BU_:  Airbag BAP_Tester ICAS1_Gateway ICAS1_KommunikationsServer LE1 LE2 Motor_BEV Schaltbetaetigung

BU_:  Airbag BAP_Tester ICAS1_Gateway ICAS1_KommunikationsServer LE1 LE2 Motor_BEV Schaltbetaetigung

BO_ 967 Motor_26: 8 Motor_BEV
 SG_ MO_Kuehlerluefter_MUX M : 0|1@1+ (1.000000,0.000000) [0.000000|1.000000] "siema ooo" ICAS1_Gateway
 SG_ MO_Kuehlerluefter_1 m0 : 1|7@1+ (1.000000,0.000000) [0.000000|100.000000] "Unit_PerCent" ICAS1_Gateway
 SG_ MO_Kuehlerluefter_2 m1 : 1|7@1+ (1.000000,0.000000) [0.000000|100.000000] "Unit_PerCent" ICAS1_Gateway
 SG_ MO_EFLEX_Lampe  : 8|2@1+ (1.000000,0.000000) [0.000000|3.000000] "" ICAS1_Gateway
 SG_ MO_KJS_nicht_bereit  : 10|1@1+ (1.000000,0.000000) [0.000000|1.000000] "" ICAS1_Gateway
 SG_ MO_ITM_Warnung_Pumpe  : 11|1@1+ (1.000000,0.000000) [0.000000|1.000000] "" ICAS1_Gateway
 SG_ WIV_Anzeige_aktiv  : 12|1@1+ (1.000000,0.000000) [0.000000|1.000000] "" ICAS1_Gateway
 SG_ WIV_Oelmin_Warn  : 13|1@1+ (1.000000,0.000000) [0.000000|1.000000] "" ICAS1_Gateway
 SG_ WIV_Sensorfehler  : 14|1@1+ (1.000000,0.000000) [0.000000|1.000000] "" ICAS1_Gateway
 SG_ WIV_Schieflage  : 15|1@1+ (1.000000,0.000000) [0.000000|1.000000] "" ICAS1_Gateway
 SG_ WIV_Oelstand  : 16|4@1+ (12.500000,0.000000) [0.000000|100.000000] "Unit_PerCent" ICAS1_Gateway
 SG_ MO_Zustand_HWP  : 20|2@1+ (1.000000,0.000000) [0.000000|3.000000] "" ICAS1_Gateway
 SG_ OLEV_Systemstoerung  : 22|1@1+ (1.000000,0.000000) [0.000000|1.000000] "" ICAS1_Gateway
 SG_ MO_Oelwarnung_max  : 23|1@1+ (1.000000,0.000000) [0.000000|1.000000] "" ICAS1_Gateway
 SG_ WIV_Oelsystem_aktiv  : 24|1@1+ (1.000000,0.000000) [0.000000|1.000000] "" ICAS1_Gateway
 SG_ WIV_nicht_betriebswarm  : 25|1@1+ (1.000000,0.000000) [0.000000|1.000000] "" ICAS1_Gateway
 SG_ WIV_Ueberfuell_Warn  : 26|1@1+ (1.000000,0.000000) [0.000000|1.000000] "" ICAS1_Gateway
 SG_ WIV_laufender_Motor  : 27|1@1+ (1.000000,0.000000) [0.000000|1.000000] "" ICAS1_Gateway
 SG_ MO_E_Warnungen  : 28|4@1+ (1.000000,0.000000) [0.000000|15.000000] "" ICAS1_Gateway
 SG_ MO_Text_Motorstart  : 32|4@1+ (1.000000,0.000000) [0.000000|15.000000] "" ICAS1_Gateway
 SG_ MO_E_Texte  : 36|4@1+ (1.000000,0.000000) [0.000000|15.000000] "" ICAS1_Gateway
 SG_ WIV_Oeldyn_avl  : 40|1@1+ (1.000000,0.000000) [0.000000|1.000000] "" ICAS1_Gateway
 SG_ MO_Text_Partikelfil_Reg  : 41|1@1+ (1.000000,0.000000) [0.000000|1.000000] "" ICAS1_Gateway
 SG_ OLEV_Oelstand_nicht_vorhanden  : 42|1@1+ (1.000000,0.000000) [0.000000|1.000000] "" ICAS1_Gateway
 SG_ WIV_Oelmenge  : 43|5@1+ (125.000000,0.000000) [0.000000|3875.000000] "Unit_MilliLiter" ICAS1_Gateway
 SG_ MO_Systemlampe  : 48|1@1+ (1.000000,0.000000) [0.000000|1.000000] "" ICAS1_Gateway
 SG_ MO_OBD2_Lampe  : 49|1@1+ (1.000000,0.000000) [0.000000|1.000000] "" ICAS1_Gateway
 SG_ MO_Heissleuchte  : 50|1@1+ (1.000000,0.000000) [0.000000|1.000000] "" ICAS1_Gateway
 SG_ MO_Partikel_Lampe  : 51|1@1+ (1.000000,0.000000) [0.000000|1.000000] "" ICAS1_Gateway
 SG_ MO_RedFahrleistung_Lampe  : 52|1@1+ (1.000000,0.000000) [0.000000|1.000000] "" ICAS1_Gateway ICAS1_KommunikationsServer
 SG_ WIV_Oelstand_nicht_vorhanden  : 53|1@1+ (1.000000,0.000000) [0.000000|1.000000] "" ICAS1_Gateway
 SG_ WIV_nachfuellanzeige_ein  : 54|1@1+ (1.000000,0.000000) [0.000000|1.000000] "" ICAS1_Gateway
 SG_ WIV_Ueberfuell_deaktiv  : 55|1@1+ (1.000000,0.000000) [0.000000|1.000000] "" ICAS1_Gateway
 SG_ WIV_Unterfuell_Warn  : 56|1@1+ (1.000000,0.000000) [0.000000|1.000000] "" ICAS1_Gateway
 SG_ MO_Tankdeckel_Lampe  : 57|1@1+ (1.000000,0.000000) [0.000000|1.000000] "" ICAS1_Gateway
 SG_ MO_Text_Tankdeckelwarn  : 58|1@1+ (1.000000,0.000000) [0.000000|1.000000] "" ICAS1_Gateway
 SG_ MO_Vorglueh_Lampe  : 59|1@1+ (1.000000,0.000000) [0.000000|1.000000] "" ICAS1_Gateway
 SG_ WIV_Oeldr_Warn_Motor  : 60|1@1+ (1.000000,0.000000) [0.000000|1.000000] "" ICAS1_Gateway
 SG_ MO_E_Mode  : 61|3@1+ (1.000000,0.000000) [0.000000|7.000000] "" ICAS1_Gateway

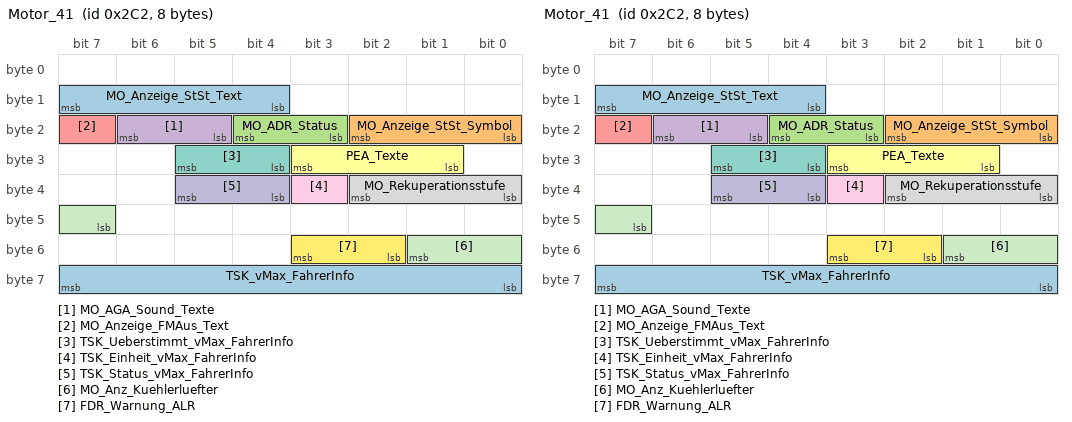
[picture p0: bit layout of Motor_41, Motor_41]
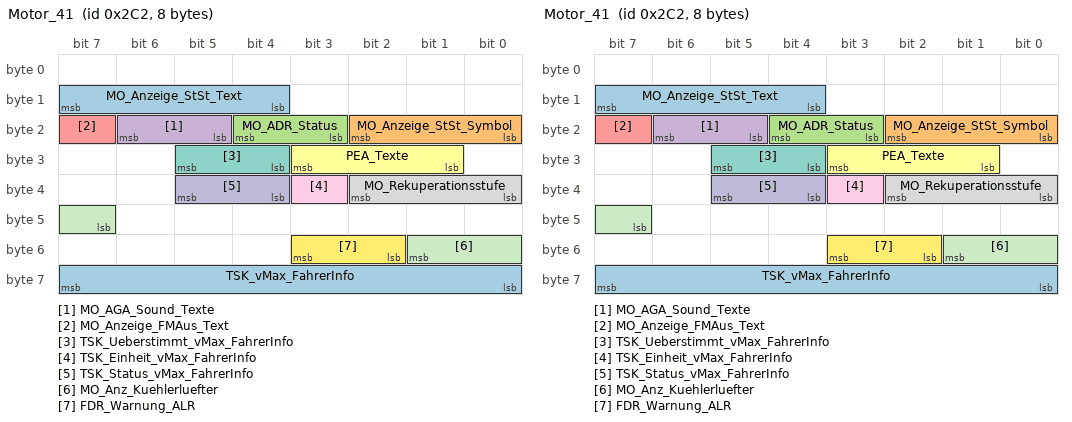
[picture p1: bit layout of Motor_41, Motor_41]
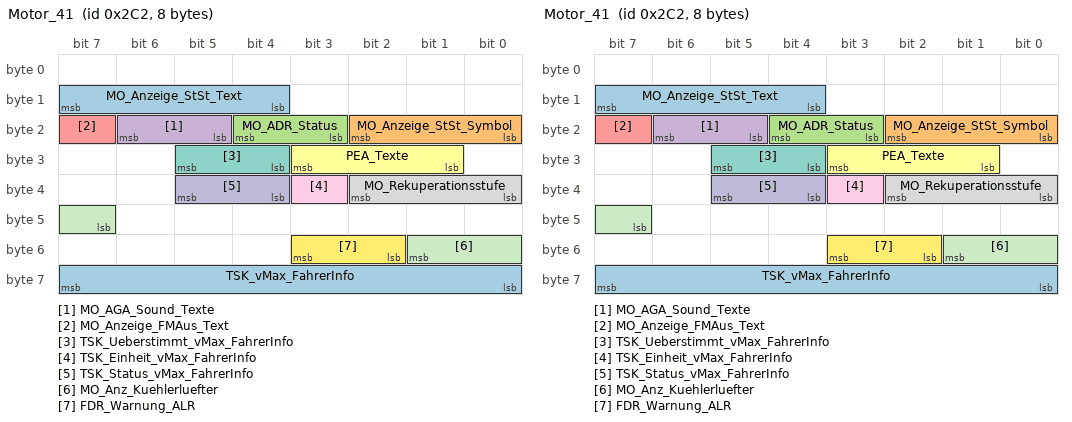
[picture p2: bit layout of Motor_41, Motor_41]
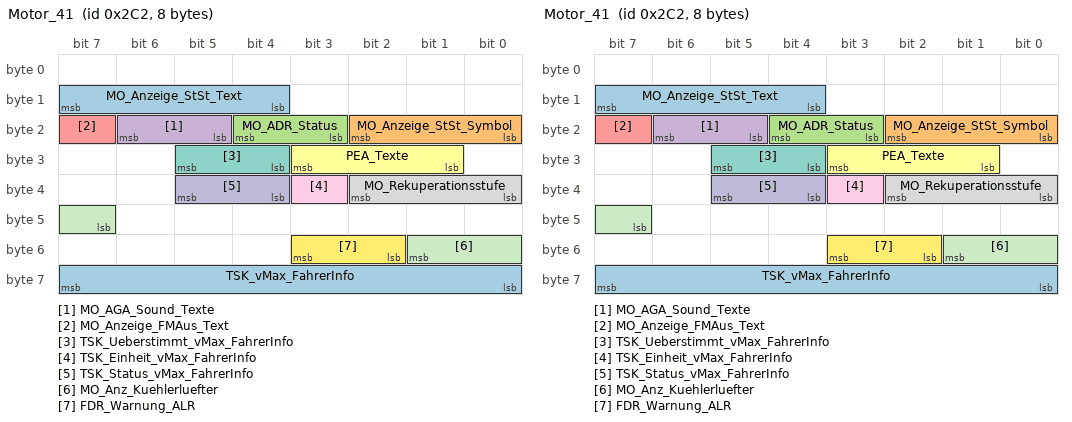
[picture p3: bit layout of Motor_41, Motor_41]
BO_ 706 Motor_41: 8 Motor_BEV
 SG_ MO_Anzeige_StSt_Text  : 12|4@1+ (1.000000,0.000000) [0.000000|15.000000] "" Vector__XXX
 SG_ MO_Anzeige_StSt_Symbol  : 16|3@1+ (1.000000,0.000000) [0.000000|7.000000] "" Vector__XXX
 SG_ MO_ADR_Status  : 19|2@1+ (1.000000,0.000000) [0.000000|3.000000] "" Vector__XXX
 SG_ MO_AGA_Sound_Texte  : 21|2@1+ (1.000000,0.000000) [0.000000|3.000000] "" Vector__XXX
 SG_ MO_Anzeige_FMAus_Text  : 23|1@1+ (1.000000,0.000000) [0.000000|1.000000] "" Vector__XXX
 SG_ PEA_Texte  : 25|3@1+ (1.000000,0.000000) [0.000000|7.000000] "" Vector__XXX
 SG_ TSK_Ueberstimmt_vMax_FahrerInfo  : 28|2@1+ (1.000000,0.000000) [0.000000|3.000000] "" Vector__XXX
 SG_ MO_Rekuperationsstufe  : 32|3@1+ (1.000000,0.000000) [0.000000|7.000000] "" ICAS1_KommunikationsServer
 SG_ TSK_Einheit_vMax_FahrerInfo  : 35|1@1+ (1.000000,0.000000) [0.000000|1.000000] "" ICAS1_KommunikationsServer
 SG_ TSK_Status_vMax_FahrerInfo  : 36|2@1+ (1.000000,0.000000) [0.000000|3.000000] "" ICAS1_KommunikationsServer
 SG_ MO_Anz_Kuehlerluefter  : 47|3@1+ (1.000000,0.000000) [0.000000|7.000000] "" Vector__XXX
 SG_ FDR_Warnung_ALR  : 50|2@1+ (1.000000,0.000000) [0.000000|3.000000] "" ICAS1_KommunikationsServer
 SG_ TSK_vMax_FahrerInfo  : 56|8@1+ (1.000000,15.000000) [16.000000|270.000000] "" ICAS1_KommunikationsServer

BO_ 267 Motor_51: 32 Motor_BEV
 SG_ Motor_51_CRC  : 0|8@1+ (1.000000,0.000000) [0.000000|255.000000] "" ICAS1_Gateway
 SG_ Motor_51_BZ  : 8|4@1+ (1.000000,0.000000) [0.000000|15.000000] "" ICAS1_Gateway
 SG_ MO_Fahrpedalrohwert_01  : 12|8@1+ (0.400000,0.000000) [0.000000|101.600000] "Unit_PerCent" Airbag ICAS1_Gateway
 SG_ MO_QBit_Fahrpedalwerte_01  : 20|1@1+ (1.000000,0.000000) [0.000000|1.000000] "" Airbag ICAS1_Gateway
 SG_ MO_Fahrpedalgradient  : 21|8@1+ (25.000000,0.000000) [0.000000|6350.000000] "Unit_PerCentPerSecon" ICAS1_Gateway
 SG_ MO_Sig_Fahrpedalgradient  : 29|1@1+ (1.000000,0.000000) [0.000000|1.000000] "" ICAS1_Gateway
 SG_ MO_rel_Saugrohrdruck  : 30|6@1+ (18.000000,0.000000) [0.000000|1116.000000] "Unit_MilliBar" ICAS1_Gateway
 SG_ MO_rel_Saugrohrdruck_gem_err  : 36|1@1+ (1.000000,0.000000) [0.000000|1.000000] "" ICAS1_Gateway
 SG_ MO_Moment_im_Leerlauf  : 37|1@1+ (1.000000,0.000000) [0.000000|1.000000] "" ICAS1_Gateway
 SG_ MO_Schubabschaltung  : 38|1@1+ (1.000000,0.000000) [0.000000|1.000000] "" ICAS1_Gateway
 SG_ MO_Solldrehz_Leerlauf  : 40|8@1+ (10.000000,0.000000) [0.000000|2540.000000] "Unit_MinutInver" ICAS1_Gateway
 SG_ MO_Entkopplung_Sollschlupf  : 48|7@1+ (20.000000,0.000000) [0.000000|2480.000000] "Unit_MinutInver" ICAS1_Gateway
 SG_ MO_temporaere_Fahrerabwesenheit  : 55|1@1+ (1.000000,0.000000) [0.000000|1.000000] "" ICAS1_Gateway
 SG_ TSK_a_Soll_gradientenbegrenzt  : 57|7@1+ (0.100000,-7.200000) [-7.200000|5.400000] "Unit_MeterPerSeconSquar" ICAS1_Gateway
 SG_ TSK_Radbremsmom  : 76|12@1+ (8.000000,0.000000) [0.000000|32760.000000] "Unit_NewtoMeter" ICAS1_Gateway
 SG_ TSK_Status  : 88|3@1+ (1.000000,0.000000) [0.000000|7.000000] "" ICAS1_Gateway
 SG_ TSK_v_Begrenzung_aktiv  : 91|1@1+ (1.000000,0.000000) [0.000000|1.000000] "" ICAS1_Gateway
 SG_ TSK_Standby_Anf_ESP  : 92|1@1+ (1.000000,0.000000) [0.000000|1.000000] "" ICAS1_Gateway
 SG_ TSK_Freig_WU  : 93|1@1+ (1.000000,0.000000) [0.000000|1.000000] "" ICAS1_Gateway
 SG_ TSK_Freig_Verzoeg_Anf  : 94|1@1+ (1.000000,0.000000) [0.000000|1.000000] "" ICAS1_Gateway
 SG_ TSK_Limiter_ausgewaehlt  : 95|1@1+ (1.000000,0.000000) [0.000000|1.000000] "" ICAS1_Gateway
 SG_ TSK_Wunsch_Uebersetz  : 96|10@1+ (0.024500,0.000000) [0.024500|25.063500] "" ICAS1_Gateway
 SG_ TSK_Hauptschalter_GRA_ACC  : 106|2@1+ (1.000000,0.000000) [0.000000|3.000000] "" ICAS1_Gateway ICAS1_KommunikationsServer
 SG_ TSK_SRBM_Anf_ASIL  : 108|3@1+ (1.000000,0.000000) [0.000000|7.000000] "" ICAS1_Gateway
 SG_ TSK_ax_Getriebe_02  : 112|9@1+ (0.024000,-2.016000) [-2.016000|10.224000] "Unit_MeterPerSeconSquar" ICAS1_Gateway
 SG_ TSK_Zwangszusch_ESP  : 121|1@1+ (1.000000,0.000000) [0.000000|1.000000] "" ICAS1_Gateway
 SG_ TSK_zul_Regelabw  : 122|6@1+ (0.024000,0.000000) [0.000000|1.512000] "Unit_MeterPerSeconSquar" ICAS1_Gateway
 SG_ MO_Status_MinDrzEingriff  : 235|3@1+ (1.000000,0.000000) [0.000000|7.000000] "" ICAS1_Gateway
 SG_ MO_Status_MaxDrzEingriff  : 238|3@1+ (1.000000,0.000000) [0.000000|7.000000] "" ICAS1_Gateway
 SG_ MO_Status_MinDrzEingriff_sek  : 241|3@1+ (1.000000,0.000000) [0.000000|7.000000] "" ICAS1_Gateway
 SG_ MO_Status_MaxDrzEingriff_sek  : 244|3@1+ (1.000000,0.000000) [0.000000|7.000000] "" ICAS1_Gateway
 SG_ GRA_KuFu_aktiv  : 247|1@1+ (1.000000,0.000000) [0.000000|1.000000] "" ICAS1_Gateway
 SG_ TSK_SRBM_max_Gradient  : 248|7@1+ (50.000000,0.000000) [0.000000|6250.000000] "Unit_NewtoMeterPerSecon" ICAS1_Gateway
 SG_ LIM_KuFu_aktiv  : 255|1@1+ (1.000000,0.000000) [0.000000|1.000000] "" ICAS1_Gateway

BO_ 330 Motor_52: 32 Motor_BEV
 SG_ MO_Hochschaltdrehz  : 21|12@1+ (3.000000,0.000000) [3.000000|12282.000000] "Unit_MinutInver" Vector__XXX
 SG_ MO_Anzeige_Verbr_Einheit  : 33|2@1+ (1.000000,0.000000) [0.000000|3.000000] "" Vector__XXX
 SG_ MO_Schaltblitz_Anz  : 35|7@1+ (1.000000,0.000000) [0.000000|100.000000] "Unit_PerCent" Vector__XXX
 SG_ MO_Anzeige_Drehmoment  : 42|11@1+ (1.000000,0.000000) [0.000000|2045.000000] "Unit_NewtoMeter" Vector__XXX
 SG_ MO_Anzeige_Leistung  : 53|11@1+ (0.600000,0.000000) [0.000000|1227.000000] "Unit_KiloWatt" Vector__XXX
 SG_ MO_rel_Ladedruck  : 64|8@1+ (0.400000,0.000000) [0.000000|100.000000] "Unit_PerCent" Vector__XXX
 SG_ MO_Istgang  : 72|4@1+ (1.000000,0.000000) [0.000000|15.000000] "" Vector__XXX
 SG_ MO_Sollgang  : 76|4@1+ (1.000000,0.000000) [0.000000|15.000000] "" Vector__XXX
 SG_ MO_Oeldruck  : 80|8@1+ (0.040000,0.000000) [0.000000|10.000000] "Unit_Bar" Vector__XXX
 SG_ MO_Anzeigedrehz  : 88|12@1+ (3.000000,0.000000) [0.000000|12282.000000] "Unit_MinutInver" Vector__XXX
 SG_ MO_Effizienzmodus  : 100|1@1+ (1.000000,0.000000) [0.000000|1.000000] "" Vector__XXX
 SG_ MO_Fehler_Oeldrucksensor  : 101|1@1+ (1.000000,0.000000) [0.000000|1.000000] "" Vector__XXX
 SG_ MO_Schaltempf_verfbar  : 102|1@1+ (1.000000,0.000000) [0.000000|1.000000] "" Vector__XXX
 SG_ MO_Ladedruck  : 103|9@1+ (0.010000,0.000000) [0.000000|5.100000] "Unit_Bar" Vector__XXX
 SG_ MO_KVS  : 112|15@1+ (1.000000,0.000000) [0.000000|32767.000000] "Unit_MicroLiter" Vector__XXX
 SG_ MO_KVS_Ueberlauf  : 127|1@1+ (1.000000,0.000000) [0.000000|1.000000] "" Vector__XXX
 SG_ MO_ePowermeter  : 128|8@1+ (0.400000,-0.400000) [0.000000|100.800000] "Unit_PerCent" Vector__XXX
 SG_ MO_ePerformance  : 136|8@1+ (0.400000,-0.400000) [0.000000|100.800000] "Unit_PerCent" ICAS1_KommunikationsServer
 SG_ MO_Zust_Antrieb  : 144|4@1+ (1.000000,0.000000) [0.000000|15.000000] "" Vector__XXX
 SG_ MO_Zust_Betriebsstrategie  : 148|3@1+ (1.000000,0.000000) [0.000000|7.000000] "" Vector__XXX
 SG_ Ladezustand_02  : 152|8@1+ (0.500000,0.000000) [0.000000|100.000000] "Unit_PerCent" ICAS1_Gateway ICAS1_KommunikationsServer
 SG_ MO_Powermeter_Elm_02  : 168|12@1+ (0.050000,-102.400000) [-100.000000|100.000000] "Unit_PerCent" Vector__XXX
 SG_ MO_Powermeter  : 180|12@1+ (1.000000,0.000000) [0.000000|4092.000000] "" ICAS1_KommunikationsServer

BO_ 512 Motor_53: 32 Motor_BEV
 SG_ TSK_Wunschgeschw  : 12|10@1+ (0.320000,0.000000) [0.000000|326.720000] "Unit_KiloMeterPerHour" ICAS1_Gateway ICAS1_KommunikationsServer
 SG_ TSK_praediktiver_Hinweis  : 22|3@1+ (1.000000,0.000000) [0.000000|7.000000] "" ICAS1_Gateway
 SG_ TSK_naechstes_Event  : 25|6@1+ (1.000000,0.000000) [0.000000|63.000000] "" ICAS1_Gateway
 SG_ TSK_Fahrzeugstatus_praed_Fkt  : 31|3@1+ (1.000000,0.000000) [0.000000|7.000000] "" ICAS1_Gateway
 SG_ TSK_Texte  : 40|5@1+ (1.000000,0.000000) [0.000000|31.000000] "" ICAS1_Gateway ICAS1_KommunikationsServer
 SG_ TSK_Akustik  : 45|3@1+ (1.000000,0.000000) [0.000000|7.000000] "" ICAS1_Gateway ICAS1_KommunikationsServer
 SG_ TSK_Texte_Primaeranz  : 48|5@1+ (1.000000,0.000000) [0.000000|31.000000] "" ICAS1_Gateway ICAS1_KommunikationsServer
 SG_ TSK_Limiter_Fahrerinfo  : 53|2@1+ (1.000000,0.000000) [0.000000|3.000000] "" ICAS1_Gateway ICAS1_KommunikationsServer
 SG_ TSK_Limiter_Anzeige  : 55|1@1+ (1.000000,0.000000) [0.000000|1.000000] "" ICAS1_Gateway ICAS1_KommunikationsServer
 SG_ TSK_Fahrzeugstatus_GRA  : 56|1@1+ (1.000000,0.000000) [0.000000|1.000000] "" ICAS1_Gateway ICAS1_KommunikationsServer
 SG_ TSK_Fahrzeugstatus_Limiter  : 57|1@1+ (1.000000,0.000000) [0.000000|1.000000] "" ICAS1_Gateway ICAS1_KommunikationsServer
 SG_ MO_Motorlaufwarnung  : 58|1@1+ (1.000000,0.000000) [0.000000|1.000000] "" ICAS1_Gateway
 SG_ TSK_naechstes_Event_Einheit  : 60|1@1+ (1.000000,0.000000) [0.000000|1.000000] "" ICAS1_Gateway
 SG_ TSK_Status_Anzeige  : 61|3@1+ (1.000000,0.000000) [0.000000|7.000000] "" ICAS1_Gateway ICAS1_KommunikationsServer
 SG_ MO_Sperrung_FahrPr_BZS  : 64|8@1+ (1.000000,0.000000) [0.000000|255.000000] "" ICAS1_Gateway
 SG_ MO_Rampenzeit_Generator_Anf  : 72|4@1+ (1.000000,0.000000) [0.000000|15.000000] "" ICAS1_Gateway
 SG_ MO_Prio_MAX_Wunschdrehzahl  : 76|1@1+ (1.000000,0.000000) [0.000000|1.000000] "" ICAS1_Gateway
 SG_ MO_Prio_MIN_Wunschdrehzahl  : 77|1@1+ (1.000000,0.000000) [0.000000|1.000000] "" ICAS1_Gateway
 SG_ MO_Luftpfad_aktiv  : 78|1@1+ (1.000000,0.000000) [0.000000|1.000000] "" ICAS1_Gateway
 SG_ MO_v_Begrenz_Aktivierbar  : 79|1@1+ (1.000000,0.000000) [0.000000|1.000000] "" ICAS1_Gateway
 SG_ MO_Drehzahlbeeinflussung  : 80|8@1+ (0.390000,0.000000) [0.000000|99.450000] "Unit_PerCent" ICAS1_Gateway
 SG_ MO_MIN_Wunschdrehzahl  : 88|8@1+ (25.000000,0.000000) [0.000000|6350.000000] "Unit_MinutInver" ICAS1_Gateway
 SG_ MO_MAX_Wunschdrehzahl  : 96|9@1+ (25.000000,0.000000) [0.000000|12750.000000] "Unit_MinutInver" ICAS1_Gateway
 SG_ MO_Charisma_FahrPr  : 105|4@1+ (1.000000,0.000000) [0.000000|15.000000] "" ICAS1_Gateway
 SG_ MO_Charisma_Status  : 109|2@1+ (1.000000,0.000000) [0.000000|3.000000] "" ICAS1_Gateway
 SG_ MO_StSt_Charisma_FahrPr  : 111|4@1+ (1.000000,0.000000) [0.000000|15.000000] "" ICAS1_Gateway
 SG_ MO_StSt_Charisma_Status  : 115|2@1+ (1.000000,0.000000) [0.000000|3.000000] "" ICAS1_Gateway
 SG_ MO_BZS_Charisma_FahrPr  : 117|4@1+ (1.000000,0.000000) [0.000000|15.000000] "" ICAS1_Gateway
 SG_ MO_BZS_Charisma_Status  : 121|2@1+ (1.000000,0.000000) [0.000000|3.000000] "" ICAS1_Gateway
 SG_ MO_NGS_Position  : 123|1@1+ (1.000000,0.000000) [0.000000|1.000000] "" ICAS1_Gateway
 SG_ MO_NGS_Status  : 124|2@1+ (1.000000,0.000000) [0.000000|3.000000] "" ICAS1_Gateway
 SG_ MO_v_Begrenzung_Niveau  : 126|2@1+ (1.000000,0.000000) [0.000000|3.000000] "" ICAS1_Gateway
 SG_ MO_Anzeige_Rekuperation  : 128|8@1+ (0.500000,-0.500000) [0.000000|100.000000] "Unit_PerCent" ICAS1_Gateway
 SG_ PEA_Fortschrittsanzeige  : 136|7@1+ (1.000000,0.000000) [0.000000|100.000000] "Unit_PerCent" ICAS1_Gateway
 SG_ MO_Anzeige_Fahrbereitschaft  : 143|1@1+ (1.000000,0.000000) [0.000000|1.000000] "" ICAS1_Gateway ICAS1_KommunikationsServer
 SG_ MO_Boost_verfuegbar  : 144|8@1+ (0.400000,-0.400000) [0.000000|100.400000] "Unit_PerCent" ICAS1_Gateway
 SG_ MO_Overboost  : 152|1@1+ (1.000000,0.000000) [0.000000|1.000000] "" ICAS1_Gateway
 SG_ MO_Boost_aktiv  : 153|1@1+ (1.000000,0.000000) [0.000000|1.000000] "" ICAS1_Gateway
 SG_ MO_Anzeige_Betriebsmodus  : 154|4@1+ (1.000000,0.000000) [0.000000|15.000000] "" ICAS1_Gateway
 SG_ PEA_Hinweis  : 158|2@1+ (1.000000,0.000000) [0.000000|3.000000] "" ICAS1_Gateway
 SG_ PEA_Ereignisanzeige  : 160|5@1+ (1.000000,0.000000) [0.000000|31.000000] "" ICAS1_Gateway
 SG_ PEA_Ereignisanzeige_temporaer  : 165|1@1+ (1.000000,0.000000) [0.000000|1.000000] "" ICAS1_Gateway
 SG_ PEA_Abschalttexte  : 166|2@1+ (1.000000,0.000000) [0.000000|3.000000] "" ICAS1_Gateway
 SG_ PEA_Zielgeschw_Einheit  : 168|1@1+ (1.000000,0.000000) [0.000000|1.000000] "" ICAS1_Gateway
 SG_ PEA_Zielgeschw  : 169|5@1+ (1.000000,0.000000) [0.000000|31.000000] "" ICAS1_Gateway
 SG_ MO_Antriebsstrang_Warnung_HS  : 174|2@1+ (1.000000,0.000000) [0.000000|3.000000] "" ICAS1_Gateway
 SG_ MO_Anzeige_Verbrauch_oE  : 176|16@1+ (0.005000,0.000000) [0.000000|327.675000] "Unit_None" ICAS1_Gateway

BO_ 332 Motor_54: 32 Motor_BEV
 SG_ MO_Anforderung_HMS  : 12|3@1+ (1.000000,0.000000) [0.000000|7.000000] "" ICAS1_Gateway
 SG_ FoD_DTC_TSK_GRA  : 15|1@1+ (1.000000,0.000000) [0.000000|1.000000] "" ICAS1_Gateway
 SG_ TSK_vMax_aktuell  : 16|8@1+ (1.000000,0.000000) [0.000000|253.000000] "Unit_KiloMeterPerHour" ICAS1_Gateway
 SG_ TSK_Status_EA  : 32|3@1+ (1.000000,0.000000) [0.000000|7.000000] "" ICAS1_Gateway
 SG_ FoD_DTC_TSK_ACC  : 35|1@1+ (1.000000,0.000000) [0.000000|1.000000] "" ICAS1_Gateway
 SG_ TSK_ACC_FoD_Status  : 36|2@1+ (1.000000,0.000000) [0.000000|3.000000] "" ICAS1_Gateway
 SG_ TSK_GRA_FoD_Status  : 38|2@1+ (1.000000,0.000000) [0.000000|3.000000] "" ICAS1_Gateway
 SG_ TSK_vMax_Fahrerassistenz  : 40|9@1+ (1.000000,0.000000) [0.000000|510.000000] "" ICAS1_Gateway
 SG_ TSK_Einheit_vMax_Fahrerassistenz  : 49|1@1+ (1.000000,0.000000) [0.000000|1.000000] "" ICAS1_Gateway
 SG_ TSK_Status_PLA  : 50|3@1+ (1.000000,0.000000) [0.000000|7.000000] "" ICAS1_Gateway
 SG_ TSK_aktives_System  : 53|3@1+ (1.000000,0.000000) [0.000000|7.000000] "" ICAS1_Gateway
 SG_ TSK_erhoehter_Fahrwiderstand  : 56|1@1+ (1.000000,0.000000) [0.000000|1.000000] "" ICAS1_Gateway
 SG_ TSK_Anf_Antriebsmoment  : 57|1@1+ (1.000000,0.000000) [0.000000|1.000000] "" ICAS1_Gateway
 SG_ TSK_Status_ARA  : 58|3@1+ (1.000000,0.000000) [0.000000|7.000000] "" ICAS1_Gateway
 SG_ TSK_Status_IPA  : 61|3@1+ (1.000000,0.000000) [0.000000|7.000000] "" ICAS1_Gateway
 SG_ MO_Fahrbereitschaft  : 76|2@1+ (1.000000,0.000000) [0.000000|3.000000] "" ICAS1_Gateway LE1 LE2
 SG_ MO_Freilauf_Info  : 78|2@1+ (1.000000,0.000000) [0.000000|3.000000] "" ICAS1_Gateway
 SG_ MO_Krit_Heckobjekt  : 81|3@1+ (1.000000,0.000000) [0.000000|7.000000] "" ICAS1_Gateway
 SG_ MO_NGS_Gangpos  : 84|3@1+ (1.000000,0.000000) [0.000000|7.000000] "" ICAS1_Gateway
 SG_ MO_Freilauf_Status  : 87|3@1+ (1.000000,0.000000) [0.000000|7.000000] "" ICAS1_Gateway
 SG_ MO_EBoost_verf_praed  : 90|2@1+ (1.000000,0.000000) [0.000000|3.000000] "" ICAS1_Gateway
 SG_ MO_Heckspoiler_Anf  : 92|1@1+ (1.000000,0.000000) [0.000000|1.000000] "" ICAS1_Gateway
 SG_ MO_eLaunch_verf  : 93|2@1+ (1.000000,0.000000) [0.000000|3.000000] "" ICAS1_Gateway
 SG_ MO_Positionierung_aktiv  : 95|1@1+ (1.000000,0.000000) [0.000000|1.000000] "" ICAS1_Gateway
 SG_ MO_Freilauf_Typ  : 98|2@1+ (1.000000,0.000000) [0.000000|3.000000] "" ICAS1_Gateway
 SG_ MO_Startwunsch  : 100|1@1+ (1.000000,0.000000) [0.000000|1.000000] "" ICAS1_Gateway
 SG_ OBD_Calc_Load_Val  : 128|8@1+ (0.392157,0.000000) [0.000000|100.000000] "Unit_PerCent" ICAS1_Gateway LE1 LE2
 SG_ OBD_Eng_Cool_Temp  : 136|8@1+ (1.000000,-40.000000) [-40.000000|215.000000] "Unit_DegreCelsi" ICAS1_Gateway LE1 LE2
 SG_ OBD_Abs_Throttle_Pos  : 144|8@1+ (0.392157,0.000000) [0.000000|100.000000] "Unit_PerCent" ICAS1_Gateway LE1 LE2
 SG_ OBD_Abs_Load_Val  : 152|16@1+ (0.392157,0.000000) [0.000000|25700.000000] "Unit_PerCent" ICAS1_Gateway LE1 LE2
 SG_ OBD_Abs_Pedal_Pos  : 168|8@1+ (0.392157,0.000000) [0.000000|100.000000] "Unit_PerCent" ICAS1_Gateway LE1 LE2
 SG_ MO_Servicemodus  : 176|4@1+ (1.000000,0.000000) [0.000000|15.000000] "" ICAS1_Gateway LE1 LE2
 SG_ OBD_ClearMem_Inhibit  : 183|1@1+ (1.000000,0.000000) [0.000000|1.000000] "" ICAS1_Gateway LE1 LE2
 SG_ OBD_Sperrung_Kaltstart_Denom  : 184|1@1+ (1.000000,0.000000) [0.000000|1.000000] "" ICAS1_Gateway LE1 LE2
 SG_ MO_QBit_Aussen_Temp  : 185|1@1+ (1.000000,0.000000) [0.000000|1.000000] "" ICAS1_Gateway
 SG_ OBD_Sperrung_IUMPR  : 186|1@1+ (1.000000,0.000000) [0.000000|1.000000] "" ICAS1_Gateway LE1 LE2
 SG_ OBD_Kaltstart_Denominator  : 187|1@1+ (1.000000,0.000000) [0.000000|1.000000] "" ICAS1_Gateway LE1 LE2
 SG_ OBD_Minimum_Trip  : 188|1@1+ (1.000000,0.000000) [0.000000|1.000000] "" ICAS1_Gateway LE1 LE2
 SG_ OBD_Driving_Cycle  : 189|1@1+ (1.000000,0.000000) [0.000000|1.000000] "" ICAS1_Gateway LE1 LE2
 SG_ OBD_Warm_Up_Cycle  : 190|1@1+ (1.000000,0.000000) [0.000000|1.000000] "" ICAS1_Gateway LE1 LE2
 SG_ OBD_Normed_Trip  : 191|1@1+ (1.000000,0.000000) [0.000000|1.000000] "" ICAS1_Gateway LE1 LE2
 SG_ OBD_Aussen_Temp_gef  : 248|8@1+ (1.000000,-40.000000) [-40.000000|213.000000] "Unit_DegreCelsi" ICAS1_Gateway

BO_ 246 Motor_55: 32 Motor_BEV
 SG_ Motor_55_CRC  : 0|8@1+ (1.000000,0.000000) [0.000000|255.000000] "" ICAS1_Gateway
 SG_ Motor_55_BZ  : 8|4@1+ (1.000000,0.000000) [0.000000|15.000000] "" ICAS1_Gateway
 SG_ TS_Faktor_Radmomente  : 12|2@1+ (1.000000,0.000000) [0.000000|3.000000] "" ICAS1_Gateway
 SG_ TS_Status_MomRad_Ist  : 14|2@1+ (1.000000,0.000000) [0.000000|3.000000] "" ICAS1_Gateway
 SG_ TS_MomRad_verfuegb_maxReku_Summe  : 16|12@1+ (3.000000,-12279.000000) [-12279.000000|0.000000] "" ICAS1_Gateway
 SG_ TS_MomRad_Ist  : 28|13@1+ (3.000000,-12279.000000) [-12279.000000|12279.000000] "Unit_None" ICAS1_Gateway
 SG_ TS_MomRad_Soll_Summe  : 41|13@1+ (3.000000,-12279.000000) [-12279.000000|12279.000000] "Unit_None" ICAS1_Gateway
 SG_ TS_MomRad_Wunsch  : 54|13@1+ (3.000000,-12279.000000) [-12279.000000|12279.000000] "Unit_None" ICAS1_Gateway
 SG_ TS_MomRad_Wunsch_sek  : 67|13@1+ (3.000000,-12279.000000) [-12279.000000|12279.000000] "Unit_None" ICAS1_Gateway
 SG_ TS_MomRad_verfuegb_max  : 80|12@1+ (3.000000,0.000000) [0.000000|12279.000000] "Unit_None" ICAS1_Gateway
 SG_ TS_MomRad_verfuegb_max_sek  : 92|12@1+ (3.000000,0.000000) [0.000000|12279.000000] "Unit_None" ICAS1_Gateway
 SG_ TS_MomRad_verfuegb_maxReku  : 104|12@1+ (3.000000,-12279.000000) [-12279.000000|0.000000] "Unit_None" ICAS1_Gateway
 SG_ TS_MomRad_verfuegb_maxReku_sek  : 116|12@1+ (3.000000,-12279.000000) [-12279.000000|0.000000] "Unit_None" ICAS1_Gateway
 SG_ TS_MomRad_Ist_sek  : 128|13@1+ (3.000000,-12279.000000) [-12279.000000|12279.000000] "Unit_None" ICAS1_Gateway
 SG_ TS_Allrad_Anteil_sek  : 141|9@1+ (0.200000,0.000000) [0.000000|100.000000] "Unit_PerCent" ICAS1_Gateway
 SG_ FDR_Allrad_Anteil_max_sek  : 150|9@1+ (0.200000,0.000000) [0.000000|100.000000] "Unit_PerCent" ICAS1_Gateway
 SG_ FDR_Allrad_Anteil_min_sek  : 159|9@1+ (0.200000,0.000000) [0.000000|100.000000] "Unit_PerCent" ICAS1_Gateway
 SG_ FDR_MomRad_Eingriff  : 168|13@1+ (3.000000,-12279.000000) [-12279.000000|12279.000000] "Unit_NewtoMeter" ICAS1_Gateway
 SG_ FDR_Status_Eingriff  : 181|1@1+ (1.000000,0.000000) [0.000000|1.000000] "" ICAS1_Gateway
 SG_ FDR_MomRad_Eingriff_sek  : 182|13@1+ (3.000000,-12279.000000) [-12279.000000|12279.000000] "Unit_NewtoMeter" ICAS1_Gateway
 SG_ FDR_Status_Eingriff_sek  : 195|1@1+ (1.000000,0.000000) [0.000000|1.000000] "" ICAS1_Gateway

BU_:  Airbag BAP_Tester ICAS1_Gateway ICAS1_KommunikationsServer LE1 LE2 Motor_BEV Schaltbetaetigung

BO_ 967 Motor_26: 8 Motor_BEV
 SG_ MO_Kuehlerluefter_MUX M : 0|1@1+ (1.000000,0.000000) [0.000000|1.000000] "siema ooo" ICAS1_Gateway
 SG_ MO_Kuehlerluefter_1 m0 : 1|7@1+ (1.000000,0.000000) [0.000000|100.000000] "Unit_PerCent" ICAS1_Gateway
 SG_ MO_Kuehlerluefter_2 m1 : 1|7@1+ (1.000000,0.000000) [0.000000|100.000000] "Unit_PerCent" ICAS1_Gateway
 SG_ MO_EFLEX_Lampe  : 8|2@1+ (1.000000,0.000000) [0.000000|3.000000] "" ICAS1_Gateway
 SG_ MO_KJS_nicht_bereit  : 10|1@1+ (1.000000,0.000000) [0.000000|1.000000] "" ICAS1_Gateway
 SG_ MO_ITM_Warnung_Pumpe  : 11|1@1+ (1.000000,0.000000) [0.000000|1.000000] "" ICAS1_Gateway
 SG_ WIV_Anzeige_aktiv  : 12|1@1+ (1.000000,0.000000) [0.000000|1.000000] "" ICAS1_Gateway
 SG_ WIV_Oelmin_Warn  : 13|1@1+ (1.000000,0.000000) [0.000000|1.000000] "" ICAS1_Gateway
 SG_ WIV_Sensorfehler  : 14|1@1+ (1.000000,0.000000) [0.000000|1.000000] "" ICAS1_Gateway
 SG_ WIV_Schieflage  : 15|1@1+ (1.000000,0.000000) [0.000000|1.000000] "" ICAS1_Gateway
 SG_ WIV_Oelstand  : 16|4@1+ (12.500000,0.000000) [0.000000|100.000000] "Unit_PerCent" ICAS1_Gateway
 SG_ MO_Zustand_HWP  : 20|2@1+ (1.000000,0.000000) [0.000000|3.000000] "" ICAS1_Gateway
 SG_ OLEV_Systemstoerung  : 22|1@1+ (1.000000,0.000000) [0.000000|1.000000] "" ICAS1_Gateway
 SG_ MO_Oelwarnung_max  : 23|1@1+ (1.000000,0.000000) [0.000000|1.000000] "" ICAS1_Gateway
 SG_ WIV_Oelsystem_aktiv  : 24|1@1+ (1.000000,0.000000) [0.000000|1.000000] "" ICAS1_Gateway
 SG_ WIV_nicht_betriebswarm  : 25|1@1+ (1.000000,0.000000) [0.000000|1.000000] "" ICAS1_Gateway
 SG_ WIV_Ueberfuell_Warn  : 26|1@1+ (1.000000,0.000000) [0.000000|1.000000] "" ICAS1_Gateway
 SG_ WIV_laufender_Motor  : 27|1@1+ (1.000000,0.000000) [0.000000|1.000000] "" ICAS1_Gateway
 SG_ MO_E_Warnungen  : 28|4@1+ (1.000000,0.000000) [0.000000|15.000000] "" ICAS1_Gateway
 SG_ MO_Text_Motorstart  : 32|4@1+ (1.000000,0.000000) [0.000000|15.000000] "" ICAS1_Gateway
 SG_ MO_E_Texte  : 36|4@1+ (1.000000,0.000000) [0.000000|15.000000] "" ICAS1_Gateway
 SG_ WIV_Oeldyn_avl  : 40|1@1+ (1.000000,0.000000) [0.000000|1.000000] "" ICAS1_Gateway
 SG_ MO_Text_Partikelfil_Reg  : 41|1@1+ (1.000000,0.000000) [0.000000|1.000000] "" ICAS1_Gateway
 SG_ OLEV_Oelstand_nicht_vorhanden  : 42|1@1+ (1.000000,0.000000) [0.000000|1.000000] "" ICAS1_Gateway
 SG_ WIV_Oelmenge  : 43|5@1+ (125.000000,0.000000) [0.000000|3875.000000] "Unit_MilliLiter" ICAS1_Gateway
 SG_ MO_Systemlampe  : 48|1@1+ (1.000000,0.000000) [0.000000|1.000000] "" ICAS1_Gateway
 SG_ MO_OBD2_Lampe  : 49|1@1+ (1.000000,0.000000) [0.000000|1.000000] "" ICAS1_Gateway
 SG_ MO_Heissleuchte  : 50|1@1+ (1.000000,0.000000) [0.000000|1.000000] "" ICAS1_Gateway
 SG_ MO_Partikel_Lampe  : 51|1@1+ (1.000000,0.000000) [0.000000|1.000000] "" ICAS1_Gateway
 SG_ MO_RedFahrleistung_Lampe  : 52|1@1+ (1.000000,0.000000) [0.000000|1.000000] "" ICAS1_Gateway ICAS1_KommunikationsServer
 SG_ WIV_Oelstand_nicht_vorhanden  : 53|1@1+ (1.000000,0.000000) [0.000000|1.000000] "" ICAS1_Gateway
 SG_ WIV_nachfuellanzeige_ein  : 54|1@1+ (1.000000,0.000000) [0.000000|1.000000] "" ICAS1_Gateway
 SG_ WIV_Ueberfuell_deaktiv  : 55|1@1+ (1.000000,0.000000) [0.000000|1.000000] "" ICAS1_Gateway
 SG_ WIV_Unterfuell_Warn  : 56|1@1+ (1.000000,0.000000) [0.000000|1.000000] "" ICAS1_Gateway
 SG_ MO_Tankdeckel_Lampe  : 57|1@1+ (1.000000,0.000000) [0.000000|1.000000] "" ICAS1_Gateway
 SG_ MO_Text_Tankdeckelwarn  : 58|1@1+ (1.000000,0.000000) [0.000000|1.000000] "" ICAS1_Gateway
 SG_ MO_Vorglueh_Lampe  : 59|1@1+ (1.000000,0.000000) [0.000000|1.000000] "" ICAS1_Gateway
 SG_ WIV_Oeldr_Warn_Motor  : 60|1@1+ (1.000000,0.000000) [0.000000|1.000000] "" ICAS1_Gateway
 SG_ MO_E_Mode  : 61|3@1+ (1.000000,0.000000) [0.000000|7.000000] "" ICAS1_Gateway

BO_ 706 Motor_41: 8 Motor_BEV
 SG_ MO_Anzeige_StSt_Text  : 12|4@1+ (1.000000,0.000000) [0.000000|15.000000] "" Vector__XXX
 SG_ MO_Anzeige_StSt_Symbol  : 16|3@1+ (1.000000,0.000000) [0.000000|7.000000] "" Vector__XXX
 SG_ MO_ADR_Status  : 19|2@1+ (1.000000,0.000000) [0.000000|3.000000] "" Vector__XXX
 SG_ MO_AGA_Sound_Texte  : 21|2@1+ (1.000000,0.000000) [0.000000|3.000000] "" Vector__XXX
 SG_ MO_Anzeige_FMAus_Text  : 23|1@1+ (1.000000,0.000000) [0.000000|1.000000] "" Vector__XXX
 SG_ PEA_Texte  : 25|3@1+ (1.000000,0.000000) [0.000000|7.000000] "" Vector__XXX
 SG_ TSK_Ueberstimmt_vMax_FahrerInfo  : 28|2@1+ (1.000000,0.000000) [0.000000|3.000000] "" Vector__XXX
 SG_ MO_Rekuperationsstufe  : 32|3@1+ (1.000000,0.000000) [0.000000|7.000000] "" ICAS1_KommunikationsServer
 SG_ TSK_Einheit_vMax_FahrerInfo  : 35|1@1+ (1.000000,0.000000) [0.000000|1.000000] "" ICAS1_KommunikationsServer
 SG_ TSK_Status_vMax_FahrerInfo  : 36|2@1+ (1.000000,0.000000) [0.000000|3.000000] "" ICAS1_KommunikationsServer
 SG_ MO_Anz_Kuehlerluefter  : 47|3@1+ (1.000000,0.000000) [0.000000|7.000000] "" Vector__XXX
 SG_ FDR_Warnung_ALR  : 50|2@1+ (1.000000,0.000000) [0.000000|3.000000] "" ICAS1_KommunikationsServer
 SG_ TSK_vMax_FahrerInfo  : 56|8@1+ (1.000000,15.000000) [16.000000|270.000000] "" ICAS1_KommunikationsServer

BO_ 267 Motor_51: 32 Motor_BEV
 SG_ Motor_51_CRC  : 0|8@1+ (1.000000,0.000000) [0.000000|255.000000] "" ICAS1_Gateway
 SG_ Motor_51_BZ  : 8|4@1+ (1.000000,0.000000) [0.000000|15.000000] "" ICAS1_Gateway
 SG_ MO_Fahrpedalrohwert_01  : 12|8@1+ (0.400000,0.000000) [0.000000|101.600000] "Unit_PerCent" Airbag ICAS1_Gateway
 SG_ MO_QBit_Fahrpedalwerte_01  : 20|1@1+ (1.000000,0.000000) [0.000000|1.000000] "" Airbag ICAS1_Gateway
 SG_ MO_Fahrpedalgradient  : 21|8@1+ (25.000000,0.000000) [0.000000|6350.000000] "Unit_PerCentPerSecon" ICAS1_Gateway
 SG_ MO_Sig_Fahrpedalgradient  : 29|1@1+ (1.000000,0.000000) [0.000000|1.000000] "" ICAS1_Gateway
 SG_ MO_rel_Saugrohrdruck  : 30|6@1+ (18.000000,0.000000) [0.000000|1116.000000] "Unit_MilliBar" ICAS1_Gateway
 SG_ MO_rel_Saugrohrdruck_gem_err  : 36|1@1+ (1.000000,0.000000) [0.000000|1.000000] "" ICAS1_Gateway
 SG_ MO_Moment_im_Leerlauf  : 37|1@1+ (1.000000,0.000000) [0.000000|1.000000] "" ICAS1_Gateway
 SG_ MO_Schubabschaltung  : 38|1@1+ (1.000000,0.000000) [0.000000|1.000000] "" ICAS1_Gateway
 SG_ MO_Solldrehz_Leerlauf  : 40|8@1+ (10.000000,0.000000) [0.000000|2540.000000] "Unit_MinutInver" ICAS1_Gateway
 SG_ MO_Entkopplung_Sollschlupf  : 48|7@1+ (20.000000,0.000000) [0.000000|2480.000000] "Unit_MinutInver" ICAS1_Gateway
 SG_ MO_temporaere_Fahrerabwesenheit  : 55|1@1+ (1.000000,0.000000) [0.000000|1.000000] "" ICAS1_Gateway
 SG_ TSK_a_Soll_gradientenbegrenzt  : 57|7@1+ (0.100000,-7.200000) [-7.200000|5.400000] "Unit_MeterPerSeconSquar" ICAS1_Gateway
 SG_ TSK_Radbremsmom  : 76|12@1+ (8.000000,0.000000) [0.000000|32760.000000] "Unit_NewtoMeter" ICAS1_Gateway
 SG_ TSK_Status  : 88|3@1+ (1.000000,0.000000) [0.000000|7.000000] "" ICAS1_Gateway
 SG_ TSK_v_Begrenzung_aktiv  : 91|1@1+ (1.000000,0.000000) [0.000000|1.000000] "" ICAS1_Gateway
 SG_ TSK_Standby_Anf_ESP  : 92|1@1+ (1.000000,0.000000) [0.000000|1.000000] "" ICAS1_Gateway
 SG_ TSK_Freig_WU  : 93|1@1+ (1.000000,0.000000) [0.000000|1.000000] "" ICAS1_Gateway
 SG_ TSK_Freig_Verzoeg_Anf  : 94|1@1+ (1.000000,0.000000) [0.000000|1.000000] "" ICAS1_Gateway
 SG_ TSK_Limiter_ausgewaehlt  : 95|1@1+ (1.000000,0.000000) [0.000000|1.000000] "" ICAS1_Gateway
 SG_ TSK_Wunsch_Uebersetz  : 96|10@1+ (0.024500,0.000000) [0.024500|25.063500] "" ICAS1_Gateway
 SG_ TSK_Hauptschalter_GRA_ACC  : 106|2@1+ (1.000000,0.000000) [0.000000|3.000000] "" ICAS1_Gateway ICAS1_KommunikationsServer
 SG_ TSK_SRBM_Anf_ASIL  : 108|3@1+ (1.000000,0.000000) [0.000000|7.000000] "" ICAS1_Gateway
 SG_ TSK_ax_Getriebe_02  : 112|9@1+ (0.024000,-2.016000) [-2.016000|10.224000] "Unit_MeterPerSeconSquar" ICAS1_Gateway
 SG_ TSK_Zwangszusch_ESP  : 121|1@1+ (1.000000,0.000000) [0.000000|1.000000] "" ICAS1_Gateway
 SG_ TSK_zul_Regelabw  : 122|6@1+ (0.024000,0.000000) [0.000000|1.512000] "Unit_MeterPerSeconSquar" ICAS1_Gateway
 SG_ MO_Status_MinDrzEingriff  : 235|3@1+ (1.000000,0.000000) [0.000000|7.000000] "" ICAS1_Gateway
 SG_ MO_Status_MaxDrzEingriff  : 238|3@1+ (1.000000,0.000000) [0.000000|7.000000] "" ICAS1_Gateway
 SG_ MO_Status_MinDrzEingriff_sek  : 241|3@1+ (1.000000,0.000000) [0.000000|7.000000] "" ICAS1_Gateway
 SG_ MO_Status_MaxDrzEingriff_sek  : 244|3@1+ (1.000000,0.000000) [0.000000|7.000000] "" ICAS1_Gateway
 SG_ GRA_KuFu_aktiv  : 247|1@1+ (1.000000,0.000000) [0.000000|1.000000] "" ICAS1_Gateway
 SG_ TSK_SRBM_max_Gradient  : 248|7@1+ (50.000000,0.000000) [0.000000|6250.000000] "Unit_NewtoMeterPerSecon" ICAS1_Gateway
 SG_ LIM_KuFu_aktiv  : 255|1@1+ (1.000000,0.000000) [0.000000|1.000000] "" ICAS1_Gateway

BO_ 330 Motor_52: 32 Motor_BEV
 SG_ MO_Hochschaltdrehz  : 21|12@1+ (3.000000,0.000000) [3.000000|12282.000000] "Unit_MinutInver" Vector__XXX
 SG_ MO_Anzeige_Verbr_Einheit  : 33|2@1+ (1.000000,0.000000) [0.000000|3.000000] "" Vector__XXX
 SG_ MO_Schaltblitz_Anz  : 35|7@1+ (1.000000,0.000000) [0.000000|100.000000] "Unit_PerCent" Vector__XXX
 SG_ MO_Anzeige_Drehmoment  : 42|11@1+ (1.000000,0.000000) [0.000000|2045.000000] "Unit_NewtoMeter" Vector__XXX
 SG_ MO_Anzeige_Leistung  : 53|11@1+ (0.600000,0.000000) [0.000000|1227.000000] "Unit_KiloWatt" Vector__XXX
 SG_ MO_rel_Ladedruck  : 64|8@1+ (0.400000,0.000000) [0.000000|100.000000] "Unit_PerCent" Vector__XXX
 SG_ MO_Istgang  : 72|4@1+ (1.000000,0.000000) [0.000000|15.000000] "" Vector__XXX
 SG_ MO_Sollgang  : 76|4@1+ (1.000000,0.000000) [0.000000|15.000000] "" Vector__XXX
 SG_ MO_Oeldruck  : 80|8@1+ (0.040000,0.000000) [0.000000|10.000000] "Unit_Bar" Vector__XXX
 SG_ MO_Anzeigedrehz  : 88|12@1+ (3.000000,0.000000) [0.000000|12282.000000] "Unit_MinutInver" Vector__XXX
 SG_ MO_Effizienzmodus  : 100|1@1+ (1.000000,0.000000) [0.000000|1.000000] "" Vector__XXX
 SG_ MO_Fehler_Oeldrucksensor  : 101|1@1+ (1.000000,0.000000) [0.000000|1.000000] "" Vector__XXX
 SG_ MO_Schaltempf_verfbar  : 102|1@1+ (1.000000,0.000000) [0.000000|1.000000] "" Vector__XXX
 SG_ MO_Ladedruck  : 103|9@1+ (0.010000,0.000000) [0.000000|5.100000] "Unit_Bar" Vector__XXX
 SG_ MO_KVS  : 112|15@1+ (1.000000,0.000000) [0.000000|32767.000000] "Unit_MicroLiter" Vector__XXX
 SG_ MO_KVS_Ueberlauf  : 127|1@1+ (1.000000,0.000000) [0.000000|1.000000] "" Vector__XXX
 SG_ MO_ePowermeter  : 128|8@1+ (0.400000,-0.400000) [0.000000|100.800000] "Unit_PerCent" Vector__XXX
 SG_ MO_ePerformance  : 136|8@1+ (0.400000,-0.400000) [0.000000|100.800000] "Unit_PerCent" ICAS1_KommunikationsServer
 SG_ MO_Zust_Antrieb  : 144|4@1+ (1.000000,0.000000) [0.000000|15.000000] "" Vector__XXX
 SG_ MO_Zust_Betriebsstrategie  : 148|3@1+ (1.000000,0.000000) [0.000000|7.000000] "" Vector__XXX
 SG_ Ladezustand_02  : 152|8@1+ (0.500000,0.000000) [0.000000|100.000000] "Unit_PerCent" ICAS1_Gateway ICAS1_KommunikationsServer
 SG_ MO_Powermeter_Elm_02  : 168|12@1+ (0.050000,-102.400000) [-100.000000|100.000000] "Unit_PerCent" Vector__XXX
 SG_ MO_Powermeter  : 180|12@1+ (1.000000,0.000000) [0.000000|4092.000000] "" ICAS1_KommunikationsServer

BO_ 512 Motor_53: 32 Motor_BEV
 SG_ TSK_Wunschgeschw  : 12|10@1+ (0.320000,0.000000) [0.000000|326.720000] "Unit_KiloMeterPerHour" ICAS1_Gateway ICAS1_KommunikationsServer
 SG_ TSK_praediktiver_Hinweis  : 22|3@1+ (1.000000,0.000000) [0.000000|7.000000] "" ICAS1_Gateway
 SG_ TSK_naechstes_Event  : 25|6@1+ (1.000000,0.000000) [0.000000|63.000000] "" ICAS1_Gateway
 SG_ TSK_Fahrzeugstatus_praed_Fkt  : 31|3@1+ (1.000000,0.000000) [0.000000|7.000000] "" ICAS1_Gateway
 SG_ TSK_Texte  : 40|5@1+ (1.000000,0.000000) [0.000000|31.000000] "" ICAS1_Gateway ICAS1_KommunikationsServer
 SG_ TSK_Akustik  : 45|3@1+ (1.000000,0.000000) [0.000000|7.000000] "" ICAS1_Gateway ICAS1_KommunikationsServer
 SG_ TSK_Texte_Primaeranz  : 48|5@1+ (1.000000,0.000000) [0.000000|31.000000] "" ICAS1_Gateway ICAS1_KommunikationsServer
 SG_ TSK_Limiter_Fahrerinfo  : 53|2@1+ (1.000000,0.000000) [0.000000|3.000000] "" ICAS1_Gateway ICAS1_KommunikationsServer
 SG_ TSK_Limiter_Anzeige  : 55|1@1+ (1.000000,0.000000) [0.000000|1.000000] "" ICAS1_Gateway ICAS1_KommunikationsServer
 SG_ TSK_Fahrzeugstatus_GRA  : 56|1@1+ (1.000000,0.000000) [0.000000|1.000000] "" ICAS1_Gateway ICAS1_KommunikationsServer
 SG_ TSK_Fahrzeugstatus_Limiter  : 57|1@1+ (1.000000,0.000000) [0.000000|1.000000] "" ICAS1_Gateway ICAS1_KommunikationsServer
 SG_ MO_Motorlaufwarnung  : 58|1@1+ (1.000000,0.000000) [0.000000|1.000000] "" ICAS1_Gateway
 SG_ TSK_naechstes_Event_Einheit  : 60|1@1+ (1.000000,0.000000) [0.000000|1.000000] "" ICAS1_Gateway
 SG_ TSK_Status_Anzeige  : 61|3@1+ (1.000000,0.000000) [0.000000|7.000000] "" ICAS1_Gateway ICAS1_KommunikationsServer
 SG_ MO_Sperrung_FahrPr_BZS  : 64|8@1+ (1.000000,0.000000) [0.000000|255.000000] "" ICAS1_Gateway
 SG_ MO_Rampenzeit_Generator_Anf  : 72|4@1+ (1.000000,0.000000) [0.000000|15.000000] "" ICAS1_Gateway
 SG_ MO_Prio_MAX_Wunschdrehzahl  : 76|1@1+ (1.000000,0.000000) [0.000000|1.000000] "" ICAS1_Gateway
 SG_ MO_Prio_MIN_Wunschdrehzahl  : 77|1@1+ (1.000000,0.000000) [0.000000|1.000000] "" ICAS1_Gateway
 SG_ MO_Luftpfad_aktiv  : 78|1@1+ (1.000000,0.000000) [0.000000|1.000000] "" ICAS1_Gateway
 SG_ MO_v_Begrenz_Aktivierbar  : 79|1@1+ (1.000000,0.000000) [0.000000|1.000000] "" ICAS1_Gateway
 SG_ MO_Drehzahlbeeinflussung  : 80|8@1+ (0.390000,0.000000) [0.000000|99.450000] "Unit_PerCent" ICAS1_Gateway
 SG_ MO_MIN_Wunschdrehzahl  : 88|8@1+ (25.000000,0.000000) [0.000000|6350.000000] "Unit_MinutInver" ICAS1_Gateway
 SG_ MO_MAX_Wunschdrehzahl  : 96|9@1+ (25.000000,0.000000) [0.000000|12750.000000] "Unit_MinutInver" ICAS1_Gateway
 SG_ MO_Charisma_FahrPr  : 105|4@1+ (1.000000,0.000000) [0.000000|15.000000] "" ICAS1_Gateway
 SG_ MO_Charisma_Status  : 109|2@1+ (1.000000,0.000000) [0.000000|3.000000] "" ICAS1_Gateway
 SG_ MO_StSt_Charisma_FahrPr  : 111|4@1+ (1.000000,0.000000) [0.000000|15.000000] "" ICAS1_Gateway
 SG_ MO_StSt_Charisma_Status  : 115|2@1+ (1.000000,0.000000) [0.000000|3.000000] "" ICAS1_Gateway
 SG_ MO_BZS_Charisma_FahrPr  : 117|4@1+ (1.000000,0.000000) [0.000000|15.000000] "" ICAS1_Gateway
 SG_ MO_BZS_Charisma_Status  : 121|2@1+ (1.000000,0.000000) [0.000000|3.000000] "" ICAS1_Gateway
 SG_ MO_NGS_Position  : 123|1@1+ (1.000000,0.000000) [0.000000|1.000000] "" ICAS1_Gateway
 SG_ MO_NGS_Status  : 124|2@1+ (1.000000,0.000000) [0.000000|3.000000] "" ICAS1_Gateway
 SG_ MO_v_Begrenzung_Niveau  : 126|2@1+ (1.000000,0.000000) [0.000000|3.000000] "" ICAS1_Gateway
 SG_ MO_Anzeige_Rekuperation  : 128|8@1+ (0.500000,-0.500000) [0.000000|100.000000] "Unit_PerCent" ICAS1_Gateway
 SG_ PEA_Fortschrittsanzeige  : 136|7@1+ (1.000000,0.000000) [0.000000|100.000000] "Unit_PerCent" ICAS1_Gateway
 SG_ MO_Anzeige_Fahrbereitschaft  : 143|1@1+ (1.000000,0.000000) [0.000000|1.000000] "" ICAS1_Gateway ICAS1_KommunikationsServer
 SG_ MO_Boost_verfuegbar  : 144|8@1+ (0.400000,-0.400000) [0.000000|100.400000] "Unit_PerCent" ICAS1_Gateway
 SG_ MO_Overboost  : 152|1@1+ (1.000000,0.000000) [0.000000|1.000000] "" ICAS1_Gateway
 SG_ MO_Boost_aktiv  : 153|1@1+ (1.000000,0.000000) [0.000000|1.000000] "" ICAS1_Gateway
 SG_ MO_Anzeige_Betriebsmodus  : 154|4@1+ (1.000000,0.000000) [0.000000|15.000000] "" ICAS1_Gateway
 SG_ PEA_Hinweis  : 158|2@1+ (1.000000,0.000000) [0.000000|3.000000] "" ICAS1_Gateway
 SG_ PEA_Ereignisanzeige  : 160|5@1+ (1.000000,0.000000) [0.000000|31.000000] "" ICAS1_Gateway
 SG_ PEA_Ereignisanzeige_temporaer  : 165|1@1+ (1.000000,0.000000) [0.000000|1.000000] "" ICAS1_Gateway
 SG_ PEA_Abschalttexte  : 166|2@1+ (1.000000,0.000000) [0.000000|3.000000] "" ICAS1_Gateway
 SG_ PEA_Zielgeschw_Einheit  : 168|1@1+ (1.000000,0.000000) [0.000000|1.000000] "" ICAS1_Gateway
 SG_ PEA_Zielgeschw  : 169|5@1+ (1.000000,0.000000) [0.000000|31.000000] "" ICAS1_Gateway
 SG_ MO_Antriebsstrang_Warnung_HS  : 174|2@1+ (1.000000,0.000000) [0.000000|3.000000] "" ICAS1_Gateway
 SG_ MO_Anzeige_Verbrauch_oE  : 176|16@1+ (0.005000,0.000000) [0.000000|327.675000] "Unit_None" ICAS1_Gateway

BO_ 332 Motor_54: 32 Motor_BEV
 SG_ MO_Anforderung_HMS  : 12|3@1+ (1.000000,0.000000) [0.000000|7.000000] "" ICAS1_Gateway
 SG_ FoD_DTC_TSK_GRA  : 15|1@1+ (1.000000,0.000000) [0.000000|1.000000] "" ICAS1_Gateway
 SG_ TSK_vMax_aktuell  : 16|8@1+ (1.000000,0.000000) [0.000000|253.000000] "Unit_KiloMeterPerHour" ICAS1_Gateway
 SG_ TSK_Status_EA  : 32|3@1+ (1.000000,0.000000) [0.000000|7.000000] "" ICAS1_Gateway
 SG_ FoD_DTC_TSK_ACC  : 35|1@1+ (1.000000,0.000000) [0.000000|1.000000] "" ICAS1_Gateway
 SG_ TSK_ACC_FoD_Status  : 36|2@1+ (1.000000,0.000000) [0.000000|3.000000] "" ICAS1_Gateway
 SG_ TSK_GRA_FoD_Status  : 38|2@1+ (1.000000,0.000000) [0.000000|3.000000] "" ICAS1_Gateway
 SG_ TSK_vMax_Fahrerassistenz  : 40|9@1+ (1.000000,0.000000) [0.000000|510.000000] "" ICAS1_Gateway
 SG_ TSK_Einheit_vMax_Fahrerassistenz  : 49|1@1+ (1.000000,0.000000) [0.000000|1.000000] "" ICAS1_Gateway
 SG_ TSK_Status_PLA  : 50|3@1+ (1.000000,0.000000) [0.000000|7.000000] "" ICAS1_Gateway
 SG_ TSK_aktives_System  : 53|3@1+ (1.000000,0.000000) [0.000000|7.000000] "" ICAS1_Gateway
 SG_ TSK_erhoehter_Fahrwiderstand  : 56|1@1+ (1.000000,0.000000) [0.000000|1.000000] "" ICAS1_Gateway
 SG_ TSK_Anf_Antriebsmoment  : 57|1@1+ (1.000000,0.000000) [0.000000|1.000000] "" ICAS1_Gateway
 SG_ TSK_Status_ARA  : 58|3@1+ (1.000000,0.000000) [0.000000|7.000000] "" ICAS1_Gateway
 SG_ TSK_Status_IPA  : 61|3@1+ (1.000000,0.000000) [0.000000|7.000000] "" ICAS1_Gateway
 SG_ MO_Fahrbereitschaft  : 76|2@1+ (1.000000,0.000000) [0.000000|3.000000] "" ICAS1_Gateway LE1 LE2
 SG_ MO_Freilauf_Info  : 78|2@1+ (1.000000,0.000000) [0.000000|3.000000] "" ICAS1_Gateway
 SG_ MO_Krit_Heckobjekt  : 81|3@1+ (1.000000,0.000000) [0.000000|7.000000] "" ICAS1_Gateway
 SG_ MO_NGS_Gangpos  : 84|3@1+ (1.000000,0.000000) [0.000000|7.000000] "" ICAS1_Gateway
 SG_ MO_Freilauf_Status  : 87|3@1+ (1.000000,0.000000) [0.000000|7.000000] "" ICAS1_Gateway
 SG_ MO_EBoost_verf_praed  : 90|2@1+ (1.000000,0.000000) [0.000000|3.000000] "" ICAS1_Gateway
 SG_ MO_Heckspoiler_Anf  : 92|1@1+ (1.000000,0.000000) [0.000000|1.000000] "" ICAS1_Gateway
 SG_ MO_eLaunch_verf  : 93|2@1+ (1.000000,0.000000) [0.000000|3.000000] "" ICAS1_Gateway
 SG_ MO_Positionierung_aktiv  : 95|1@1+ (1.000000,0.000000) [0.000000|1.000000] "" ICAS1_Gateway
 SG_ MO_Freilauf_Typ  : 98|2@1+ (1.000000,0.000000) [0.000000|3.000000] "" ICAS1_Gateway
 SG_ MO_Startwunsch  : 100|1@1+ (1.000000,0.000000) [0.000000|1.000000] "" ICAS1_Gateway
 SG_ OBD_Calc_Load_Val  : 128|8@1+ (0.392157,0.000000) [0.000000|100.000000] "Unit_PerCent" ICAS1_Gateway LE1 LE2
 SG_ OBD_Eng_Cool_Temp  : 136|8@1+ (1.000000,-40.000000) [-40.000000|215.000000] "Unit_DegreCelsi" ICAS1_Gateway LE1 LE2
 SG_ OBD_Abs_Throttle_Pos  : 144|8@1+ (0.392157,0.000000) [0.000000|100.000000] "Unit_PerCent" ICAS1_Gateway LE1 LE2
 SG_ OBD_Abs_Load_Val  : 152|16@1+ (0.392157,0.000000) [0.000000|25700.000000] "Unit_PerCent" ICAS1_Gateway LE1 LE2
 SG_ OBD_Abs_Pedal_Pos  : 168|8@1+ (0.392157,0.000000) [0.000000|100.000000] "Unit_PerCent" ICAS1_Gateway LE1 LE2
 SG_ MO_Servicemodus  : 176|4@1+ (1.000000,0.000000) [0.000000|15.000000] "" ICAS1_Gateway LE1 LE2
 SG_ OBD_ClearMem_Inhibit  : 183|1@1+ (1.000000,0.000000) [0.000000|1.000000] "" ICAS1_Gateway LE1 LE2
 SG_ OBD_Sperrung_Kaltstart_Denom  : 184|1@1+ (1.000000,0.000000) [0.000000|1.000000] "" ICAS1_Gateway LE1 LE2
 SG_ MO_QBit_Aussen_Temp  : 185|1@1+ (1.000000,0.000000) [0.000000|1.000000] "" ICAS1_Gateway
 SG_ OBD_Sperrung_IUMPR  : 186|1@1+ (1.000000,0.000000) [0.000000|1.000000] "" ICAS1_Gateway LE1 LE2
 SG_ OBD_Kaltstart_Denominator  : 187|1@1+ (1.000000,0.000000) [0.000000|1.000000] "" ICAS1_Gateway LE1 LE2
 SG_ OBD_Minimum_Trip  : 188|1@1+ (1.000000,0.000000) [0.000000|1.000000] "" ICAS1_Gateway LE1 LE2
 SG_ OBD_Driving_Cycle  : 189|1@1+ (1.000000,0.000000) [0.000000|1.000000] "" ICAS1_Gateway LE1 LE2
 SG_ OBD_Warm_Up_Cycle  : 190|1@1+ (1.000000,0.000000) [0.000000|1.000000] "" ICAS1_Gateway LE1 LE2
 SG_ OBD_Normed_Trip  : 191|1@1+ (1.000000,0.000000) [0.000000|1.000000] "" ICAS1_Gateway LE1 LE2
 SG_ OBD_Aussen_Temp_gef  : 248|8@1+ (1.000000,-40.000000) [-40.000000|213.000000] "Unit_DegreCelsi" ICAS1_Gateway

BO_ 246 Motor_55: 32 Motor_BEV
 SG_ Motor_55_CRC  : 0|8@1+ (1.000000,0.000000) [0.000000|255.000000] "" ICAS1_Gateway
 SG_ Motor_55_BZ  : 8|4@1+ (1.000000,0.000000) [0.000000|15.000000] "" ICAS1_Gateway
 SG_ TS_Faktor_Radmomente  : 12|2@1+ (1.000000,0.000000) [0.000000|3.000000] "" ICAS1_Gateway
 SG_ TS_Status_MomRad_Ist  : 14|2@1+ (1.000000,0.000000) [0.000000|3.000000] "" ICAS1_Gateway
 SG_ TS_MomRad_verfuegb_maxReku_Summe  : 16|12@1+ (3.000000,-12279.000000) [-12279.000000|0.000000] "" ICAS1_Gateway
 SG_ TS_MomRad_Ist  : 28|13@1+ (3.000000,-12279.000000) [-12279.000000|12279.000000] "Unit_None" ICAS1_Gateway
 SG_ TS_MomRad_Soll_Summe  : 41|13@1+ (3.000000,-12279.000000) [-12279.000000|12279.000000] "Unit_None" ICAS1_Gateway
 SG_ TS_MomRad_Wunsch  : 54|13@1+ (3.000000,-12279.000000) [-12279.000000|12279.000000] "Unit_None" ICAS1_Gateway
 SG_ TS_MomRad_Wunsch_sek  : 67|13@1+ (3.000000,-12279.000000) [-12279.000000|12279.000000] "Unit_None" ICAS1_Gateway
 SG_ TS_MomRad_verfuegb_max  : 80|12@1+ (3.000000,0.000000) [0.000000|12279.000000] "Unit_None" ICAS1_Gateway
 SG_ TS_MomRad_verfuegb_max_sek  : 92|12@1+ (3.000000,0.000000) [0.000000|12279.000000] "Unit_None" ICAS1_Gateway
 SG_ TS_MomRad_verfuegb_maxReku  : 104|12@1+ (3.000000,-12279.000000) [-12279.000000|0.000000] "Unit_None" ICAS1_Gateway
 SG_ TS_MomRad_verfuegb_maxReku_sek  : 116|12@1+ (3.000000,-12279.000000) [-12279.000000|0.000000] "Unit_None" ICAS1_Gateway
 SG_ TS_MomRad_Ist_sek  : 128|13@1+ (3.000000,-12279.000000) [-12279.000000|12279.000000] "Unit_None" ICAS1_Gateway
 SG_ TS_Allrad_Anteil_sek  : 141|9@1+ (0.200000,0.000000) [0.000000|100.000000] "Unit_PerCent" ICAS1_Gateway
 SG_ FDR_Allrad_Anteil_max_sek  : 150|9@1+ (0.200000,0.000000) [0.000000|100.000000] "Unit_PerCent" ICAS1_Gateway
 SG_ FDR_Allrad_Anteil_min_sek  : 159|9@1+ (0.200000,0.000000) [0.000000|100.000000] "Unit_PerCent" ICAS1_Gateway
 SG_ FDR_MomRad_Eingriff  : 168|13@1+ (3.000000,-12279.000000) [-12279.000000|12279.000000] "Unit_NewtoMeter" ICAS1_Gateway
 SG_ FDR_Status_Eingriff  : 181|1@1+ (1.000000,0.000000) [0.000000|1.000000] "" ICAS1_Gateway
 SG_ FDR_MomRad_Eingriff_sek  : 182|13@1+ (3.000000,-12279.000000) [-12279.000000|12279.000000] "Unit_NewtoMeter" ICAS1_Gateway
 SG_ FDR_Status_Eingriff_sek  : 195|1@1+ (1.000000,0.000000) [0.000000|1.000000] "" ICAS1_Gateway

BU_:  Airbag BAP_Tester ICAS1_Gateway ICAS1_KommunikationsServer LE1 LE2 Motor_BEV Schaltbetaetigung

BO_ 967 Motor_26: 8 Motor_BEV
 SG_ MO_Kuehlerluefter_MUX M : 0|1@1+ (1.000000,0.000000) [0.000000|1.000000] "siema ooo" ICAS1_Gateway
 SG_ MO_Kuehlerluefter_1 m0 : 1|7@1+ (1.000000,0.000000) [0.000000|100.000000] "Unit_PerCent" ICAS1_Gateway
 SG_ MO_Kuehlerluefter_2 m1 : 1|7@1+ (1.000000,0.000000) [0.000000|100.000000] "Unit_PerCent" ICAS1_Gateway
 SG_ MO_EFLEX_Lampe  : 8|2@1+ (1.000000,0.000000) [0.000000|3.000000] "" ICAS1_Gateway
 SG_ MO_KJS_nicht_bereit  : 10|1@1+ (1.000000,0.000000) [0.000000|1.000000] "" ICAS1_Gateway
 SG_ MO_ITM_Warnung_Pumpe  : 11|1@1+ (1.000000,0.000000) [0.000000|1.000000] "" ICAS1_Gateway
 SG_ WIV_Anzeige_aktiv  : 12|1@1+ (1.000000,0.000000) [0.000000|1.000000] "" ICAS1_Gateway
 SG_ WIV_Oelmin_Warn  : 13|1@1+ (1.000000,0.000000) [0.000000|1.000000] "" ICAS1_Gateway
 SG_ WIV_Sensorfehler  : 14|1@1+ (1.000000,0.000000) [0.000000|1.000000] "" ICAS1_Gateway
 SG_ WIV_Schieflage  : 15|1@1+ (1.000000,0.000000) [0.000000|1.000000] "" ICAS1_Gateway
 SG_ WIV_Oelstand  : 16|4@1+ (12.500000,0.000000) [0.000000|100.000000] "Unit_PerCent" ICAS1_Gateway
 SG_ MO_Zustand_HWP  : 20|2@1+ (1.000000,0.000000) [0.000000|3.000000] "" ICAS1_Gateway
 SG_ OLEV_Systemstoerung  : 22|1@1+ (1.000000,0.000000) [0.000000|1.000000] "" ICAS1_Gateway
 SG_ MO_Oelwarnung_max  : 23|1@1+ (1.000000,0.000000) [0.000000|1.000000] "" ICAS1_Gateway
 SG_ WIV_Oelsystem_aktiv  : 24|1@1+ (1.000000,0.000000) [0.000000|1.000000] "" ICAS1_Gateway
 SG_ WIV_nicht_betriebswarm  : 25|1@1+ (1.000000,0.000000) [0.000000|1.000000] "" ICAS1_Gateway
 SG_ WIV_Ueberfuell_Warn  : 26|1@1+ (1.000000,0.000000) [0.000000|1.000000] "" ICAS1_Gateway
 SG_ WIV_laufender_Motor  : 27|1@1+ (1.000000,0.000000) [0.000000|1.000000] "" ICAS1_Gateway
 SG_ MO_E_Warnungen  : 28|4@1+ (1.000000,0.000000) [0.000000|15.000000] "" ICAS1_Gateway
 SG_ MO_Text_Motorstart  : 32|4@1+ (1.000000,0.000000) [0.000000|15.000000] "" ICAS1_Gateway
 SG_ MO_E_Texte  : 36|4@1+ (1.000000,0.000000) [0.000000|15.000000] "" ICAS1_Gateway
 SG_ WIV_Oeldyn_avl  : 40|1@1+ (1.000000,0.000000) [0.000000|1.000000] "" ICAS1_Gateway
 SG_ MO_Text_Partikelfil_Reg  : 41|1@1+ (1.000000,0.000000) [0.000000|1.000000] "" ICAS1_Gateway
 SG_ OLEV_Oelstand_nicht_vorhanden  : 42|1@1+ (1.000000,0.000000) [0.000000|1.000000] "" ICAS1_Gateway
 SG_ WIV_Oelmenge  : 43|5@1+ (125.000000,0.000000) [0.000000|3875.000000] "Unit_MilliLiter" ICAS1_Gateway
 SG_ MO_Systemlampe  : 48|1@1+ (1.000000,0.000000) [0.000000|1.000000] "" ICAS1_Gateway
 SG_ MO_OBD2_Lampe  : 49|1@1+ (1.000000,0.000000) [0.000000|1.000000] "" ICAS1_Gateway
 SG_ MO_Heissleuchte  : 50|1@1+ (1.000000,0.000000) [0.000000|1.000000] "" ICAS1_Gateway
 SG_ MO_Partikel_Lampe  : 51|1@1+ (1.000000,0.000000) [0.000000|1.000000] "" ICAS1_Gateway
 SG_ MO_RedFahrleistung_Lampe  : 52|1@1+ (1.000000,0.000000) [0.000000|1.000000] "" ICAS1_Gateway ICAS1_KommunikationsServer
 SG_ WIV_Oelstand_nicht_vorhanden  : 53|1@1+ (1.000000,0.000000) [0.000000|1.000000] "" ICAS1_Gateway
 SG_ WIV_nachfuellanzeige_ein  : 54|1@1+ (1.000000,0.000000) [0.000000|1.000000] "" ICAS1_Gateway
 SG_ WIV_Ueberfuell_deaktiv  : 55|1@1+ (1.000000,0.000000) [0.000000|1.000000] "" ICAS1_Gateway
 SG_ WIV_Unterfuell_Warn  : 56|1@1+ (1.000000,0.000000) [0.000000|1.000000] "" ICAS1_Gateway
 SG_ MO_Tankdeckel_Lampe  : 57|1@1+ (1.000000,0.000000) [0.000000|1.000000] "" ICAS1_Gateway
 SG_ MO_Text_Tankdeckelwarn  : 58|1@1+ (1.000000,0.000000) [0.000000|1.000000] "" ICAS1_Gateway
 SG_ MO_Vorglueh_Lampe  : 59|1@1+ (1.000000,0.000000) [0.000000|1.000000] "" ICAS1_Gateway
 SG_ WIV_Oeldr_Warn_Motor  : 60|1@1+ (1.000000,0.000000) [0.000000|1.000000] "" ICAS1_Gateway
 SG_ MO_E_Mode  : 61|3@1+ (1.000000,0.000000) [0.000000|7.000000] "" ICAS1_Gateway

BO_ 706 Motor_41: 8 Motor_BEV
 SG_ MO_Anzeige_StSt_Text  : 12|4@1+ (1.000000,0.000000) [0.000000|15.000000] "" Vector__XXX
 SG_ MO_Anzeige_StSt_Symbol  : 16|3@1+ (1.000000,0.000000) [0.000000|7.000000] "" Vector__XXX
 SG_ MO_ADR_Status  : 19|2@1+ (1.000000,0.000000) [0.000000|3.000000] "" Vector__XXX
 SG_ MO_AGA_Sound_Texte  : 21|2@1+ (1.000000,0.000000) [0.000000|3.000000] "" Vector__XXX
 SG_ MO_Anzeige_FMAus_Text  : 23|1@1+ (1.000000,0.000000) [0.000000|1.000000] "" Vector__XXX
 SG_ PEA_Texte  : 25|3@1+ (1.000000,0.000000) [0.000000|7.000000] "" Vector__XXX
 SG_ TSK_Ueberstimmt_vMax_FahrerInfo  : 28|2@1+ (1.000000,0.000000) [0.000000|3.000000] "" Vector__XXX
 SG_ MO_Rekuperationsstufe  : 32|3@1+ (1.000000,0.000000) [0.000000|7.000000] "" ICAS1_KommunikationsServer
 SG_ TSK_Einheit_vMax_FahrerInfo  : 35|1@1+ (1.000000,0.000000) [0.000000|1.000000] "" ICAS1_KommunikationsServer
 SG_ TSK_Status_vMax_FahrerInfo  : 36|2@1+ (1.000000,0.000000) [0.000000|3.000000] "" ICAS1_KommunikationsServer
 SG_ MO_Anz_Kuehlerluefter  : 47|3@1+ (1.000000,0.000000) [0.000000|7.000000] "" Vector__XXX
 SG_ FDR_Warnung_ALR  : 50|2@1+ (1.000000,0.000000) [0.000000|3.000000] "" ICAS1_KommunikationsServer
 SG_ TSK_vMax_FahrerInfo  : 56|8@1+ (1.000000,15.000000) [16.000000|270.000000] "" ICAS1_KommunikationsServer

BO_ 267 Motor_51: 32 Motor_BEV
 SG_ Motor_51_CRC  : 0|8@1+ (1.000000,0.000000) [0.000000|255.000000] "" ICAS1_Gateway
 SG_ Motor_51_BZ  : 8|4@1+ (1.000000,0.000000) [0.000000|15.000000] "" ICAS1_Gateway
 SG_ MO_Fahrpedalrohwert_01  : 12|8@1+ (0.400000,0.000000) [0.000000|101.600000] "Unit_PerCent" Airbag ICAS1_Gateway
 SG_ MO_QBit_Fahrpedalwerte_01  : 20|1@1+ (1.000000,0.000000) [0.000000|1.000000] "" Airbag ICAS1_Gateway
 SG_ MO_Fahrpedalgradient  : 21|8@1+ (25.000000,0.000000) [0.000000|6350.000000] "Unit_PerCentPerSecon" ICAS1_Gateway
 SG_ MO_Sig_Fahrpedalgradient  : 29|1@1+ (1.000000,0.000000) [0.000000|1.000000] "" ICAS1_Gateway
 SG_ MO_rel_Saugrohrdruck  : 30|6@1+ (18.000000,0.000000) [0.000000|1116.000000] "Unit_MilliBar" ICAS1_Gateway
 SG_ MO_rel_Saugrohrdruck_gem_err  : 36|1@1+ (1.000000,0.000000) [0.000000|1.000000] "" ICAS1_Gateway
 SG_ MO_Moment_im_Leerlauf  : 37|1@1+ (1.000000,0.000000) [0.000000|1.000000] "" ICAS1_Gateway
 SG_ MO_Schubabschaltung  : 38|1@1+ (1.000000,0.000000) [0.000000|1.000000] "" ICAS1_Gateway
 SG_ MO_Solldrehz_Leerlauf  : 40|8@1+ (10.000000,0.000000) [0.000000|2540.000000] "Unit_MinutInver" ICAS1_Gateway
 SG_ MO_Entkopplung_Sollschlupf  : 48|7@1+ (20.000000,0.000000) [0.000000|2480.000000] "Unit_MinutInver" ICAS1_Gateway
 SG_ MO_temporaere_Fahrerabwesenheit  : 55|1@1+ (1.000000,0.000000) [0.000000|1.000000] "" ICAS1_Gateway
 SG_ TSK_a_Soll_gradientenbegrenzt  : 57|7@1+ (0.100000,-7.200000) [-7.200000|5.400000] "Unit_MeterPerSeconSquar" ICAS1_Gateway
 SG_ TSK_Radbremsmom  : 76|12@1+ (8.000000,0.000000) [0.000000|32760.000000] "Unit_NewtoMeter" ICAS1_Gateway
 SG_ TSK_Status  : 88|3@1+ (1.000000,0.000000) [0.000000|7.000000] "" ICAS1_Gateway
 SG_ TSK_v_Begrenzung_aktiv  : 91|1@1+ (1.000000,0.000000) [0.000000|1.000000] "" ICAS1_Gateway
 SG_ TSK_Standby_Anf_ESP  : 92|1@1+ (1.000000,0.000000) [0.000000|1.000000] "" ICAS1_Gateway
 SG_ TSK_Freig_WU  : 93|1@1+ (1.000000,0.000000) [0.000000|1.000000] "" ICAS1_Gateway
 SG_ TSK_Freig_Verzoeg_Anf  : 94|1@1+ (1.000000,0.000000) [0.000000|1.000000] "" ICAS1_Gateway
 SG_ TSK_Limiter_ausgewaehlt  : 95|1@1+ (1.000000,0.000000) [0.000000|1.000000] "" ICAS1_Gateway
 SG_ TSK_Wunsch_Uebersetz  : 96|10@1+ (0.024500,0.000000) [0.024500|25.063500] "" ICAS1_Gateway
 SG_ TSK_Hauptschalter_GRA_ACC  : 106|2@1+ (1.000000,0.000000) [0.000000|3.000000] "" ICAS1_Gateway ICAS1_KommunikationsServer
 SG_ TSK_SRBM_Anf_ASIL  : 108|3@1+ (1.000000,0.000000) [0.000000|7.000000] "" ICAS1_Gateway
 SG_ TSK_ax_Getriebe_02  : 112|9@1+ (0.024000,-2.016000) [-2.016000|10.224000] "Unit_MeterPerSeconSquar" ICAS1_Gateway
 SG_ TSK_Zwangszusch_ESP  : 121|1@1+ (1.000000,0.000000) [0.000000|1.000000] "" ICAS1_Gateway
 SG_ TSK_zul_Regelabw  : 122|6@1+ (0.024000,0.000000) [0.000000|1.512000] "Unit_MeterPerSeconSquar" ICAS1_Gateway
 SG_ MO_Status_MinDrzEingriff  : 235|3@1+ (1.000000,0.000000) [0.000000|7.000000] "" ICAS1_Gateway
 SG_ MO_Status_MaxDrzEingriff  : 238|3@1+ (1.000000,0.000000) [0.000000|7.000000] "" ICAS1_Gateway
 SG_ MO_Status_MinDrzEingriff_sek  : 241|3@1+ (1.000000,0.000000) [0.000000|7.000000] "" ICAS1_Gateway
 SG_ MO_Status_MaxDrzEingriff_sek  : 244|3@1+ (1.000000,0.000000) [0.000000|7.000000] "" ICAS1_Gateway
 SG_ GRA_KuFu_aktiv  : 247|1@1+ (1.000000,0.000000) [0.000000|1.000000] "" ICAS1_Gateway
 SG_ TSK_SRBM_max_Gradient  : 248|7@1+ (50.000000,0.000000) [0.000000|6250.000000] "Unit_NewtoMeterPerSecon" ICAS1_Gateway
 SG_ LIM_KuFu_aktiv  : 255|1@1+ (1.000000,0.000000) [0.000000|1.000000] "" ICAS1_Gateway

BO_ 330 Motor_52: 32 Motor_BEV
 SG_ MO_Hochschaltdrehz  : 21|12@1+ (3.000000,0.000000) [3.000000|12282.000000] "Unit_MinutInver" Vector__XXX
 SG_ MO_Anzeige_Verbr_Einheit  : 33|2@1+ (1.000000,0.000000) [0.000000|3.000000] "" Vector__XXX
 SG_ MO_Schaltblitz_Anz  : 35|7@1+ (1.000000,0.000000) [0.000000|100.000000] "Unit_PerCent" Vector__XXX
 SG_ MO_Anzeige_Drehmoment  : 42|11@1+ (1.000000,0.000000) [0.000000|2045.000000] "Unit_NewtoMeter" Vector__XXX
 SG_ MO_Anzeige_Leistung  : 53|11@1+ (0.600000,0.000000) [0.000000|1227.000000] "Unit_KiloWatt" Vector__XXX
 SG_ MO_rel_Ladedruck  : 64|8@1+ (0.400000,0.000000) [0.000000|100.000000] "Unit_PerCent" Vector__XXX
 SG_ MO_Istgang  : 72|4@1+ (1.000000,0.000000) [0.000000|15.000000] "" Vector__XXX
 SG_ MO_Sollgang  : 76|4@1+ (1.000000,0.000000) [0.000000|15.000000] "" Vector__XXX
 SG_ MO_Oeldruck  : 80|8@1+ (0.040000,0.000000) [0.000000|10.000000] "Unit_Bar" Vector__XXX
 SG_ MO_Anzeigedrehz  : 88|12@1+ (3.000000,0.000000) [0.000000|12282.000000] "Unit_MinutInver" Vector__XXX
 SG_ MO_Effizienzmodus  : 100|1@1+ (1.000000,0.000000) [0.000000|1.000000] "" Vector__XXX
 SG_ MO_Fehler_Oeldrucksensor  : 101|1@1+ (1.000000,0.000000) [0.000000|1.000000] "" Vector__XXX
 SG_ MO_Schaltempf_verfbar  : 102|1@1+ (1.000000,0.000000) [0.000000|1.000000] "" Vector__XXX
 SG_ MO_Ladedruck  : 103|9@1+ (0.010000,0.000000) [0.000000|5.100000] "Unit_Bar" Vector__XXX
 SG_ MO_KVS  : 112|15@1+ (1.000000,0.000000) [0.000000|32767.000000] "Unit_MicroLiter" Vector__XXX
 SG_ MO_KVS_Ueberlauf  : 127|1@1+ (1.000000,0.000000) [0.000000|1.000000] "" Vector__XXX
 SG_ MO_ePowermeter  : 128|8@1+ (0.400000,-0.400000) [0.000000|100.800000] "Unit_PerCent" Vector__XXX
 SG_ MO_ePerformance  : 136|8@1+ (0.400000,-0.400000) [0.000000|100.800000] "Unit_PerCent" ICAS1_KommunikationsServer
 SG_ MO_Zust_Antrieb  : 144|4@1+ (1.000000,0.000000) [0.000000|15.000000] "" Vector__XXX
 SG_ MO_Zust_Betriebsstrategie  : 148|3@1+ (1.000000,0.000000) [0.000000|7.000000] "" Vector__XXX
 SG_ Ladezustand_02  : 152|8@1+ (0.500000,0.000000) [0.000000|100.000000] "Unit_PerCent" ICAS1_Gateway ICAS1_KommunikationsServer
 SG_ MO_Powermeter_Elm_02  : 168|12@1+ (0.050000,-102.400000) [-100.000000|100.000000] "Unit_PerCent" Vector__XXX
 SG_ MO_Powermeter  : 180|12@1+ (1.000000,0.000000) [0.000000|4092.000000] "" ICAS1_KommunikationsServer

BO_ 512 Motor_53: 32 Motor_BEV
 SG_ TSK_Wunschgeschw  : 12|10@1+ (0.320000,0.000000) [0.000000|326.720000] "Unit_KiloMeterPerHour" ICAS1_Gateway ICAS1_KommunikationsServer
 SG_ TSK_praediktiver_Hinweis  : 22|3@1+ (1.000000,0.000000) [0.000000|7.000000] "" ICAS1_Gateway
 SG_ TSK_naechstes_Event  : 25|6@1+ (1.000000,0.000000) [0.000000|63.000000] "" ICAS1_Gateway
 SG_ TSK_Fahrzeugstatus_praed_Fkt  : 31|3@1+ (1.000000,0.000000) [0.000000|7.000000] "" ICAS1_Gateway
 SG_ TSK_Texte  : 40|5@1+ (1.000000,0.000000) [0.000000|31.000000] "" ICAS1_Gateway ICAS1_KommunikationsServer
 SG_ TSK_Akustik  : 45|3@1+ (1.000000,0.000000) [0.000000|7.000000] "" ICAS1_Gateway ICAS1_KommunikationsServer
 SG_ TSK_Texte_Primaeranz  : 48|5@1+ (1.000000,0.000000) [0.000000|31.000000] "" ICAS1_Gateway ICAS1_KommunikationsServer
 SG_ TSK_Limiter_Fahrerinfo  : 53|2@1+ (1.000000,0.000000) [0.000000|3.000000] "" ICAS1_Gateway ICAS1_KommunikationsServer
 SG_ TSK_Limiter_Anzeige  : 55|1@1+ (1.000000,0.000000) [0.000000|1.000000] "" ICAS1_Gateway ICAS1_KommunikationsServer
 SG_ TSK_Fahrzeugstatus_GRA  : 56|1@1+ (1.000000,0.000000) [0.000000|1.000000] "" ICAS1_Gateway ICAS1_KommunikationsServer
 SG_ TSK_Fahrzeugstatus_Limiter  : 57|1@1+ (1.000000,0.000000) [0.000000|1.000000] "" ICAS1_Gateway ICAS1_KommunikationsServer
 SG_ MO_Motorlaufwarnung  : 58|1@1+ (1.000000,0.000000) [0.000000|1.000000] "" ICAS1_Gateway
 SG_ TSK_naechstes_Event_Einheit  : 60|1@1+ (1.000000,0.000000) [0.000000|1.000000] "" ICAS1_Gateway
 SG_ TSK_Status_Anzeige  : 61|3@1+ (1.000000,0.000000) [0.000000|7.000000] "" ICAS1_Gateway ICAS1_KommunikationsServer
 SG_ MO_Sperrung_FahrPr_BZS  : 64|8@1+ (1.000000,0.000000) [0.000000|255.000000] "" ICAS1_Gateway
 SG_ MO_Rampenzeit_Generator_Anf  : 72|4@1+ (1.000000,0.000000) [0.000000|15.000000] "" ICAS1_Gateway
 SG_ MO_Prio_MAX_Wunschdrehzahl  : 76|1@1+ (1.000000,0.000000) [0.000000|1.000000] "" ICAS1_Gateway
 SG_ MO_Prio_MIN_Wunschdrehzahl  : 77|1@1+ (1.000000,0.000000) [0.000000|1.000000] "" ICAS1_Gateway
 SG_ MO_Luftpfad_aktiv  : 78|1@1+ (1.000000,0.000000) [0.000000|1.000000] "" ICAS1_Gateway
 SG_ MO_v_Begrenz_Aktivierbar  : 79|1@1+ (1.000000,0.000000) [0.000000|1.000000] "" ICAS1_Gateway
 SG_ MO_Drehzahlbeeinflussung  : 80|8@1+ (0.390000,0.000000) [0.000000|99.450000] "Unit_PerCent" ICAS1_Gateway
 SG_ MO_MIN_Wunschdrehzahl  : 88|8@1+ (25.000000,0.000000) [0.000000|6350.000000] "Unit_MinutInver" ICAS1_Gateway
 SG_ MO_MAX_Wunschdrehzahl  : 96|9@1+ (25.000000,0.000000) [0.000000|12750.000000] "Unit_MinutInver" ICAS1_Gateway
 SG_ MO_Charisma_FahrPr  : 105|4@1+ (1.000000,0.000000) [0.000000|15.000000] "" ICAS1_Gateway
 SG_ MO_Charisma_Status  : 109|2@1+ (1.000000,0.000000) [0.000000|3.000000] "" ICAS1_Gateway
 SG_ MO_StSt_Charisma_FahrPr  : 111|4@1+ (1.000000,0.000000) [0.000000|15.000000] "" ICAS1_Gateway
 SG_ MO_StSt_Charisma_Status  : 115|2@1+ (1.000000,0.000000) [0.000000|3.000000] "" ICAS1_Gateway
 SG_ MO_BZS_Charisma_FahrPr  : 117|4@1+ (1.000000,0.000000) [0.000000|15.000000] "" ICAS1_Gateway
 SG_ MO_BZS_Charisma_Status  : 121|2@1+ (1.000000,0.000000) [0.000000|3.000000] "" ICAS1_Gateway
 SG_ MO_NGS_Position  : 123|1@1+ (1.000000,0.000000) [0.000000|1.000000] "" ICAS1_Gateway
 SG_ MO_NGS_Status  : 124|2@1+ (1.000000,0.000000) [0.000000|3.000000] "" ICAS1_Gateway
 SG_ MO_v_Begrenzung_Niveau  : 126|2@1+ (1.000000,0.000000) [0.000000|3.000000] "" ICAS1_Gateway
 SG_ MO_Anzeige_Rekuperation  : 128|8@1+ (0.500000,-0.500000) [0.000000|100.000000] "Unit_PerCent" ICAS1_Gateway
 SG_ PEA_Fortschrittsanzeige  : 136|7@1+ (1.000000,0.000000) [0.000000|100.000000] "Unit_PerCent" ICAS1_Gateway
 SG_ MO_Anzeige_Fahrbereitschaft  : 143|1@1+ (1.000000,0.000000) [0.000000|1.000000] "" ICAS1_Gateway ICAS1_KommunikationsServer
 SG_ MO_Boost_verfuegbar  : 144|8@1+ (0.400000,-0.400000) [0.000000|100.400000] "Unit_PerCent" ICAS1_Gateway
 SG_ MO_Overboost  : 152|1@1+ (1.000000,0.000000) [0.000000|1.000000] "" ICAS1_Gateway
 SG_ MO_Boost_aktiv  : 153|1@1+ (1.000000,0.000000) [0.000000|1.000000] "" ICAS1_Gateway
 SG_ MO_Anzeige_Betriebsmodus  : 154|4@1+ (1.000000,0.000000) [0.000000|15.000000] "" ICAS1_Gateway
 SG_ PEA_Hinweis  : 158|2@1+ (1.000000,0.000000) [0.000000|3.000000] "" ICAS1_Gateway
 SG_ PEA_Ereignisanzeige  : 160|5@1+ (1.000000,0.000000) [0.000000|31.000000] "" ICAS1_Gateway
 SG_ PEA_Ereignisanzeige_temporaer  : 165|1@1+ (1.000000,0.000000) [0.000000|1.000000] "" ICAS1_Gateway
 SG_ PEA_Abschalttexte  : 166|2@1+ (1.000000,0.000000) [0.000000|3.000000] "" ICAS1_Gateway
 SG_ PEA_Zielgeschw_Einheit  : 168|1@1+ (1.000000,0.000000) [0.000000|1.000000] "" ICAS1_Gateway
 SG_ PEA_Zielgeschw  : 169|5@1+ (1.000000,0.000000) [0.000000|31.000000] "" ICAS1_Gateway
 SG_ MO_Antriebsstrang_Warnung_HS  : 174|2@1+ (1.000000,0.000000) [0.000000|3.000000] "" ICAS1_Gateway
 SG_ MO_Anzeige_Verbrauch_oE  : 176|16@1+ (0.005000,0.000000) [0.000000|327.675000] "Unit_None" ICAS1_Gateway

BO_ 332 Motor_54: 32 Motor_BEV
 SG_ MO_Anforderung_HMS  : 12|3@1+ (1.000000,0.000000) [0.000000|7.000000] "" ICAS1_Gateway
 SG_ FoD_DTC_TSK_GRA  : 15|1@1+ (1.000000,0.000000) [0.000000|1.000000] "" ICAS1_Gateway
 SG_ TSK_vMax_aktuell  : 16|8@1+ (1.000000,0.000000) [0.000000|253.000000] "Unit_KiloMeterPerHour" ICAS1_Gateway
 SG_ TSK_Status_EA  : 32|3@1+ (1.000000,0.000000) [0.000000|7.000000] "" ICAS1_Gateway
 SG_ FoD_DTC_TSK_ACC  : 35|1@1+ (1.000000,0.000000) [0.000000|1.000000] "" ICAS1_Gateway
 SG_ TSK_ACC_FoD_Status  : 36|2@1+ (1.000000,0.000000) [0.000000|3.000000] "" ICAS1_Gateway
 SG_ TSK_GRA_FoD_Status  : 38|2@1+ (1.000000,0.000000) [0.000000|3.000000] "" ICAS1_Gateway
 SG_ TSK_vMax_Fahrerassistenz  : 40|9@1+ (1.000000,0.000000) [0.000000|510.000000] "" ICAS1_Gateway
 SG_ TSK_Einheit_vMax_Fahrerassistenz  : 49|1@1+ (1.000000,0.000000) [0.000000|1.000000] "" ICAS1_Gateway
 SG_ TSK_Status_PLA  : 50|3@1+ (1.000000,0.000000) [0.000000|7.000000] "" ICAS1_Gateway
 SG_ TSK_aktives_System  : 53|3@1+ (1.000000,0.000000) [0.000000|7.000000] "" ICAS1_Gateway
 SG_ TSK_erhoehter_Fahrwiderstand  : 56|1@1+ (1.000000,0.000000) [0.000000|1.000000] "" ICAS1_Gateway
 SG_ TSK_Anf_Antriebsmoment  : 57|1@1+ (1.000000,0.000000) [0.000000|1.000000] "" ICAS1_Gateway
 SG_ TSK_Status_ARA  : 58|3@1+ (1.000000,0.000000) [0.000000|7.000000] "" ICAS1_Gateway
 SG_ TSK_Status_IPA  : 61|3@1+ (1.000000,0.000000) [0.000000|7.000000] "" ICAS1_Gateway
 SG_ MO_Fahrbereitschaft  : 76|2@1+ (1.000000,0.000000) [0.000000|3.000000] "" ICAS1_Gateway LE1 LE2
 SG_ MO_Freilauf_Info  : 78|2@1+ (1.000000,0.000000) [0.000000|3.000000] "" ICAS1_Gateway
 SG_ MO_Krit_Heckobjekt  : 81|3@1+ (1.000000,0.000000) [0.000000|7.000000] "" ICAS1_Gateway
 SG_ MO_NGS_Gangpos  : 84|3@1+ (1.000000,0.000000) [0.000000|7.000000] "" ICAS1_Gateway
 SG_ MO_Freilauf_Status  : 87|3@1+ (1.000000,0.000000) [0.000000|7.000000] "" ICAS1_Gateway
 SG_ MO_EBoost_verf_praed  : 90|2@1+ (1.000000,0.000000) [0.000000|3.000000] "" ICAS1_Gateway
 SG_ MO_Heckspoiler_Anf  : 92|1@1+ (1.000000,0.000000) [0.000000|1.000000] "" ICAS1_Gateway
 SG_ MO_eLaunch_verf  : 93|2@1+ (1.000000,0.000000) [0.000000|3.000000] "" ICAS1_Gateway
 SG_ MO_Positionierung_aktiv  : 95|1@1+ (1.000000,0.000000) [0.000000|1.000000] "" ICAS1_Gateway
 SG_ MO_Freilauf_Typ  : 98|2@1+ (1.000000,0.000000) [0.000000|3.000000] "" ICAS1_Gateway
 SG_ MO_Startwunsch  : 100|1@1+ (1.000000,0.000000) [0.000000|1.000000] "" ICAS1_Gateway
 SG_ OBD_Calc_Load_Val  : 128|8@1+ (0.392157,0.000000) [0.000000|100.000000] "Unit_PerCent" ICAS1_Gateway LE1 LE2
 SG_ OBD_Eng_Cool_Temp  : 136|8@1+ (1.000000,-40.000000) [-40.000000|215.000000] "Unit_DegreCelsi" ICAS1_Gateway LE1 LE2
 SG_ OBD_Abs_Throttle_Pos  : 144|8@1+ (0.392157,0.000000) [0.000000|100.000000] "Unit_PerCent" ICAS1_Gateway LE1 LE2
 SG_ OBD_Abs_Load_Val  : 152|16@1+ (0.392157,0.000000) [0.000000|25700.000000] "Unit_PerCent" ICAS1_Gateway LE1 LE2
 SG_ OBD_Abs_Pedal_Pos  : 168|8@1+ (0.392157,0.000000) [0.000000|100.000000] "Unit_PerCent" ICAS1_Gateway LE1 LE2
 SG_ MO_Servicemodus  : 176|4@1+ (1.000000,0.000000) [0.000000|15.000000] "" ICAS1_Gateway LE1 LE2
 SG_ OBD_ClearMem_Inhibit  : 183|1@1+ (1.000000,0.000000) [0.000000|1.000000] "" ICAS1_Gateway LE1 LE2
 SG_ OBD_Sperrung_Kaltstart_Denom  : 184|1@1+ (1.000000,0.000000) [0.000000|1.000000] "" ICAS1_Gateway LE1 LE2
 SG_ MO_QBit_Aussen_Temp  : 185|1@1+ (1.000000,0.000000) [0.000000|1.000000] "" ICAS1_Gateway
 SG_ OBD_Sperrung_IUMPR  : 186|1@1+ (1.000000,0.000000) [0.000000|1.000000] "" ICAS1_Gateway LE1 LE2
 SG_ OBD_Kaltstart_Denominator  : 187|1@1+ (1.000000,0.000000) [0.000000|1.000000] "" ICAS1_Gateway LE1 LE2
 SG_ OBD_Minimum_Trip  : 188|1@1+ (1.000000,0.000000) [0.000000|1.000000] "" ICAS1_Gateway LE1 LE2
 SG_ OBD_Driving_Cycle  : 189|1@1+ (1.000000,0.000000) [0.000000|1.000000] "" ICAS1_Gateway LE1 LE2
 SG_ OBD_Warm_Up_Cycle  : 190|1@1+ (1.000000,0.000000) [0.000000|1.000000] "" ICAS1_Gateway LE1 LE2
 SG_ OBD_Normed_Trip  : 191|1@1+ (1.000000,0.000000) [0.000000|1.000000] "" ICAS1_Gateway LE1 LE2
 SG_ OBD_Aussen_Temp_gef  : 248|8@1+ (1.000000,-40.000000) [-40.000000|213.000000] "Unit_DegreCelsi" ICAS1_Gateway

BO_ 246 Motor_55: 32 Motor_BEV
 SG_ Motor_55_CRC  : 0|8@1+ (1.000000,0.000000) [0.000000|255.000000] "" ICAS1_Gateway
 SG_ Motor_55_BZ  : 8|4@1+ (1.000000,0.000000) [0.000000|15.000000] "" ICAS1_Gateway
 SG_ TS_Faktor_Radmomente  : 12|2@1+ (1.000000,0.000000) [0.000000|3.000000] "" ICAS1_Gateway
 SG_ TS_Status_MomRad_Ist  : 14|2@1+ (1.000000,0.000000) [0.000000|3.000000] "" ICAS1_Gateway
 SG_ TS_MomRad_verfuegb_maxReku_Summe  : 16|12@1+ (3.000000,-12279.000000) [-12279.000000|0.000000] "" ICAS1_Gateway
 SG_ TS_MomRad_Ist  : 28|13@1+ (3.000000,-12279.000000) [-12279.000000|12279.000000] "Unit_None" ICAS1_Gateway
 SG_ TS_MomRad_Soll_Summe  : 41|13@1+ (3.000000,-12279.000000) [-12279.000000|12279.000000] "Unit_None" ICAS1_Gateway
 SG_ TS_MomRad_Wunsch  : 54|13@1+ (3.000000,-12279.000000) [-12279.000000|12279.000000] "Unit_None" ICAS1_Gateway
 SG_ TS_MomRad_Wunsch_sek  : 67|13@1+ (3.000000,-12279.000000) [-12279.000000|12279.000000] "Unit_None" ICAS1_Gateway
 SG_ TS_MomRad_verfuegb_max  : 80|12@1+ (3.000000,0.000000) [0.000000|12279.000000] "Unit_None" ICAS1_Gateway
 SG_ TS_MomRad_verfuegb_max_sek  : 92|12@1+ (3.000000,0.000000) [0.000000|12279.000000] "Unit_None" ICAS1_Gateway
 SG_ TS_MomRad_verfuegb_maxReku  : 104|12@1+ (3.000000,-12279.000000) [-12279.000000|0.000000] "Unit_None" ICAS1_Gateway
 SG_ TS_MomRad_verfuegb_maxReku_sek  : 116|12@1+ (3.000000,-12279.000000) [-12279.000000|0.000000] "Unit_None" ICAS1_Gateway
 SG_ TS_MomRad_Ist_sek  : 128|13@1+ (3.000000,-12279.000000) [-12279.000000|12279.000000] "Unit_None" ICAS1_Gateway
 SG_ TS_Allrad_Anteil_sek  : 141|9@1+ (0.200000,0.000000) [0.000000|100.000000] "Unit_PerCent" ICAS1_Gateway
 SG_ FDR_Allrad_Anteil_max_sek  : 150|9@1+ (0.200000,0.000000) [0.000000|100.000000] "Unit_PerCent" ICAS1_Gateway
 SG_ FDR_Allrad_Anteil_min_sek  : 159|9@1+ (0.200000,0.000000) [0.000000|100.000000] "Unit_PerCent" ICAS1_Gateway
 SG_ FDR_MomRad_Eingriff  : 168|13@1+ (3.000000,-12279.000000) [-12279.000000|12279.000000] "Unit_NewtoMeter" ICAS1_Gateway
 SG_ FDR_Status_Eingriff  : 181|1@1+ (1.000000,0.000000) [0.000000|1.000000] "" ICAS1_Gateway
 SG_ FDR_MomRad_Eingriff_sek  : 182|13@1+ (3.000000,-12279.000000) [-12279.000000|12279.000000] "Unit_NewtoMeter" ICAS1_Gateway
 SG_ FDR_Status_Eingriff_sek  : 195|1@1+ (1.000000,0.000000) [0.000000|1.000000] "" ICAS1_Gateway

BU_:  Airbag BAP_Tester ICAS1_Gateway ICAS1_KommunikationsServer LE1 LE2 Motor_BEV Schaltbetaetigung

BO_ 967 Motor_26: 8 Motor_BEV
 SG_ MO_Kuehlerluefter_MUX M : 0|1@1+ (1.000000,0.000000) [0.000000|1.000000] "siema ooo" ICAS1_Gateway
 SG_ MO_Kuehlerluefter_1 m0 : 1|7@1+ (1.000000,0.000000) [0.000000|100.000000] "Unit_PerCent" ICAS1_Gateway
 SG_ MO_Kuehlerluefter_2 m1 : 1|7@1+ (1.000000,0.000000) [0.000000|100.000000] "Unit_PerCent" ICAS1_Gateway
 SG_ MO_EFLEX_Lampe  : 8|2@1+ (1.000000,0.000000) [0.000000|3.000000] "" ICAS1_Gateway
 SG_ MO_KJS_nicht_bereit  : 10|1@1+ (1.000000,0.000000) [0.000000|1.000000] "" ICAS1_Gateway
 SG_ MO_ITM_Warnung_Pumpe  : 11|1@1+ (1.000000,0.000000) [0.000000|1.000000] "" ICAS1_Gateway
 SG_ WIV_Anzeige_aktiv  : 12|1@1+ (1.000000,0.000000) [0.000000|1.000000] "" ICAS1_Gateway
 SG_ WIV_Oelmin_Warn  : 13|1@1+ (1.000000,0.000000) [0.000000|1.000000] "" ICAS1_Gateway
 SG_ WIV_Sensorfehler  : 14|1@1+ (1.000000,0.000000) [0.000000|1.000000] "" ICAS1_Gateway
 SG_ WIV_Schieflage  : 15|1@1+ (1.000000,0.000000) [0.000000|1.000000] "" ICAS1_Gateway
 SG_ WIV_Oelstand  : 16|4@1+ (12.500000,0.000000) [0.000000|100.000000] "Unit_PerCent" ICAS1_Gateway
 SG_ MO_Zustand_HWP  : 20|2@1+ (1.000000,0.000000) [0.000000|3.000000] "" ICAS1_Gateway
 SG_ OLEV_Systemstoerung  : 22|1@1+ (1.000000,0.000000) [0.000000|1.000000] "" ICAS1_Gateway
 SG_ MO_Oelwarnung_max  : 23|1@1+ (1.000000,0.000000) [0.000000|1.000000] "" ICAS1_Gateway
 SG_ WIV_Oelsystem_aktiv  : 24|1@1+ (1.000000,0.000000) [0.000000|1.000000] "" ICAS1_Gateway
 SG_ WIV_nicht_betriebswarm  : 25|1@1+ (1.000000,0.000000) [0.000000|1.000000] "" ICAS1_Gateway
 SG_ WIV_Ueberfuell_Warn  : 26|1@1+ (1.000000,0.000000) [0.000000|1.000000] "" ICAS1_Gateway
 SG_ WIV_laufender_Motor  : 27|1@1+ (1.000000,0.000000) [0.000000|1.000000] "" ICAS1_Gateway
 SG_ MO_E_Warnungen  : 28|4@1+ (1.000000,0.000000) [0.000000|15.000000] "" ICAS1_Gateway
 SG_ MO_Text_Motorstart  : 32|4@1+ (1.000000,0.000000) [0.000000|15.000000] "" ICAS1_Gateway
 SG_ MO_E_Texte  : 36|4@1+ (1.000000,0.000000) [0.000000|15.000000] "" ICAS1_Gateway
 SG_ WIV_Oeldyn_avl  : 40|1@1+ (1.000000,0.000000) [0.000000|1.000000] "" ICAS1_Gateway
 SG_ MO_Text_Partikelfil_Reg  : 41|1@1+ (1.000000,0.000000) [0.000000|1.000000] "" ICAS1_Gateway
 SG_ OLEV_Oelstand_nicht_vorhanden  : 42|1@1+ (1.000000,0.000000) [0.000000|1.000000] "" ICAS1_Gateway
 SG_ WIV_Oelmenge  : 43|5@1+ (125.000000,0.000000) [0.000000|3875.000000] "Unit_MilliLiter" ICAS1_Gateway
 SG_ MO_Systemlampe  : 48|1@1+ (1.000000,0.000000) [0.000000|1.000000] "" ICAS1_Gateway
 SG_ MO_OBD2_Lampe  : 49|1@1+ (1.000000,0.000000) [0.000000|1.000000] "" ICAS1_Gateway
 SG_ MO_Heissleuchte  : 50|1@1+ (1.000000,0.000000) [0.000000|1.000000] "" ICAS1_Gateway
 SG_ MO_Partikel_Lampe  : 51|1@1+ (1.000000,0.000000) [0.000000|1.000000] "" ICAS1_Gateway
 SG_ MO_RedFahrleistung_Lampe  : 52|1@1+ (1.000000,0.000000) [0.000000|1.000000] "" ICAS1_Gateway ICAS1_KommunikationsServer
 SG_ WIV_Oelstand_nicht_vorhanden  : 53|1@1+ (1.000000,0.000000) [0.000000|1.000000] "" ICAS1_Gateway
 SG_ WIV_nachfuellanzeige_ein  : 54|1@1+ (1.000000,0.000000) [0.000000|1.000000] "" ICAS1_Gateway
 SG_ WIV_Ueberfuell_deaktiv  : 55|1@1+ (1.000000,0.000000) [0.000000|1.000000] "" ICAS1_Gateway
 SG_ WIV_Unterfuell_Warn  : 56|1@1+ (1.000000,0.000000) [0.000000|1.000000] "" ICAS1_Gateway
 SG_ MO_Tankdeckel_Lampe  : 57|1@1+ (1.000000,0.000000) [0.000000|1.000000] "" ICAS1_Gateway
 SG_ MO_Text_Tankdeckelwarn  : 58|1@1+ (1.000000,0.000000) [0.000000|1.000000] "" ICAS1_Gateway
 SG_ MO_Vorglueh_Lampe  : 59|1@1+ (1.000000,0.000000) [0.000000|1.000000] "" ICAS1_Gateway
 SG_ WIV_Oeldr_Warn_Motor  : 60|1@1+ (1.000000,0.000000) [0.000000|1.000000] "" ICAS1_Gateway
 SG_ MO_E_Mode  : 61|3@1+ (1.000000,0.000000) [0.000000|7.000000] "" ICAS1_Gateway

BO_ 706 Motor_41: 8 Motor_BEV
 SG_ MO_Anzeige_StSt_Text  : 12|4@1+ (1.000000,0.000000) [0.000000|15.000000] "" Vector__XXX
 SG_ MO_Anzeige_StSt_Symbol  : 16|3@1+ (1.000000,0.000000) [0.000000|7.000000] "" Vector__XXX
 SG_ MO_ADR_Status  : 19|2@1+ (1.000000,0.000000) [0.000000|3.000000] "" Vector__XXX
 SG_ MO_AGA_Sound_Texte  : 21|2@1+ (1.000000,0.000000) [0.000000|3.000000] "" Vector__XXX
 SG_ MO_Anzeige_FMAus_Text  : 23|1@1+ (1.000000,0.000000) [0.000000|1.000000] "" Vector__XXX
 SG_ PEA_Texte  : 25|3@1+ (1.000000,0.000000) [0.000000|7.000000] "" Vector__XXX
 SG_ TSK_Ueberstimmt_vMax_FahrerInfo  : 28|2@1+ (1.000000,0.000000) [0.000000|3.000000] "" Vector__XXX
 SG_ MO_Rekuperationsstufe  : 32|3@1+ (1.000000,0.000000) [0.000000|7.000000] "" ICAS1_KommunikationsServer
 SG_ TSK_Einheit_vMax_FahrerInfo  : 35|1@1+ (1.000000,0.000000) [0.000000|1.000000] "" ICAS1_KommunikationsServer
 SG_ TSK_Status_vMax_FahrerInfo  : 36|2@1+ (1.000000,0.000000) [0.000000|3.000000] "" ICAS1_KommunikationsServer
 SG_ MO_Anz_Kuehlerluefter  : 47|3@1+ (1.000000,0.000000) [0.000000|7.000000] "" Vector__XXX
 SG_ FDR_Warnung_ALR  : 50|2@1+ (1.000000,0.000000) [0.000000|3.000000] "" ICAS1_KommunikationsServer
 SG_ TSK_vMax_FahrerInfo  : 56|8@1+ (1.000000,15.000000) [16.000000|270.000000] "" ICAS1_KommunikationsServer

BO_ 267 Motor_51: 32 Motor_BEV
 SG_ Motor_51_CRC  : 0|8@1+ (1.000000,0.000000) [0.000000|255.000000] "" ICAS1_Gateway
 SG_ Motor_51_BZ  : 8|4@1+ (1.000000,0.000000) [0.000000|15.000000] "" ICAS1_Gateway
 SG_ MO_Fahrpedalrohwert_01  : 12|8@1+ (0.400000,0.000000) [0.000000|101.600000] "Unit_PerCent" Airbag ICAS1_Gateway
 SG_ MO_QBit_Fahrpedalwerte_01  : 20|1@1+ (1.000000,0.000000) [0.000000|1.000000] "" Airbag ICAS1_Gateway
 SG_ MO_Fahrpedalgradient  : 21|8@1+ (25.000000,0.000000) [0.000000|6350.000000] "Unit_PerCentPerSecon" ICAS1_Gateway
 SG_ MO_Sig_Fahrpedalgradient  : 29|1@1+ (1.000000,0.000000) [0.000000|1.000000] "" ICAS1_Gateway
 SG_ MO_rel_Saugrohrdruck  : 30|6@1+ (18.000000,0.000000) [0.000000|1116.000000] "Unit_MilliBar" ICAS1_Gateway
 SG_ MO_rel_Saugrohrdruck_gem_err  : 36|1@1+ (1.000000,0.000000) [0.000000|1.000000] "" ICAS1_Gateway
 SG_ MO_Moment_im_Leerlauf  : 37|1@1+ (1.000000,0.000000) [0.000000|1.000000] "" ICAS1_Gateway
 SG_ MO_Schubabschaltung  : 38|1@1+ (1.000000,0.000000) [0.000000|1.000000] "" ICAS1_Gateway
 SG_ MO_Solldrehz_Leerlauf  : 40|8@1+ (10.000000,0.000000) [0.000000|2540.000000] "Unit_MinutInver" ICAS1_Gateway
 SG_ MO_Entkopplung_Sollschlupf  : 48|7@1+ (20.000000,0.000000) [0.000000|2480.000000] "Unit_MinutInver" ICAS1_Gateway
 SG_ MO_temporaere_Fahrerabwesenheit  : 55|1@1+ (1.000000,0.000000) [0.000000|1.000000] "" ICAS1_Gateway
 SG_ TSK_a_Soll_gradientenbegrenzt  : 57|7@1+ (0.100000,-7.200000) [-7.200000|5.400000] "Unit_MeterPerSeconSquar" ICAS1_Gateway
 SG_ TSK_Radbremsmom  : 76|12@1+ (8.000000,0.000000) [0.000000|32760.000000] "Unit_NewtoMeter" ICAS1_Gateway
 SG_ TSK_Status  : 88|3@1+ (1.000000,0.000000) [0.000000|7.000000] "" ICAS1_Gateway
 SG_ TSK_v_Begrenzung_aktiv  : 91|1@1+ (1.000000,0.000000) [0.000000|1.000000] "" ICAS1_Gateway
 SG_ TSK_Standby_Anf_ESP  : 92|1@1+ (1.000000,0.000000) [0.000000|1.000000] "" ICAS1_Gateway
 SG_ TSK_Freig_WU  : 93|1@1+ (1.000000,0.000000) [0.000000|1.000000] "" ICAS1_Gateway
 SG_ TSK_Freig_Verzoeg_Anf  : 94|1@1+ (1.000000,0.000000) [0.000000|1.000000] "" ICAS1_Gateway
 SG_ TSK_Limiter_ausgewaehlt  : 95|1@1+ (1.000000,0.000000) [0.000000|1.000000] "" ICAS1_Gateway
 SG_ TSK_Wunsch_Uebersetz  : 96|10@1+ (0.024500,0.000000) [0.024500|25.063500] "" ICAS1_Gateway
 SG_ TSK_Hauptschalter_GRA_ACC  : 106|2@1+ (1.000000,0.000000) [0.000000|3.000000] "" ICAS1_Gateway ICAS1_KommunikationsServer
 SG_ TSK_SRBM_Anf_ASIL  : 108|3@1+ (1.000000,0.000000) [0.000000|7.000000] "" ICAS1_Gateway
 SG_ TSK_ax_Getriebe_02  : 112|9@1+ (0.024000,-2.016000) [-2.016000|10.224000] "Unit_MeterPerSeconSquar" ICAS1_Gateway
 SG_ TSK_Zwangszusch_ESP  : 121|1@1+ (1.000000,0.000000) [0.000000|1.000000] "" ICAS1_Gateway
 SG_ TSK_zul_Regelabw  : 122|6@1+ (0.024000,0.000000) [0.000000|1.512000] "Unit_MeterPerSeconSquar" ICAS1_Gateway
 SG_ MO_Status_MinDrzEingriff  : 235|3@1+ (1.000000,0.000000) [0.000000|7.000000] "" ICAS1_Gateway
 SG_ MO_Status_MaxDrzEingriff  : 238|3@1+ (1.000000,0.000000) [0.000000|7.000000] "" ICAS1_Gateway
 SG_ MO_Status_MinDrzEingriff_sek  : 241|3@1+ (1.000000,0.000000) [0.000000|7.000000] "" ICAS1_Gateway
 SG_ MO_Status_MaxDrzEingriff_sek  : 244|3@1+ (1.000000,0.000000) [0.000000|7.000000] "" ICAS1_Gateway
 SG_ GRA_KuFu_aktiv  : 247|1@1+ (1.000000,0.000000) [0.000000|1.000000] "" ICAS1_Gateway
 SG_ TSK_SRBM_max_Gradient  : 248|7@1+ (50.000000,0.000000) [0.000000|6250.000000] "Unit_NewtoMeterPerSecon" ICAS1_Gateway
 SG_ LIM_KuFu_aktiv  : 255|1@1+ (1.000000,0.000000) [0.000000|1.000000] "" ICAS1_Gateway

BO_ 330 Motor_52: 32 Motor_BEV
 SG_ MO_Hochschaltdrehz  : 21|12@1+ (3.000000,0.000000) [3.000000|12282.000000] "Unit_MinutInver" Vector__XXX
 SG_ MO_Anzeige_Verbr_Einheit  : 33|2@1+ (1.000000,0.000000) [0.000000|3.000000] "" Vector__XXX
 SG_ MO_Schaltblitz_Anz  : 35|7@1+ (1.000000,0.000000) [0.000000|100.000000] "Unit_PerCent" Vector__XXX
 SG_ MO_Anzeige_Drehmoment  : 42|11@1+ (1.000000,0.000000) [0.000000|2045.000000] "Unit_NewtoMeter" Vector__XXX
 SG_ MO_Anzeige_Leistung  : 53|11@1+ (0.600000,0.000000) [0.000000|1227.000000] "Unit_KiloWatt" Vector__XXX
 SG_ MO_rel_Ladedruck  : 64|8@1+ (0.400000,0.000000) [0.000000|100.000000] "Unit_PerCent" Vector__XXX
 SG_ MO_Istgang  : 72|4@1+ (1.000000,0.000000) [0.000000|15.000000] "" Vector__XXX
 SG_ MO_Sollgang  : 76|4@1+ (1.000000,0.000000) [0.000000|15.000000] "" Vector__XXX
 SG_ MO_Oeldruck  : 80|8@1+ (0.040000,0.000000) [0.000000|10.000000] "Unit_Bar" Vector__XXX
 SG_ MO_Anzeigedrehz  : 88|12@1+ (3.000000,0.000000) [0.000000|12282.000000] "Unit_MinutInver" Vector__XXX
 SG_ MO_Effizienzmodus  : 100|1@1+ (1.000000,0.000000) [0.000000|1.000000] "" Vector__XXX
 SG_ MO_Fehler_Oeldrucksensor  : 101|1@1+ (1.000000,0.000000) [0.000000|1.000000] "" Vector__XXX
 SG_ MO_Schaltempf_verfbar  : 102|1@1+ (1.000000,0.000000) [0.000000|1.000000] "" Vector__XXX
 SG_ MO_Ladedruck  : 103|9@1+ (0.010000,0.000000) [0.000000|5.100000] "Unit_Bar" Vector__XXX
 SG_ MO_KVS  : 112|15@1+ (1.000000,0.000000) [0.000000|32767.000000] "Unit_MicroLiter" Vector__XXX
 SG_ MO_KVS_Ueberlauf  : 127|1@1+ (1.000000,0.000000) [0.000000|1.000000] "" Vector__XXX
 SG_ MO_ePowermeter  : 128|8@1+ (0.400000,-0.400000) [0.000000|100.800000] "Unit_PerCent" Vector__XXX
 SG_ MO_ePerformance  : 136|8@1+ (0.400000,-0.400000) [0.000000|100.800000] "Unit_PerCent" ICAS1_KommunikationsServer
 SG_ MO_Zust_Antrieb  : 144|4@1+ (1.000000,0.000000) [0.000000|15.000000] "" Vector__XXX
 SG_ MO_Zust_Betriebsstrategie  : 148|3@1+ (1.000000,0.000000) [0.000000|7.000000] "" Vector__XXX
 SG_ Ladezustand_02  : 152|8@1+ (0.500000,0.000000) [0.000000|100.000000] "Unit_PerCent" ICAS1_Gateway ICAS1_KommunikationsServer
 SG_ MO_Powermeter_Elm_02  : 168|12@1+ (0.050000,-102.400000) [-100.000000|100.000000] "Unit_PerCent" Vector__XXX
 SG_ MO_Powermeter  : 180|12@1+ (1.000000,0.000000) [0.000000|4092.000000] "" ICAS1_KommunikationsServer

BO_ 512 Motor_53: 32 Motor_BEV
 SG_ TSK_Wunschgeschw  : 12|10@1+ (0.320000,0.000000) [0.000000|326.720000] "Unit_KiloMeterPerHour" ICAS1_Gateway ICAS1_KommunikationsServer
 SG_ TSK_praediktiver_Hinweis  : 22|3@1+ (1.000000,0.000000) [0.000000|7.000000] "" ICAS1_Gateway
 SG_ TSK_naechstes_Event  : 25|6@1+ (1.000000,0.000000) [0.000000|63.000000] "" ICAS1_Gateway
 SG_ TSK_Fahrzeugstatus_praed_Fkt  : 31|3@1+ (1.000000,0.000000) [0.000000|7.000000] "" ICAS1_Gateway
 SG_ TSK_Texte  : 40|5@1+ (1.000000,0.000000) [0.000000|31.000000] "" ICAS1_Gateway ICAS1_KommunikationsServer
 SG_ TSK_Akustik  : 45|3@1+ (1.000000,0.000000) [0.000000|7.000000] "" ICAS1_Gateway ICAS1_KommunikationsServer
 SG_ TSK_Texte_Primaeranz  : 48|5@1+ (1.000000,0.000000) [0.000000|31.000000] "" ICAS1_Gateway ICAS1_KommunikationsServer
 SG_ TSK_Limiter_Fahrerinfo  : 53|2@1+ (1.000000,0.000000) [0.000000|3.000000] "" ICAS1_Gateway ICAS1_KommunikationsServer
 SG_ TSK_Limiter_Anzeige  : 55|1@1+ (1.000000,0.000000) [0.000000|1.000000] "" ICAS1_Gateway ICAS1_KommunikationsServer
 SG_ TSK_Fahrzeugstatus_GRA  : 56|1@1+ (1.000000,0.000000) [0.000000|1.000000] "" ICAS1_Gateway ICAS1_KommunikationsServer
 SG_ TSK_Fahrzeugstatus_Limiter  : 57|1@1+ (1.000000,0.000000) [0.000000|1.000000] "" ICAS1_Gateway ICAS1_KommunikationsServer
 SG_ MO_Motorlaufwarnung  : 58|1@1+ (1.000000,0.000000) [0.000000|1.000000] "" ICAS1_Gateway
 SG_ TSK_naechstes_Event_Einheit  : 60|1@1+ (1.000000,0.000000) [0.000000|1.000000] "" ICAS1_Gateway
 SG_ TSK_Status_Anzeige  : 61|3@1+ (1.000000,0.000000) [0.000000|7.000000] "" ICAS1_Gateway ICAS1_KommunikationsServer
 SG_ MO_Sperrung_FahrPr_BZS  : 64|8@1+ (1.000000,0.000000) [0.000000|255.000000] "" ICAS1_Gateway
 SG_ MO_Rampenzeit_Generator_Anf  : 72|4@1+ (1.000000,0.000000) [0.000000|15.000000] "" ICAS1_Gateway
 SG_ MO_Prio_MAX_Wunschdrehzahl  : 76|1@1+ (1.000000,0.000000) [0.000000|1.000000] "" ICAS1_Gateway
 SG_ MO_Prio_MIN_Wunschdrehzahl  : 77|1@1+ (1.000000,0.000000) [0.000000|1.000000] "" ICAS1_Gateway
 SG_ MO_Luftpfad_aktiv  : 78|1@1+ (1.000000,0.000000) [0.000000|1.000000] "" ICAS1_Gateway
 SG_ MO_v_Begrenz_Aktivierbar  : 79|1@1+ (1.000000,0.000000) [0.000000|1.000000] "" ICAS1_Gateway
 SG_ MO_Drehzahlbeeinflussung  : 80|8@1+ (0.390000,0.000000) [0.000000|99.450000] "Unit_PerCent" ICAS1_Gateway
 SG_ MO_MIN_Wunschdrehzahl  : 88|8@1+ (25.000000,0.000000) [0.000000|6350.000000] "Unit_MinutInver" ICAS1_Gateway
 SG_ MO_MAX_Wunschdrehzahl  : 96|9@1+ (25.000000,0.000000) [0.000000|12750.000000] "Unit_MinutInver" ICAS1_Gateway
 SG_ MO_Charisma_FahrPr  : 105|4@1+ (1.000000,0.000000) [0.000000|15.000000] "" ICAS1_Gateway
 SG_ MO_Charisma_Status  : 109|2@1+ (1.000000,0.000000) [0.000000|3.000000] "" ICAS1_Gateway
 SG_ MO_StSt_Charisma_FahrPr  : 111|4@1+ (1.000000,0.000000) [0.000000|15.000000] "" ICAS1_Gateway
 SG_ MO_StSt_Charisma_Status  : 115|2@1+ (1.000000,0.000000) [0.000000|3.000000] "" ICAS1_Gateway
 SG_ MO_BZS_Charisma_FahrPr  : 117|4@1+ (1.000000,0.000000) [0.000000|15.000000] "" ICAS1_Gateway
 SG_ MO_BZS_Charisma_Status  : 121|2@1+ (1.000000,0.000000) [0.000000|3.000000] "" ICAS1_Gateway
 SG_ MO_NGS_Position  : 123|1@1+ (1.000000,0.000000) [0.000000|1.000000] "" ICAS1_Gateway
 SG_ MO_NGS_Status  : 124|2@1+ (1.000000,0.000000) [0.000000|3.000000] "" ICAS1_Gateway
 SG_ MO_v_Begrenzung_Niveau  : 126|2@1+ (1.000000,0.000000) [0.000000|3.000000] "" ICAS1_Gateway
 SG_ MO_Anzeige_Rekuperation  : 128|8@1+ (0.500000,-0.500000) [0.000000|100.000000] "Unit_PerCent" ICAS1_Gateway
 SG_ PEA_Fortschrittsanzeige  : 136|7@1+ (1.000000,0.000000) [0.000000|100.000000] "Unit_PerCent" ICAS1_Gateway
 SG_ MO_Anzeige_Fahrbereitschaft  : 143|1@1+ (1.000000,0.000000) [0.000000|1.000000] "" ICAS1_Gateway ICAS1_KommunikationsServer
 SG_ MO_Boost_verfuegbar  : 144|8@1+ (0.400000,-0.400000) [0.000000|100.400000] "Unit_PerCent" ICAS1_Gateway
 SG_ MO_Overboost  : 152|1@1+ (1.000000,0.000000) [0.000000|1.000000] "" ICAS1_Gateway
 SG_ MO_Boost_aktiv  : 153|1@1+ (1.000000,0.000000) [0.000000|1.000000] "" ICAS1_Gateway
 SG_ MO_Anzeige_Betriebsmodus  : 154|4@1+ (1.000000,0.000000) [0.000000|15.000000] "" ICAS1_Gateway
 SG_ PEA_Hinweis  : 158|2@1+ (1.000000,0.000000) [0.000000|3.000000] "" ICAS1_Gateway
 SG_ PEA_Ereignisanzeige  : 160|5@1+ (1.000000,0.000000) [0.000000|31.000000] "" ICAS1_Gateway
 SG_ PEA_Ereignisanzeige_temporaer  : 165|1@1+ (1.000000,0.000000) [0.000000|1.000000] "" ICAS1_Gateway
 SG_ PEA_Abschalttexte  : 166|2@1+ (1.000000,0.000000) [0.000000|3.000000] "" ICAS1_Gateway
 SG_ PEA_Zielgeschw_Einheit  : 168|1@1+ (1.000000,0.000000) [0.000000|1.000000] "" ICAS1_Gateway
 SG_ PEA_Zielgeschw  : 169|5@1+ (1.000000,0.000000) [0.000000|31.000000] "" ICAS1_Gateway
 SG_ MO_Antriebsstrang_Warnung_HS  : 174|2@1+ (1.000000,0.000000) [0.000000|3.000000] "" ICAS1_Gateway
 SG_ MO_Anzeige_Verbrauch_oE  : 176|16@1+ (0.005000,0.000000) [0.000000|327.675000] "Unit_None" ICAS1_Gateway

BO_ 332 Motor_54: 32 Motor_BEV
 SG_ MO_Anforderung_HMS  : 12|3@1+ (1.000000,0.000000) [0.000000|7.000000] "" ICAS1_Gateway
 SG_ FoD_DTC_TSK_GRA  : 15|1@1+ (1.000000,0.000000) [0.000000|1.000000] "" ICAS1_Gateway
 SG_ TSK_vMax_aktuell  : 16|8@1+ (1.000000,0.000000) [0.000000|253.000000] "Unit_KiloMeterPerHour" ICAS1_Gateway
 SG_ TSK_Status_EA  : 32|3@1+ (1.000000,0.000000) [0.000000|7.000000] "" ICAS1_Gateway
 SG_ FoD_DTC_TSK_ACC  : 35|1@1+ (1.000000,0.000000) [0.000000|1.000000] "" ICAS1_Gateway
 SG_ TSK_ACC_FoD_Status  : 36|2@1+ (1.000000,0.000000) [0.000000|3.000000] "" ICAS1_Gateway
 SG_ TSK_GRA_FoD_Status  : 38|2@1+ (1.000000,0.000000) [0.000000|3.000000] "" ICAS1_Gateway
 SG_ TSK_vMax_Fahrerassistenz  : 40|9@1+ (1.000000,0.000000) [0.000000|510.000000] "" ICAS1_Gateway
 SG_ TSK_Einheit_vMax_Fahrerassistenz  : 49|1@1+ (1.000000,0.000000) [0.000000|1.000000] "" ICAS1_Gateway
 SG_ TSK_Status_PLA  : 50|3@1+ (1.000000,0.000000) [0.000000|7.000000] "" ICAS1_Gateway
 SG_ TSK_aktives_System  : 53|3@1+ (1.000000,0.000000) [0.000000|7.000000] "" ICAS1_Gateway
 SG_ TSK_erhoehter_Fahrwiderstand  : 56|1@1+ (1.000000,0.000000) [0.000000|1.000000] "" ICAS1_Gateway
 SG_ TSK_Anf_Antriebsmoment  : 57|1@1+ (1.000000,0.000000) [0.000000|1.000000] "" ICAS1_Gateway
 SG_ TSK_Status_ARA  : 58|3@1+ (1.000000,0.000000) [0.000000|7.000000] "" ICAS1_Gateway
 SG_ TSK_Status_IPA  : 61|3@1+ (1.000000,0.000000) [0.000000|7.000000] "" ICAS1_Gateway
 SG_ MO_Fahrbereitschaft  : 76|2@1+ (1.000000,0.000000) [0.000000|3.000000] "" ICAS1_Gateway LE1 LE2
 SG_ MO_Freilauf_Info  : 78|2@1+ (1.000000,0.000000) [0.000000|3.000000] "" ICAS1_Gateway
 SG_ MO_Krit_Heckobjekt  : 81|3@1+ (1.000000,0.000000) [0.000000|7.000000] "" ICAS1_Gateway
 SG_ MO_NGS_Gangpos  : 84|3@1+ (1.000000,0.000000) [0.000000|7.000000] "" ICAS1_Gateway
 SG_ MO_Freilauf_Status  : 87|3@1+ (1.000000,0.000000) [0.000000|7.000000] "" ICAS1_Gateway
 SG_ MO_EBoost_verf_praed  : 90|2@1+ (1.000000,0.000000) [0.000000|3.000000] "" ICAS1_Gateway
 SG_ MO_Heckspoiler_Anf  : 92|1@1+ (1.000000,0.000000) [0.000000|1.000000] "" ICAS1_Gateway
 SG_ MO_eLaunch_verf  : 93|2@1+ (1.000000,0.000000) [0.000000|3.000000] "" ICAS1_Gateway
 SG_ MO_Positionierung_aktiv  : 95|1@1+ (1.000000,0.000000) [0.000000|1.000000] "" ICAS1_Gateway
 SG_ MO_Freilauf_Typ  : 98|2@1+ (1.000000,0.000000) [0.000000|3.000000] "" ICAS1_Gateway
 SG_ MO_Startwunsch  : 100|1@1+ (1.000000,0.000000) [0.000000|1.000000] "" ICAS1_Gateway
 SG_ OBD_Calc_Load_Val  : 128|8@1+ (0.392157,0.000000) [0.000000|100.000000] "Unit_PerCent" ICAS1_Gateway LE1 LE2
 SG_ OBD_Eng_Cool_Temp  : 136|8@1+ (1.000000,-40.000000) [-40.000000|215.000000] "Unit_DegreCelsi" ICAS1_Gateway LE1 LE2
 SG_ OBD_Abs_Throttle_Pos  : 144|8@1+ (0.392157,0.000000) [0.000000|100.000000] "Unit_PerCent" ICAS1_Gateway LE1 LE2
 SG_ OBD_Abs_Load_Val  : 152|16@1+ (0.392157,0.000000) [0.000000|25700.000000] "Unit_PerCent" ICAS1_Gateway LE1 LE2
 SG_ OBD_Abs_Pedal_Pos  : 168|8@1+ (0.392157,0.000000) [0.000000|100.000000] "Unit_PerCent" ICAS1_Gateway LE1 LE2
 SG_ MO_Servicemodus  : 176|4@1+ (1.000000,0.000000) [0.000000|15.000000] "" ICAS1_Gateway LE1 LE2
 SG_ OBD_ClearMem_Inhibit  : 183|1@1+ (1.000000,0.000000) [0.000000|1.000000] "" ICAS1_Gateway LE1 LE2
 SG_ OBD_Sperrung_Kaltstart_Denom  : 184|1@1+ (1.000000,0.000000) [0.000000|1.000000] "" ICAS1_Gateway LE1 LE2
 SG_ MO_QBit_Aussen_Temp  : 185|1@1+ (1.000000,0.000000) [0.000000|1.000000] "" ICAS1_Gateway
 SG_ OBD_Sperrung_IUMPR  : 186|1@1+ (1.000000,0.000000) [0.000000|1.000000] "" ICAS1_Gateway LE1 LE2
 SG_ OBD_Kaltstart_Denominator  : 187|1@1+ (1.000000,0.000000) [0.000000|1.000000] "" ICAS1_Gateway LE1 LE2
 SG_ OBD_Minimum_Trip  : 188|1@1+ (1.000000,0.000000) [0.000000|1.000000] "" ICAS1_Gateway LE1 LE2
 SG_ OBD_Driving_Cycle  : 189|1@1+ (1.000000,0.000000) [0.000000|1.000000] "" ICAS1_Gateway LE1 LE2
 SG_ OBD_Warm_Up_Cycle  : 190|1@1+ (1.000000,0.000000) [0.000000|1.000000] "" ICAS1_Gateway LE1 LE2
 SG_ OBD_Normed_Trip  : 191|1@1+ (1.000000,0.000000) [0.000000|1.000000] "" ICAS1_Gateway LE1 LE2
 SG_ OBD_Aussen_Temp_gef  : 248|8@1+ (1.000000,-40.000000) [-40.000000|213.000000] "Unit_DegreCelsi" ICAS1_Gateway

BO_ 246 Motor_55: 32 Motor_BEV
 SG_ Motor_55_CRC  : 0|8@1+ (1.000000,0.000000) [0.000000|255.000000] "" ICAS1_Gateway
 SG_ Motor_55_BZ  : 8|4@1+ (1.000000,0.000000) [0.000000|15.000000] "" ICAS1_Gateway
 SG_ TS_Faktor_Radmomente  : 12|2@1+ (1.000000,0.000000) [0.000000|3.000000] "" ICAS1_Gateway
 SG_ TS_Status_MomRad_Ist  : 14|2@1+ (1.000000,0.000000) [0.000000|3.000000] "" ICAS1_Gateway
 SG_ TS_MomRad_verfuegb_maxReku_Summe  : 16|12@1+ (3.000000,-12279.000000) [-12279.000000|0.000000] "" ICAS1_Gateway
 SG_ TS_MomRad_Ist  : 28|13@1+ (3.000000,-12279.000000) [-12279.000000|12279.000000] "Unit_None" ICAS1_Gateway
 SG_ TS_MomRad_Soll_Summe  : 41|13@1+ (3.000000,-12279.000000) [-12279.000000|12279.000000] "Unit_None" ICAS1_Gateway
 SG_ TS_MomRad_Wunsch  : 54|13@1+ (3.000000,-12279.000000) [-12279.000000|12279.000000] "Unit_None" ICAS1_Gateway
 SG_ TS_MomRad_Wunsch_sek  : 67|13@1+ (3.000000,-12279.000000) [-12279.000000|12279.000000] "Unit_None" ICAS1_Gateway
 SG_ TS_MomRad_verfuegb_max  : 80|12@1+ (3.000000,0.000000) [0.000000|12279.000000] "Unit_None" ICAS1_Gateway
 SG_ TS_MomRad_verfuegb_max_sek  : 92|12@1+ (3.000000,0.000000) [0.000000|12279.000000] "Unit_None" ICAS1_Gateway
 SG_ TS_MomRad_verfuegb_maxReku  : 104|12@1+ (3.000000,-12279.000000) [-12279.000000|0.000000] "Unit_None" ICAS1_Gateway
 SG_ TS_MomRad_verfuegb_maxReku_sek  : 116|12@1+ (3.000000,-12279.000000) [-12279.000000|0.000000] "Unit_None" ICAS1_Gateway
 SG_ TS_MomRad_Ist_sek  : 128|13@1+ (3.000000,-12279.000000) [-12279.000000|12279.000000] "Unit_None" ICAS1_Gateway
 SG_ TS_Allrad_Anteil_sek  : 141|9@1+ (0.200000,0.000000) [0.000000|100.000000] "Unit_PerCent" ICAS1_Gateway
 SG_ FDR_Allrad_Anteil_max_sek  : 150|9@1+ (0.200000,0.000000) [0.000000|100.000000] "Unit_PerCent" ICAS1_Gateway
 SG_ FDR_Allrad_Anteil_min_sek  : 159|9@1+ (0.200000,0.000000) [0.000000|100.000000] "Unit_PerCent" ICAS1_Gateway
 SG_ FDR_MomRad_Eingriff  : 168|13@1+ (3.000000,-12279.000000) [-12279.000000|12279.000000] "Unit_NewtoMeter" ICAS1_Gateway
 SG_ FDR_Status_Eingriff  : 181|1@1+ (1.000000,0.000000) [0.000000|1.000000] "" ICAS1_Gateway
 SG_ FDR_MomRad_Eingriff_sek  : 182|13@1+ (3.000000,-12279.000000) [-12279.000000|12279.000000] "Unit_NewtoMeter" ICAS1_Gateway
 SG_ FDR_Status_Eingriff_sek  : 195|1@1+ (1.000000,0.000000) [0.000000|1.000000] "" ICAS1_Gateway

BU_:  Airbag BAP_Tester ICAS1_Gateway ICAS1_KommunikationsServer LE1 LE2 Motor_BEV Schaltbetaetigung

BO_ 967 Motor_26: 8 Motor_BEV
 SG_ MO_Kuehlerluefter_MUX M : 0|1@1+ (1.000000,0.000000) [0.000000|1.000000] "siema ooo" ICAS1_Gateway
 SG_ MO_Kuehlerluefter_1 m0 : 1|7@1+ (1.000000,0.000000) [0.000000|100.000000] "Unit_PerCent" ICAS1_Gateway
 SG_ MO_Kuehlerluefter_2 m1 : 1|7@1+ (1.000000,0.000000) [0.000000|100.000000] "Unit_PerCent" ICAS1_Gateway
 SG_ MO_EFLEX_Lampe  : 8|2@1+ (1.000000,0.000000) [0.000000|3.000000] "" ICAS1_Gateway
 SG_ MO_KJS_nicht_bereit  : 10|1@1+ (1.000000,0.000000) [0.000000|1.000000] "" ICAS1_Gateway
 SG_ MO_ITM_Warnung_Pumpe  : 11|1@1+ (1.000000,0.000000) [0.000000|1.000000] "" ICAS1_Gateway
 SG_ WIV_Anzeige_aktiv  : 12|1@1+ (1.000000,0.000000) [0.000000|1.000000] "" ICAS1_Gateway
 SG_ WIV_Oelmin_Warn  : 13|1@1+ (1.000000,0.000000) [0.000000|1.000000] "" ICAS1_Gateway
 SG_ WIV_Sensorfehler  : 14|1@1+ (1.000000,0.000000) [0.000000|1.000000] "" ICAS1_Gateway
 SG_ WIV_Schieflage  : 15|1@1+ (1.000000,0.000000) [0.000000|1.000000] "" ICAS1_Gateway
 SG_ WIV_Oelstand  : 16|4@1+ (12.500000,0.000000) [0.000000|100.000000] "Unit_PerCent" ICAS1_Gateway
 SG_ MO_Zustand_HWP  : 20|2@1+ (1.000000,0.000000) [0.000000|3.000000] "" ICAS1_Gateway
 SG_ OLEV_Systemstoerung  : 22|1@1+ (1.000000,0.000000) [0.000000|1.000000] "" ICAS1_Gateway
 SG_ MO_Oelwarnung_max  : 23|1@1+ (1.000000,0.000000) [0.000000|1.000000] "" ICAS1_Gateway
 SG_ WIV_Oelsystem_aktiv  : 24|1@1+ (1.000000,0.000000) [0.000000|1.000000] "" ICAS1_Gateway
 SG_ WIV_nicht_betriebswarm  : 25|1@1+ (1.000000,0.000000) [0.000000|1.000000] "" ICAS1_Gateway
 SG_ WIV_Ueberfuell_Warn  : 26|1@1+ (1.000000,0.000000) [0.000000|1.000000] "" ICAS1_Gateway
 SG_ WIV_laufender_Motor  : 27|1@1+ (1.000000,0.000000) [0.000000|1.000000] "" ICAS1_Gateway
 SG_ MO_E_Warnungen  : 28|4@1+ (1.000000,0.000000) [0.000000|15.000000] "" ICAS1_Gateway
 SG_ MO_Text_Motorstart  : 32|4@1+ (1.000000,0.000000) [0.000000|15.000000] "" ICAS1_Gateway
 SG_ MO_E_Texte  : 36|4@1+ (1.000000,0.000000) [0.000000|15.000000] "" ICAS1_Gateway
 SG_ WIV_Oeldyn_avl  : 40|1@1+ (1.000000,0.000000) [0.000000|1.000000] "" ICAS1_Gateway
 SG_ MO_Text_Partikelfil_Reg  : 41|1@1+ (1.000000,0.000000) [0.000000|1.000000] "" ICAS1_Gateway
 SG_ OLEV_Oelstand_nicht_vorhanden  : 42|1@1+ (1.000000,0.000000) [0.000000|1.000000] "" ICAS1_Gateway
 SG_ WIV_Oelmenge  : 43|5@1+ (125.000000,0.000000) [0.000000|3875.000000] "Unit_MilliLiter" ICAS1_Gateway
 SG_ MO_Systemlampe  : 48|1@1+ (1.000000,0.000000) [0.000000|1.000000] "" ICAS1_Gateway
 SG_ MO_OBD2_Lampe  : 49|1@1+ (1.000000,0.000000) [0.000000|1.000000] "" ICAS1_Gateway
 SG_ MO_Heissleuchte  : 50|1@1+ (1.000000,0.000000) [0.000000|1.000000] "" ICAS1_Gateway
 SG_ MO_Partikel_Lampe  : 51|1@1+ (1.000000,0.000000) [0.000000|1.000000] "" ICAS1_Gateway
 SG_ MO_RedFahrleistung_Lampe  : 52|1@1+ (1.000000,0.000000) [0.000000|1.000000] "" ICAS1_Gateway ICAS1_KommunikationsServer
 SG_ WIV_Oelstand_nicht_vorhanden  : 53|1@1+ (1.000000,0.000000) [0.000000|1.000000] "" ICAS1_Gateway
 SG_ WIV_nachfuellanzeige_ein  : 54|1@1+ (1.000000,0.000000) [0.000000|1.000000] "" ICAS1_Gateway
 SG_ WIV_Ueberfuell_deaktiv  : 55|1@1+ (1.000000,0.000000) [0.000000|1.000000] "" ICAS1_Gateway
 SG_ WIV_Unterfuell_Warn  : 56|1@1+ (1.000000,0.000000) [0.000000|1.000000] "" ICAS1_Gateway
 SG_ MO_Tankdeckel_Lampe  : 57|1@1+ (1.000000,0.000000) [0.000000|1.000000] "" ICAS1_Gateway
 SG_ MO_Text_Tankdeckelwarn  : 58|1@1+ (1.000000,0.000000) [0.000000|1.000000] "" ICAS1_Gateway
 SG_ MO_Vorglueh_Lampe  : 59|1@1+ (1.000000,0.000000) [0.000000|1.000000] "" ICAS1_Gateway
 SG_ WIV_Oeldr_Warn_Motor  : 60|1@1+ (1.000000,0.000000) [0.000000|1.000000] "" ICAS1_Gateway
 SG_ MO_E_Mode  : 61|3@1+ (1.000000,0.000000) [0.000000|7.000000] "" ICAS1_Gateway

BO_ 706 Motor_41: 8 Motor_BEV
 SG_ MO_Anzeige_StSt_Text  : 12|4@1+ (1.000000,0.000000) [0.000000|15.000000] "" Vector__XXX
 SG_ MO_Anzeige_StSt_Symbol  : 16|3@1+ (1.000000,0.000000) [0.000000|7.000000] "" Vector__XXX
 SG_ MO_ADR_Status  : 19|2@1+ (1.000000,0.000000) [0.000000|3.000000] "" Vector__XXX
 SG_ MO_AGA_Sound_Texte  : 21|2@1+ (1.000000,0.000000) [0.000000|3.000000] "" Vector__XXX
 SG_ MO_Anzeige_FMAus_Text  : 23|1@1+ (1.000000,0.000000) [0.000000|1.000000] "" Vector__XXX
 SG_ PEA_Texte  : 25|3@1+ (1.000000,0.000000) [0.000000|7.000000] "" Vector__XXX
 SG_ TSK_Ueberstimmt_vMax_FahrerInfo  : 28|2@1+ (1.000000,0.000000) [0.000000|3.000000] "" Vector__XXX
 SG_ MO_Rekuperationsstufe  : 32|3@1+ (1.000000,0.000000) [0.000000|7.000000] "" ICAS1_KommunikationsServer
 SG_ TSK_Einheit_vMax_FahrerInfo  : 35|1@1+ (1.000000,0.000000) [0.000000|1.000000] "" ICAS1_KommunikationsServer
 SG_ TSK_Status_vMax_FahrerInfo  : 36|2@1+ (1.000000,0.000000) [0.000000|3.000000] "" ICAS1_KommunikationsServer
 SG_ MO_Anz_Kuehlerluefter  : 47|3@1+ (1.000000,0.000000) [0.000000|7.000000] "" Vector__XXX
 SG_ FDR_Warnung_ALR  : 50|2@1+ (1.000000,0.000000) [0.000000|3.000000] "" ICAS1_KommunikationsServer
 SG_ TSK_vMax_FahrerInfo  : 56|8@1+ (1.000000,15.000000) [16.000000|270.000000] "" ICAS1_KommunikationsServer

BO_ 267 Motor_51: 32 Motor_BEV
 SG_ Motor_51_CRC  : 0|8@1+ (1.000000,0.000000) [0.000000|255.000000] "" ICAS1_Gateway
 SG_ Motor_51_BZ  : 8|4@1+ (1.000000,0.000000) [0.000000|15.000000] "" ICAS1_Gateway
 SG_ MO_Fahrpedalrohwert_01  : 12|8@1+ (0.400000,0.000000) [0.000000|101.600000] "Unit_PerCent" Airbag ICAS1_Gateway
 SG_ MO_QBit_Fahrpedalwerte_01  : 20|1@1+ (1.000000,0.000000) [0.000000|1.000000] "" Airbag ICAS1_Gateway
 SG_ MO_Fahrpedalgradient  : 21|8@1+ (25.000000,0.000000) [0.000000|6350.000000] "Unit_PerCentPerSecon" ICAS1_Gateway
 SG_ MO_Sig_Fahrpedalgradient  : 29|1@1+ (1.000000,0.000000) [0.000000|1.000000] "" ICAS1_Gateway
 SG_ MO_rel_Saugrohrdruck  : 30|6@1+ (18.000000,0.000000) [0.000000|1116.000000] "Unit_MilliBar" ICAS1_Gateway
 SG_ MO_rel_Saugrohrdruck_gem_err  : 36|1@1+ (1.000000,0.000000) [0.000000|1.000000] "" ICAS1_Gateway
 SG_ MO_Moment_im_Leerlauf  : 37|1@1+ (1.000000,0.000000) [0.000000|1.000000] "" ICAS1_Gateway
 SG_ MO_Schubabschaltung  : 38|1@1+ (1.000000,0.000000) [0.000000|1.000000] "" ICAS1_Gateway
 SG_ MO_Solldrehz_Leerlauf  : 40|8@1+ (10.000000,0.000000) [0.000000|2540.000000] "Unit_MinutInver" ICAS1_Gateway
 SG_ MO_Entkopplung_Sollschlupf  : 48|7@1+ (20.000000,0.000000) [0.000000|2480.000000] "Unit_MinutInver" ICAS1_Gateway
 SG_ MO_temporaere_Fahrerabwesenheit  : 55|1@1+ (1.000000,0.000000) [0.000000|1.000000] "" ICAS1_Gateway
 SG_ TSK_a_Soll_gradientenbegrenzt  : 57|7@1+ (0.100000,-7.200000) [-7.200000|5.400000] "Unit_MeterPerSeconSquar" ICAS1_Gateway
 SG_ TSK_Radbremsmom  : 76|12@1+ (8.000000,0.000000) [0.000000|32760.000000] "Unit_NewtoMeter" ICAS1_Gateway
 SG_ TSK_Status  : 88|3@1+ (1.000000,0.000000) [0.000000|7.000000] "" ICAS1_Gateway
 SG_ TSK_v_Begrenzung_aktiv  : 91|1@1+ (1.000000,0.000000) [0.000000|1.000000] "" ICAS1_Gateway
 SG_ TSK_Standby_Anf_ESP  : 92|1@1+ (1.000000,0.000000) [0.000000|1.000000] "" ICAS1_Gateway
 SG_ TSK_Freig_WU  : 93|1@1+ (1.000000,0.000000) [0.000000|1.000000] "" ICAS1_Gateway
 SG_ TSK_Freig_Verzoeg_Anf  : 94|1@1+ (1.000000,0.000000) [0.000000|1.000000] "" ICAS1_Gateway
 SG_ TSK_Limiter_ausgewaehlt  : 95|1@1+ (1.000000,0.000000) [0.000000|1.000000] "" ICAS1_Gateway
 SG_ TSK_Wunsch_Uebersetz  : 96|10@1+ (0.024500,0.000000) [0.024500|25.063500] "" ICAS1_Gateway
 SG_ TSK_Hauptschalter_GRA_ACC  : 106|2@1+ (1.000000,0.000000) [0.000000|3.000000] "" ICAS1_Gateway ICAS1_KommunikationsServer
 SG_ TSK_SRBM_Anf_ASIL  : 108|3@1+ (1.000000,0.000000) [0.000000|7.000000] "" ICAS1_Gateway
 SG_ TSK_ax_Getriebe_02  : 112|9@1+ (0.024000,-2.016000) [-2.016000|10.224000] "Unit_MeterPerSeconSquar" ICAS1_Gateway
 SG_ TSK_Zwangszusch_ESP  : 121|1@1+ (1.000000,0.000000) [0.000000|1.000000] "" ICAS1_Gateway
 SG_ TSK_zul_Regelabw  : 122|6@1+ (0.024000,0.000000) [0.000000|1.512000] "Unit_MeterPerSeconSquar" ICAS1_Gateway
 SG_ MO_Status_MinDrzEingriff  : 235|3@1+ (1.000000,0.000000) [0.000000|7.000000] "" ICAS1_Gateway
 SG_ MO_Status_MaxDrzEingriff  : 238|3@1+ (1.000000,0.000000) [0.000000|7.000000] "" ICAS1_Gateway
 SG_ MO_Status_MinDrzEingriff_sek  : 241|3@1+ (1.000000,0.000000) [0.000000|7.000000] "" ICAS1_Gateway
 SG_ MO_Status_MaxDrzEingriff_sek  : 244|3@1+ (1.000000,0.000000) [0.000000|7.000000] "" ICAS1_Gateway
 SG_ GRA_KuFu_aktiv  : 247|1@1+ (1.000000,0.000000) [0.000000|1.000000] "" ICAS1_Gateway
 SG_ TSK_SRBM_max_Gradient  : 248|7@1+ (50.000000,0.000000) [0.000000|6250.000000] "Unit_NewtoMeterPerSecon" ICAS1_Gateway
 SG_ LIM_KuFu_aktiv  : 255|1@1+ (1.000000,0.000000) [0.000000|1.000000] "" ICAS1_Gateway

BO_ 330 Motor_52: 32 Motor_BEV
 SG_ MO_Hochschaltdrehz  : 21|12@1+ (3.000000,0.000000) [3.000000|12282.000000] "Unit_MinutInver" Vector__XXX
 SG_ MO_Anzeige_Verbr_Einheit  : 33|2@1+ (1.000000,0.000000) [0.000000|3.000000] "" Vector__XXX
 SG_ MO_Schaltblitz_Anz  : 35|7@1+ (1.000000,0.000000) [0.000000|100.000000] "Unit_PerCent" Vector__XXX
 SG_ MO_Anzeige_Drehmoment  : 42|11@1+ (1.000000,0.000000) [0.000000|2045.000000] "Unit_NewtoMeter" Vector__XXX
 SG_ MO_Anzeige_Leistung  : 53|11@1+ (0.600000,0.000000) [0.000000|1227.000000] "Unit_KiloWatt" Vector__XXX
 SG_ MO_rel_Ladedruck  : 64|8@1+ (0.400000,0.000000) [0.000000|100.000000] "Unit_PerCent" Vector__XXX
 SG_ MO_Istgang  : 72|4@1+ (1.000000,0.000000) [0.000000|15.000000] "" Vector__XXX
 SG_ MO_Sollgang  : 76|4@1+ (1.000000,0.000000) [0.000000|15.000000] "" Vector__XXX
 SG_ MO_Oeldruck  : 80|8@1+ (0.040000,0.000000) [0.000000|10.000000] "Unit_Bar" Vector__XXX
 SG_ MO_Anzeigedrehz  : 88|12@1+ (3.000000,0.000000) [0.000000|12282.000000] "Unit_MinutInver" Vector__XXX
 SG_ MO_Effizienzmodus  : 100|1@1+ (1.000000,0.000000) [0.000000|1.000000] "" Vector__XXX
 SG_ MO_Fehler_Oeldrucksensor  : 101|1@1+ (1.000000,0.000000) [0.000000|1.000000] "" Vector__XXX
 SG_ MO_Schaltempf_verfbar  : 102|1@1+ (1.000000,0.000000) [0.000000|1.000000] "" Vector__XXX
 SG_ MO_Ladedruck  : 103|9@1+ (0.010000,0.000000) [0.000000|5.100000] "Unit_Bar" Vector__XXX
 SG_ MO_KVS  : 112|15@1+ (1.000000,0.000000) [0.000000|32767.000000] "Unit_MicroLiter" Vector__XXX
 SG_ MO_KVS_Ueberlauf  : 127|1@1+ (1.000000,0.000000) [0.000000|1.000000] "" Vector__XXX
 SG_ MO_ePowermeter  : 128|8@1+ (0.400000,-0.400000) [0.000000|100.800000] "Unit_PerCent" Vector__XXX
 SG_ MO_ePerformance  : 136|8@1+ (0.400000,-0.400000) [0.000000|100.800000] "Unit_PerCent" ICAS1_KommunikationsServer
 SG_ MO_Zust_Antrieb  : 144|4@1+ (1.000000,0.000000) [0.000000|15.000000] "" Vector__XXX
 SG_ MO_Zust_Betriebsstrategie  : 148|3@1+ (1.000000,0.000000) [0.000000|7.000000] "" Vector__XXX
 SG_ Ladezustand_02  : 152|8@1+ (0.500000,0.000000) [0.000000|100.000000] "Unit_PerCent" ICAS1_Gateway ICAS1_KommunikationsServer
 SG_ MO_Powermeter_Elm_02  : 168|12@1+ (0.050000,-102.400000) [-100.000000|100.000000] "Unit_PerCent" Vector__XXX
 SG_ MO_Powermeter  : 180|12@1+ (1.000000,0.000000) [0.000000|4092.000000] "" ICAS1_KommunikationsServer

BO_ 512 Motor_53: 32 Motor_BEV
 SG_ TSK_Wunschgeschw  : 12|10@1+ (0.320000,0.000000) [0.000000|326.720000] "Unit_KiloMeterPerHour" ICAS1_Gateway ICAS1_KommunikationsServer
 SG_ TSK_praediktiver_Hinweis  : 22|3@1+ (1.000000,0.000000) [0.000000|7.000000] "" ICAS1_Gateway
 SG_ TSK_naechstes_Event  : 25|6@1+ (1.000000,0.000000) [0.000000|63.000000] "" ICAS1_Gateway
 SG_ TSK_Fahrzeugstatus_praed_Fkt  : 31|3@1+ (1.000000,0.000000) [0.000000|7.000000] "" ICAS1_Gateway
 SG_ TSK_Texte  : 40|5@1+ (1.000000,0.000000) [0.000000|31.000000] "" ICAS1_Gateway ICAS1_KommunikationsServer
 SG_ TSK_Akustik  : 45|3@1+ (1.000000,0.000000) [0.000000|7.000000] "" ICAS1_Gateway ICAS1_KommunikationsServer
 SG_ TSK_Texte_Primaeranz  : 48|5@1+ (1.000000,0.000000) [0.000000|31.000000] "" ICAS1_Gateway ICAS1_KommunikationsServer
 SG_ TSK_Limiter_Fahrerinfo  : 53|2@1+ (1.000000,0.000000) [0.000000|3.000000] "" ICAS1_Gateway ICAS1_KommunikationsServer
 SG_ TSK_Limiter_Anzeige  : 55|1@1+ (1.000000,0.000000) [0.000000|1.000000] "" ICAS1_Gateway ICAS1_KommunikationsServer
 SG_ TSK_Fahrzeugstatus_GRA  : 56|1@1+ (1.000000,0.000000) [0.000000|1.000000] "" ICAS1_Gateway ICAS1_KommunikationsServer
 SG_ TSK_Fahrzeugstatus_Limiter  : 57|1@1+ (1.000000,0.000000) [0.000000|1.000000] "" ICAS1_Gateway ICAS1_KommunikationsServer
 SG_ MO_Motorlaufwarnung  : 58|1@1+ (1.000000,0.000000) [0.000000|1.000000] "" ICAS1_Gateway
 SG_ TSK_naechstes_Event_Einheit  : 60|1@1+ (1.000000,0.000000) [0.000000|1.000000] "" ICAS1_Gateway
 SG_ TSK_Status_Anzeige  : 61|3@1+ (1.000000,0.000000) [0.000000|7.000000] "" ICAS1_Gateway ICAS1_KommunikationsServer
 SG_ MO_Sperrung_FahrPr_BZS  : 64|8@1+ (1.000000,0.000000) [0.000000|255.000000] "" ICAS1_Gateway
 SG_ MO_Rampenzeit_Generator_Anf  : 72|4@1+ (1.000000,0.000000) [0.000000|15.000000] "" ICAS1_Gateway
 SG_ MO_Prio_MAX_Wunschdrehzahl  : 76|1@1+ (1.000000,0.000000) [0.000000|1.000000] "" ICAS1_Gateway
 SG_ MO_Prio_MIN_Wunschdrehzahl  : 77|1@1+ (1.000000,0.000000) [0.000000|1.000000] "" ICAS1_Gateway
 SG_ MO_Luftpfad_aktiv  : 78|1@1+ (1.000000,0.000000) [0.000000|1.000000] "" ICAS1_Gateway
 SG_ MO_v_Begrenz_Aktivierbar  : 79|1@1+ (1.000000,0.000000) [0.000000|1.000000] "" ICAS1_Gateway
 SG_ MO_Drehzahlbeeinflussung  : 80|8@1+ (0.390000,0.000000) [0.000000|99.450000] "Unit_PerCent" ICAS1_Gateway
 SG_ MO_MIN_Wunschdrehzahl  : 88|8@1+ (25.000000,0.000000) [0.000000|6350.000000] "Unit_MinutInver" ICAS1_Gateway
 SG_ MO_MAX_Wunschdrehzahl  : 96|9@1+ (25.000000,0.000000) [0.000000|12750.000000] "Unit_MinutInver" ICAS1_Gateway
 SG_ MO_Charisma_FahrPr  : 105|4@1+ (1.000000,0.000000) [0.000000|15.000000] "" ICAS1_Gateway
 SG_ MO_Charisma_Status  : 109|2@1+ (1.000000,0.000000) [0.000000|3.000000] "" ICAS1_Gateway
 SG_ MO_StSt_Charisma_FahrPr  : 111|4@1+ (1.000000,0.000000) [0.000000|15.000000] "" ICAS1_Gateway
 SG_ MO_StSt_Charisma_Status  : 115|2@1+ (1.000000,0.000000) [0.000000|3.000000] "" ICAS1_Gateway
 SG_ MO_BZS_Charisma_FahrPr  : 117|4@1+ (1.000000,0.000000) [0.000000|15.000000] "" ICAS1_Gateway
 SG_ MO_BZS_Charisma_Status  : 121|2@1+ (1.000000,0.000000) [0.000000|3.000000] "" ICAS1_Gateway
 SG_ MO_NGS_Position  : 123|1@1+ (1.000000,0.000000) [0.000000|1.000000] "" ICAS1_Gateway
 SG_ MO_NGS_Status  : 124|2@1+ (1.000000,0.000000) [0.000000|3.000000] "" ICAS1_Gateway
 SG_ MO_v_Begrenzung_Niveau  : 126|2@1+ (1.000000,0.000000) [0.000000|3.000000] "" ICAS1_Gateway
 SG_ MO_Anzeige_Rekuperation  : 128|8@1+ (0.500000,-0.500000) [0.000000|100.000000] "Unit_PerCent" ICAS1_Gateway
 SG_ PEA_Fortschrittsanzeige  : 136|7@1+ (1.000000,0.000000) [0.000000|100.000000] "Unit_PerCent" ICAS1_Gateway
 SG_ MO_Anzeige_Fahrbereitschaft  : 143|1@1+ (1.000000,0.000000) [0.000000|1.000000] "" ICAS1_Gateway ICAS1_KommunikationsServer
 SG_ MO_Boost_verfuegbar  : 144|8@1+ (0.400000,-0.400000) [0.000000|100.400000] "Unit_PerCent" ICAS1_Gateway
 SG_ MO_Overboost  : 152|1@1+ (1.000000,0.000000) [0.000000|1.000000] "" ICAS1_Gateway
 SG_ MO_Boost_aktiv  : 153|1@1+ (1.000000,0.000000) [0.000000|1.000000] "" ICAS1_Gateway
 SG_ MO_Anzeige_Betriebsmodus  : 154|4@1+ (1.000000,0.000000) [0.000000|15.000000] "" ICAS1_Gateway
 SG_ PEA_Hinweis  : 158|2@1+ (1.000000,0.000000) [0.000000|3.000000] "" ICAS1_Gateway
 SG_ PEA_Ereignisanzeige  : 160|5@1+ (1.000000,0.000000) [0.000000|31.000000] "" ICAS1_Gateway
 SG_ PEA_Ereignisanzeige_temporaer  : 165|1@1+ (1.000000,0.000000) [0.000000|1.000000] "" ICAS1_Gateway
 SG_ PEA_Abschalttexte  : 166|2@1+ (1.000000,0.000000) [0.000000|3.000000] "" ICAS1_Gateway
 SG_ PEA_Zielgeschw_Einheit  : 168|1@1+ (1.000000,0.000000) [0.000000|1.000000] "" ICAS1_Gateway
 SG_ PEA_Zielgeschw  : 169|5@1+ (1.000000,0.000000) [0.000000|31.000000] "" ICAS1_Gateway
 SG_ MO_Antriebsstrang_Warnung_HS  : 174|2@1+ (1.000000,0.000000) [0.000000|3.000000] "" ICAS1_Gateway
 SG_ MO_Anzeige_Verbrauch_oE  : 176|16@1+ (0.005000,0.000000) [0.000000|327.675000] "Unit_None" ICAS1_Gateway

BO_ 332 Motor_54: 32 Motor_BEV
 SG_ MO_Anforderung_HMS  : 12|3@1+ (1.000000,0.000000) [0.000000|7.000000] "" ICAS1_Gateway
 SG_ FoD_DTC_TSK_GRA  : 15|1@1+ (1.000000,0.000000) [0.000000|1.000000] "" ICAS1_Gateway
 SG_ TSK_vMax_aktuell  : 16|8@1+ (1.000000,0.000000) [0.000000|253.000000] "Unit_KiloMeterPerHour" ICAS1_Gateway
 SG_ TSK_Status_EA  : 32|3@1+ (1.000000,0.000000) [0.000000|7.000000] "" ICAS1_Gateway
 SG_ FoD_DTC_TSK_ACC  : 35|1@1+ (1.000000,0.000000) [0.000000|1.000000] "" ICAS1_Gateway
 SG_ TSK_ACC_FoD_Status  : 36|2@1+ (1.000000,0.000000) [0.000000|3.000000] "" ICAS1_Gateway
 SG_ TSK_GRA_FoD_Status  : 38|2@1+ (1.000000,0.000000) [0.000000|3.000000] "" ICAS1_Gateway
 SG_ TSK_vMax_Fahrerassistenz  : 40|9@1+ (1.000000,0.000000) [0.000000|510.000000] "" ICAS1_Gateway
 SG_ TSK_Einheit_vMax_Fahrerassistenz  : 49|1@1+ (1.000000,0.000000) [0.000000|1.000000] "" ICAS1_Gateway
 SG_ TSK_Status_PLA  : 50|3@1+ (1.000000,0.000000) [0.000000|7.000000] "" ICAS1_Gateway
 SG_ TSK_aktives_System  : 53|3@1+ (1.000000,0.000000) [0.000000|7.000000] "" ICAS1_Gateway
 SG_ TSK_erhoehter_Fahrwiderstand  : 56|1@1+ (1.000000,0.000000) [0.000000|1.000000] "" ICAS1_Gateway
 SG_ TSK_Anf_Antriebsmoment  : 57|1@1+ (1.000000,0.000000) [0.000000|1.000000] "" ICAS1_Gateway
 SG_ TSK_Status_ARA  : 58|3@1+ (1.000000,0.000000) [0.000000|7.000000] "" ICAS1_Gateway
 SG_ TSK_Status_IPA  : 61|3@1+ (1.000000,0.000000) [0.000000|7.000000] "" ICAS1_Gateway
 SG_ MO_Fahrbereitschaft  : 76|2@1+ (1.000000,0.000000) [0.000000|3.000000] "" ICAS1_Gateway LE1 LE2
 SG_ MO_Freilauf_Info  : 78|2@1+ (1.000000,0.000000) [0.000000|3.000000] "" ICAS1_Gateway
 SG_ MO_Krit_Heckobjekt  : 81|3@1+ (1.000000,0.000000) [0.000000|7.000000] "" ICAS1_Gateway
 SG_ MO_NGS_Gangpos  : 84|3@1+ (1.000000,0.000000) [0.000000|7.000000] "" ICAS1_Gateway
 SG_ MO_Freilauf_Status  : 87|3@1+ (1.000000,0.000000) [0.000000|7.000000] "" ICAS1_Gateway
 SG_ MO_EBoost_verf_praed  : 90|2@1+ (1.000000,0.000000) [0.000000|3.000000] "" ICAS1_Gateway
 SG_ MO_Heckspoiler_Anf  : 92|1@1+ (1.000000,0.000000) [0.000000|1.000000] "" ICAS1_Gateway
 SG_ MO_eLaunch_verf  : 93|2@1+ (1.000000,0.000000) [0.000000|3.000000] "" ICAS1_Gateway
 SG_ MO_Positionierung_aktiv  : 95|1@1+ (1.000000,0.000000) [0.000000|1.000000] "" ICAS1_Gateway
 SG_ MO_Freilauf_Typ  : 98|2@1+ (1.000000,0.000000) [0.000000|3.000000] "" ICAS1_Gateway
 SG_ MO_Startwunsch  : 100|1@1+ (1.000000,0.000000) [0.000000|1.000000] "" ICAS1_Gateway
 SG_ OBD_Calc_Load_Val  : 128|8@1+ (0.392157,0.000000) [0.000000|100.000000] "Unit_PerCent" ICAS1_Gateway LE1 LE2
 SG_ OBD_Eng_Cool_Temp  : 136|8@1+ (1.000000,-40.000000) [-40.000000|215.000000] "Unit_DegreCelsi" ICAS1_Gateway LE1 LE2
 SG_ OBD_Abs_Throttle_Pos  : 144|8@1+ (0.392157,0.000000) [0.000000|100.000000] "Unit_PerCent" ICAS1_Gateway LE1 LE2
 SG_ OBD_Abs_Load_Val  : 152|16@1+ (0.392157,0.000000) [0.000000|25700.000000] "Unit_PerCent" ICAS1_Gateway LE1 LE2
 SG_ OBD_Abs_Pedal_Pos  : 168|8@1+ (0.392157,0.000000) [0.000000|100.000000] "Unit_PerCent" ICAS1_Gateway LE1 LE2
 SG_ MO_Servicemodus  : 176|4@1+ (1.000000,0.000000) [0.000000|15.000000] "" ICAS1_Gateway LE1 LE2
 SG_ OBD_ClearMem_Inhibit  : 183|1@1+ (1.000000,0.000000) [0.000000|1.000000] "" ICAS1_Gateway LE1 LE2
 SG_ OBD_Sperrung_Kaltstart_Denom  : 184|1@1+ (1.000000,0.000000) [0.000000|1.000000] "" ICAS1_Gateway LE1 LE2
 SG_ MO_QBit_Aussen_Temp  : 185|1@1+ (1.000000,0.000000) [0.000000|1.000000] "" ICAS1_Gateway
 SG_ OBD_Sperrung_IUMPR  : 186|1@1+ (1.000000,0.000000) [0.000000|1.000000] "" ICAS1_Gateway LE1 LE2
 SG_ OBD_Kaltstart_Denominator  : 187|1@1+ (1.000000,0.000000) [0.000000|1.000000] "" ICAS1_Gateway LE1 LE2
 SG_ OBD_Minimum_Trip  : 188|1@1+ (1.000000,0.000000) [0.000000|1.000000] "" ICAS1_Gateway LE1 LE2
 SG_ OBD_Driving_Cycle  : 189|1@1+ (1.000000,0.000000) [0.000000|1.000000] "" ICAS1_Gateway LE1 LE2
 SG_ OBD_Warm_Up_Cycle  : 190|1@1+ (1.000000,0.000000) [0.000000|1.000000] "" ICAS1_Gateway LE1 LE2
 SG_ OBD_Normed_Trip  : 191|1@1+ (1.000000,0.000000) [0.000000|1.000000] "" ICAS1_Gateway LE1 LE2
 SG_ OBD_Aussen_Temp_gef  : 248|8@1+ (1.000000,-40.000000) [-40.000000|213.000000] "Unit_DegreCelsi" ICAS1_Gateway

BO_ 246 Motor_55: 32 Motor_BEV
 SG_ Motor_55_CRC  : 0|8@1+ (1.000000,0.000000) [0.000000|255.000000] "" ICAS1_Gateway
 SG_ Motor_55_BZ  : 8|4@1+ (1.000000,0.000000) [0.000000|15.000000] "" ICAS1_Gateway
 SG_ TS_Faktor_Radmomente  : 12|2@1+ (1.000000,0.000000) [0.000000|3.000000] "" ICAS1_Gateway
 SG_ TS_Status_MomRad_Ist  : 14|2@1+ (1.000000,0.000000) [0.000000|3.000000] "" ICAS1_Gateway
 SG_ TS_MomRad_verfuegb_maxReku_Summe  : 16|12@1+ (3.000000,-12279.000000) [-12279.000000|0.000000] "" ICAS1_Gateway
 SG_ TS_MomRad_Ist  : 28|13@1+ (3.000000,-12279.000000) [-12279.000000|12279.000000] "Unit_None" ICAS1_Gateway
 SG_ TS_MomRad_Soll_Summe  : 41|13@1+ (3.000000,-12279.000000) [-12279.000000|12279.000000] "Unit_None" ICAS1_Gateway
 SG_ TS_MomRad_Wunsch  : 54|13@1+ (3.000000,-12279.000000) [-12279.000000|12279.000000] "Unit_None" ICAS1_Gateway
 SG_ TS_MomRad_Wunsch_sek  : 67|13@1+ (3.000000,-12279.000000) [-12279.000000|12279.000000] "Unit_None" ICAS1_Gateway
 SG_ TS_MomRad_verfuegb_max  : 80|12@1+ (3.000000,0.000000) [0.000000|12279.000000] "Unit_None" ICAS1_Gateway
 SG_ TS_MomRad_verfuegb_max_sek  : 92|12@1+ (3.000000,0.000000) [0.000000|12279.000000] "Unit_None" ICAS1_Gateway
 SG_ TS_MomRad_verfuegb_maxReku  : 104|12@1+ (3.000000,-12279.000000) [-12279.000000|0.000000] "Unit_None" ICAS1_Gateway
 SG_ TS_MomRad_verfuegb_maxReku_sek  : 116|12@1+ (3.000000,-12279.000000) [-12279.000000|0.000000] "Unit_None" ICAS1_Gateway
 SG_ TS_MomRad_Ist_sek  : 128|13@1+ (3.000000,-12279.000000) [-12279.000000|12279.000000] "Unit_None" ICAS1_Gateway
 SG_ TS_Allrad_Anteil_sek  : 141|9@1+ (0.200000,0.000000) [0.000000|100.000000] "Unit_PerCent" ICAS1_Gateway
 SG_ FDR_Allrad_Anteil_max_sek  : 150|9@1+ (0.200000,0.000000) [0.000000|100.000000] "Unit_PerCent" ICAS1_Gateway
 SG_ FDR_Allrad_Anteil_min_sek  : 159|9@1+ (0.200000,0.000000) [0.000000|100.000000] "Unit_PerCent" ICAS1_Gateway
 SG_ FDR_MomRad_Eingriff  : 168|13@1+ (3.000000,-12279.000000) [-12279.000000|12279.000000] "Unit_NewtoMeter" ICAS1_Gateway
 SG_ FDR_Status_Eingriff  : 181|1@1+ (1.000000,0.000000) [0.000000|1.000000] "" ICAS1_Gateway
 SG_ FDR_MomRad_Eingriff_sek  : 182|13@1+ (3.000000,-12279.000000) [-12279.000000|12279.000000] "Unit_NewtoMeter" ICAS1_Gateway
 SG_ FDR_Status_Eingriff_sek  : 195|1@1+ (1.000000,0.000000) [0.000000|1.000000] "" ICAS1_Gateway

BU_:  Airbag BAP_Tester ICAS1_Gateway ICAS1_KommunikationsServer LE1 LE2 Motor_BEV Schaltbetaetigung

BO_ 967 Motor_26: 8 Motor_BEV
 SG_ MO_Kuehlerluefter_MUX M : 0|1@1+ (1.000000,0.000000) [0.000000|1.000000] "siema ooo" ICAS1_Gateway
 SG_ MO_Kuehlerluefter_1 m0 : 1|7@1+ (1.000000,0.000000) [0.000000|100.000000] "Unit_PerCent" ICAS1_Gateway
 SG_ MO_Kuehlerluefter_2 m1 : 1|7@1+ (1.000000,0.000000) [0.000000|100.000000] "Unit_PerCent" ICAS1_Gateway
 SG_ MO_EFLEX_Lampe  : 8|2@1+ (1.000000,0.000000) [0.000000|3.000000] "" ICAS1_Gateway
 SG_ MO_KJS_nicht_bereit  : 10|1@1+ (1.000000,0.000000) [0.000000|1.000000] "" ICAS1_Gateway
 SG_ MO_ITM_Warnung_Pumpe  : 11|1@1+ (1.000000,0.000000) [0.000000|1.000000] "" ICAS1_Gateway
 SG_ WIV_Anzeige_aktiv  : 12|1@1+ (1.000000,0.000000) [0.000000|1.000000] "" ICAS1_Gateway
 SG_ WIV_Oelmin_Warn  : 13|1@1+ (1.000000,0.000000) [0.000000|1.000000] "" ICAS1_Gateway
 SG_ WIV_Sensorfehler  : 14|1@1+ (1.000000,0.000000) [0.000000|1.000000] "" ICAS1_Gateway
 SG_ WIV_Schieflage  : 15|1@1+ (1.000000,0.000000) [0.000000|1.000000] "" ICAS1_Gateway
 SG_ WIV_Oelstand  : 16|4@1+ (12.500000,0.000000) [0.000000|100.000000] "Unit_PerCent" ICAS1_Gateway
 SG_ MO_Zustand_HWP  : 20|2@1+ (1.000000,0.000000) [0.000000|3.000000] "" ICAS1_Gateway
 SG_ OLEV_Systemstoerung  : 22|1@1+ (1.000000,0.000000) [0.000000|1.000000] "" ICAS1_Gateway
 SG_ MO_Oelwarnung_max  : 23|1@1+ (1.000000,0.000000) [0.000000|1.000000] "" ICAS1_Gateway
 SG_ WIV_Oelsystem_aktiv  : 24|1@1+ (1.000000,0.000000) [0.000000|1.000000] "" ICAS1_Gateway
 SG_ WIV_nicht_betriebswarm  : 25|1@1+ (1.000000,0.000000) [0.000000|1.000000] "" ICAS1_Gateway
 SG_ WIV_Ueberfuell_Warn  : 26|1@1+ (1.000000,0.000000) [0.000000|1.000000] "" ICAS1_Gateway
 SG_ WIV_laufender_Motor  : 27|1@1+ (1.000000,0.000000) [0.000000|1.000000] "" ICAS1_Gateway
 SG_ MO_E_Warnungen  : 28|4@1+ (1.000000,0.000000) [0.000000|15.000000] "" ICAS1_Gateway
 SG_ MO_Text_Motorstart  : 32|4@1+ (1.000000,0.000000) [0.000000|15.000000] "" ICAS1_Gateway
 SG_ MO_E_Texte  : 36|4@1+ (1.000000,0.000000) [0.000000|15.000000] "" ICAS1_Gateway
 SG_ WIV_Oeldyn_avl  : 40|1@1+ (1.000000,0.000000) [0.000000|1.000000] "" ICAS1_Gateway
 SG_ MO_Text_Partikelfil_Reg  : 41|1@1+ (1.000000,0.000000) [0.000000|1.000000] "" ICAS1_Gateway
 SG_ OLEV_Oelstand_nicht_vorhanden  : 42|1@1+ (1.000000,0.000000) [0.000000|1.000000] "" ICAS1_Gateway
 SG_ WIV_Oelmenge  : 43|5@1+ (125.000000,0.000000) [0.000000|3875.000000] "Unit_MilliLiter" ICAS1_Gateway
 SG_ MO_Systemlampe  : 48|1@1+ (1.000000,0.000000) [0.000000|1.000000] "" ICAS1_Gateway
 SG_ MO_OBD2_Lampe  : 49|1@1+ (1.000000,0.000000) [0.000000|1.000000] "" ICAS1_Gateway
 SG_ MO_Heissleuchte  : 50|1@1+ (1.000000,0.000000) [0.000000|1.000000] "" ICAS1_Gateway
 SG_ MO_Partikel_Lampe  : 51|1@1+ (1.000000,0.000000) [0.000000|1.000000] "" ICAS1_Gateway
 SG_ MO_RedFahrleistung_Lampe  : 52|1@1+ (1.000000,0.000000) [0.000000|1.000000] "" ICAS1_Gateway ICAS1_KommunikationsServer
 SG_ WIV_Oelstand_nicht_vorhanden  : 53|1@1+ (1.000000,0.000000) [0.000000|1.000000] "" ICAS1_Gateway
 SG_ WIV_nachfuellanzeige_ein  : 54|1@1+ (1.000000,0.000000) [0.000000|1.000000] "" ICAS1_Gateway
 SG_ WIV_Ueberfuell_deaktiv  : 55|1@1+ (1.000000,0.000000) [0.000000|1.000000] "" ICAS1_Gateway
 SG_ WIV_Unterfuell_Warn  : 56|1@1+ (1.000000,0.000000) [0.000000|1.000000] "" ICAS1_Gateway
 SG_ MO_Tankdeckel_Lampe  : 57|1@1+ (1.000000,0.000000) [0.000000|1.000000] "" ICAS1_Gateway
 SG_ MO_Text_Tankdeckelwarn  : 58|1@1+ (1.000000,0.000000) [0.000000|1.000000] "" ICAS1_Gateway
 SG_ MO_Vorglueh_Lampe  : 59|1@1+ (1.000000,0.000000) [0.000000|1.000000] "" ICAS1_Gateway
 SG_ WIV_Oeldr_Warn_Motor  : 60|1@1+ (1.000000,0.000000) [0.000000|1.000000] "" ICAS1_Gateway
 SG_ MO_E_Mode  : 61|3@1+ (1.000000,0.000000) [0.000000|7.000000] "" ICAS1_Gateway

BO_ 706 Motor_41: 8 Motor_BEV
 SG_ MO_Anzeige_StSt_Text  : 12|4@1+ (1.000000,0.000000) [0.000000|15.000000] "" Vector__XXX
 SG_ MO_Anzeige_StSt_Symbol  : 16|3@1+ (1.000000,0.000000) [0.000000|7.000000] "" Vector__XXX
 SG_ MO_ADR_Status  : 19|2@1+ (1.000000,0.000000) [0.000000|3.000000] "" Vector__XXX
 SG_ MO_AGA_Sound_Texte  : 21|2@1+ (1.000000,0.000000) [0.000000|3.000000] "" Vector__XXX
 SG_ MO_Anzeige_FMAus_Text  : 23|1@1+ (1.000000,0.000000) [0.000000|1.000000] "" Vector__XXX
 SG_ PEA_Texte  : 25|3@1+ (1.000000,0.000000) [0.000000|7.000000] "" Vector__XXX
 SG_ TSK_Ueberstimmt_vMax_FahrerInfo  : 28|2@1+ (1.000000,0.000000) [0.000000|3.000000] "" Vector__XXX
 SG_ MO_Rekuperationsstufe  : 32|3@1+ (1.000000,0.000000) [0.000000|7.000000] "" ICAS1_KommunikationsServer
 SG_ TSK_Einheit_vMax_FahrerInfo  : 35|1@1+ (1.000000,0.000000) [0.000000|1.000000] "" ICAS1_KommunikationsServer
 SG_ TSK_Status_vMax_FahrerInfo  : 36|2@1+ (1.000000,0.000000) [0.000000|3.000000] "" ICAS1_KommunikationsServer
 SG_ MO_Anz_Kuehlerluefter  : 47|3@1+ (1.000000,0.000000) [0.000000|7.000000] "" Vector__XXX
 SG_ FDR_Warnung_ALR  : 50|2@1+ (1.000000,0.000000) [0.000000|3.000000] "" ICAS1_KommunikationsServer
 SG_ TSK_vMax_FahrerInfo  : 56|8@1+ (1.000000,15.000000) [16.000000|270.000000] "" ICAS1_KommunikationsServer

BO_ 267 Motor_51: 32 Motor_BEV
 SG_ Motor_51_CRC  : 0|8@1+ (1.000000,0.000000) [0.000000|255.000000] "" ICAS1_Gateway
 SG_ Motor_51_BZ  : 8|4@1+ (1.000000,0.000000) [0.000000|15.000000] "" ICAS1_Gateway
 SG_ MO_Fahrpedalrohwert_01  : 12|8@1+ (0.400000,0.000000) [0.000000|101.600000] "Unit_PerCent" Airbag ICAS1_Gateway
 SG_ MO_QBit_Fahrpedalwerte_01  : 20|1@1+ (1.000000,0.000000) [0.000000|1.000000] "" Airbag ICAS1_Gateway
 SG_ MO_Fahrpedalgradient  : 21|8@1+ (25.000000,0.000000) [0.000000|6350.000000] "Unit_PerCentPerSecon" ICAS1_Gateway
 SG_ MO_Sig_Fahrpedalgradient  : 29|1@1+ (1.000000,0.000000) [0.000000|1.000000] "" ICAS1_Gateway
 SG_ MO_rel_Saugrohrdruck  : 30|6@1+ (18.000000,0.000000) [0.000000|1116.000000] "Unit_MilliBar" ICAS1_Gateway
 SG_ MO_rel_Saugrohrdruck_gem_err  : 36|1@1+ (1.000000,0.000000) [0.000000|1.000000] "" ICAS1_Gateway
 SG_ MO_Moment_im_Leerlauf  : 37|1@1+ (1.000000,0.000000) [0.000000|1.000000] "" ICAS1_Gateway
 SG_ MO_Schubabschaltung  : 38|1@1+ (1.000000,0.000000) [0.000000|1.000000] "" ICAS1_Gateway
 SG_ MO_Solldrehz_Leerlauf  : 40|8@1+ (10.000000,0.000000) [0.000000|2540.000000] "Unit_MinutInver" ICAS1_Gateway
 SG_ MO_Entkopplung_Sollschlupf  : 48|7@1+ (20.000000,0.000000) [0.000000|2480.000000] "Unit_MinutInver" ICAS1_Gateway
 SG_ MO_temporaere_Fahrerabwesenheit  : 55|1@1+ (1.000000,0.000000) [0.000000|1.000000] "" ICAS1_Gateway
 SG_ TSK_a_Soll_gradientenbegrenzt  : 57|7@1+ (0.100000,-7.200000) [-7.200000|5.400000] "Unit_MeterPerSeconSquar" ICAS1_Gateway
 SG_ TSK_Radbremsmom  : 76|12@1+ (8.000000,0.000000) [0.000000|32760.000000] "Unit_NewtoMeter" ICAS1_Gateway
 SG_ TSK_Status  : 88|3@1+ (1.000000,0.000000) [0.000000|7.000000] "" ICAS1_Gateway
 SG_ TSK_v_Begrenzung_aktiv  : 91|1@1+ (1.000000,0.000000) [0.000000|1.000000] "" ICAS1_Gateway
 SG_ TSK_Standby_Anf_ESP  : 92|1@1+ (1.000000,0.000000) [0.000000|1.000000] "" ICAS1_Gateway
 SG_ TSK_Freig_WU  : 93|1@1+ (1.000000,0.000000) [0.000000|1.000000] "" ICAS1_Gateway
 SG_ TSK_Freig_Verzoeg_Anf  : 94|1@1+ (1.000000,0.000000) [0.000000|1.000000] "" ICAS1_Gateway
 SG_ TSK_Limiter_ausgewaehlt  : 95|1@1+ (1.000000,0.000000) [0.000000|1.000000] "" ICAS1_Gateway
 SG_ TSK_Wunsch_Uebersetz  : 96|10@1+ (0.024500,0.000000) [0.024500|25.063500] "" ICAS1_Gateway
 SG_ TSK_Hauptschalter_GRA_ACC  : 106|2@1+ (1.000000,0.000000) [0.000000|3.000000] "" ICAS1_Gateway ICAS1_KommunikationsServer
 SG_ TSK_SRBM_Anf_ASIL  : 108|3@1+ (1.000000,0.000000) [0.000000|7.000000] "" ICAS1_Gateway
 SG_ TSK_ax_Getriebe_02  : 112|9@1+ (0.024000,-2.016000) [-2.016000|10.224000] "Unit_MeterPerSeconSquar" ICAS1_Gateway
 SG_ TSK_Zwangszusch_ESP  : 121|1@1+ (1.000000,0.000000) [0.000000|1.000000] "" ICAS1_Gateway
 SG_ TSK_zul_Regelabw  : 122|6@1+ (0.024000,0.000000) [0.000000|1.512000] "Unit_MeterPerSeconSquar" ICAS1_Gateway
 SG_ MO_Status_MinDrzEingriff  : 235|3@1+ (1.000000,0.000000) [0.000000|7.000000] "" ICAS1_Gateway
 SG_ MO_Status_MaxDrzEingriff  : 238|3@1+ (1.000000,0.000000) [0.000000|7.000000] "" ICAS1_Gateway
 SG_ MO_Status_MinDrzEingriff_sek  : 241|3@1+ (1.000000,0.000000) [0.000000|7.000000] "" ICAS1_Gateway
 SG_ MO_Status_MaxDrzEingriff_sek  : 244|3@1+ (1.000000,0.000000) [0.000000|7.000000] "" ICAS1_Gateway
 SG_ GRA_KuFu_aktiv  : 247|1@1+ (1.000000,0.000000) [0.000000|1.000000] "" ICAS1_Gateway
 SG_ TSK_SRBM_max_Gradient  : 248|7@1+ (50.000000,0.000000) [0.000000|6250.000000] "Unit_NewtoMeterPerSecon" ICAS1_Gateway
 SG_ LIM_KuFu_aktiv  : 255|1@1+ (1.000000,0.000000) [0.000000|1.000000] "" ICAS1_Gateway

BO_ 330 Motor_52: 32 Motor_BEV
 SG_ MO_Hochschaltdrehz  : 21|12@1+ (3.000000,0.000000) [3.000000|12282.000000] "Unit_MinutInver" Vector__XXX
 SG_ MO_Anzeige_Verbr_Einheit  : 33|2@1+ (1.000000,0.000000) [0.000000|3.000000] "" Vector__XXX
 SG_ MO_Schaltblitz_Anz  : 35|7@1+ (1.000000,0.000000) [0.000000|100.000000] "Unit_PerCent" Vector__XXX
 SG_ MO_Anzeige_Drehmoment  : 42|11@1+ (1.000000,0.000000) [0.000000|2045.000000] "Unit_NewtoMeter" Vector__XXX
 SG_ MO_Anzeige_Leistung  : 53|11@1+ (0.600000,0.000000) [0.000000|1227.000000] "Unit_KiloWatt" Vector__XXX
 SG_ MO_rel_Ladedruck  : 64|8@1+ (0.400000,0.000000) [0.000000|100.000000] "Unit_PerCent" Vector__XXX
 SG_ MO_Istgang  : 72|4@1+ (1.000000,0.000000) [0.000000|15.000000] "" Vector__XXX
 SG_ MO_Sollgang  : 76|4@1+ (1.000000,0.000000) [0.000000|15.000000] "" Vector__XXX
 SG_ MO_Oeldruck  : 80|8@1+ (0.040000,0.000000) [0.000000|10.000000] "Unit_Bar" Vector__XXX
 SG_ MO_Anzeigedrehz  : 88|12@1+ (3.000000,0.000000) [0.000000|12282.000000] "Unit_MinutInver" Vector__XXX
 SG_ MO_Effizienzmodus  : 100|1@1+ (1.000000,0.000000) [0.000000|1.000000] "" Vector__XXX
 SG_ MO_Fehler_Oeldrucksensor  : 101|1@1+ (1.000000,0.000000) [0.000000|1.000000] "" Vector__XXX
 SG_ MO_Schaltempf_verfbar  : 102|1@1+ (1.000000,0.000000) [0.000000|1.000000] "" Vector__XXX
 SG_ MO_Ladedruck  : 103|9@1+ (0.010000,0.000000) [0.000000|5.100000] "Unit_Bar" Vector__XXX
 SG_ MO_KVS  : 112|15@1+ (1.000000,0.000000) [0.000000|32767.000000] "Unit_MicroLiter" Vector__XXX
 SG_ MO_KVS_Ueberlauf  : 127|1@1+ (1.000000,0.000000) [0.000000|1.000000] "" Vector__XXX
 SG_ MO_ePowermeter  : 128|8@1+ (0.400000,-0.400000) [0.000000|100.800000] "Unit_PerCent" Vector__XXX
 SG_ MO_ePerformance  : 136|8@1+ (0.400000,-0.400000) [0.000000|100.800000] "Unit_PerCent" ICAS1_KommunikationsServer
 SG_ MO_Zust_Antrieb  : 144|4@1+ (1.000000,0.000000) [0.000000|15.000000] "" Vector__XXX
 SG_ MO_Zust_Betriebsstrategie  : 148|3@1+ (1.000000,0.000000) [0.000000|7.000000] "" Vector__XXX
 SG_ Ladezustand_02  : 152|8@1+ (0.500000,0.000000) [0.000000|100.000000] "Unit_PerCent" ICAS1_Gateway ICAS1_KommunikationsServer
 SG_ MO_Powermeter_Elm_02  : 168|12@1+ (0.050000,-102.400000) [-100.000000|100.000000] "Unit_PerCent" Vector__XXX
 SG_ MO_Powermeter  : 180|12@1+ (1.000000,0.000000) [0.000000|4092.000000] "" ICAS1_KommunikationsServer

BO_ 512 Motor_53: 32 Motor_BEV
 SG_ TSK_Wunschgeschw  : 12|10@1+ (0.320000,0.000000) [0.000000|326.720000] "Unit_KiloMeterPerHour" ICAS1_Gateway ICAS1_KommunikationsServer
 SG_ TSK_praediktiver_Hinweis  : 22|3@1+ (1.000000,0.000000) [0.000000|7.000000] "" ICAS1_Gateway
 SG_ TSK_naechstes_Event  : 25|6@1+ (1.000000,0.000000) [0.000000|63.000000] "" ICAS1_Gateway
 SG_ TSK_Fahrzeugstatus_praed_Fkt  : 31|3@1+ (1.000000,0.000000) [0.000000|7.000000] "" ICAS1_Gateway
 SG_ TSK_Texte  : 40|5@1+ (1.000000,0.000000) [0.000000|31.000000] "" ICAS1_Gateway ICAS1_KommunikationsServer
 SG_ TSK_Akustik  : 45|3@1+ (1.000000,0.000000) [0.000000|7.000000] "" ICAS1_Gateway ICAS1_KommunikationsServer
 SG_ TSK_Texte_Primaeranz  : 48|5@1+ (1.000000,0.000000) [0.000000|31.000000] "" ICAS1_Gateway ICAS1_KommunikationsServer
 SG_ TSK_Limiter_Fahrerinfo  : 53|2@1+ (1.000000,0.000000) [0.000000|3.000000] "" ICAS1_Gateway ICAS1_KommunikationsServer
 SG_ TSK_Limiter_Anzeige  : 55|1@1+ (1.000000,0.000000) [0.000000|1.000000] "" ICAS1_Gateway ICAS1_KommunikationsServer
 SG_ TSK_Fahrzeugstatus_GRA  : 56|1@1+ (1.000000,0.000000) [0.000000|1.000000] "" ICAS1_Gateway ICAS1_KommunikationsServer
 SG_ TSK_Fahrzeugstatus_Limiter  : 57|1@1+ (1.000000,0.000000) [0.000000|1.000000] "" ICAS1_Gateway ICAS1_KommunikationsServer
 SG_ MO_Motorlaufwarnung  : 58|1@1+ (1.000000,0.000000) [0.000000|1.000000] "" ICAS1_Gateway
 SG_ TSK_naechstes_Event_Einheit  : 60|1@1+ (1.000000,0.000000) [0.000000|1.000000] "" ICAS1_Gateway
 SG_ TSK_Status_Anzeige  : 61|3@1+ (1.000000,0.000000) [0.000000|7.000000] "" ICAS1_Gateway ICAS1_KommunikationsServer
 SG_ MO_Sperrung_FahrPr_BZS  : 64|8@1+ (1.000000,0.000000) [0.000000|255.000000] "" ICAS1_Gateway
 SG_ MO_Rampenzeit_Generator_Anf  : 72|4@1+ (1.000000,0.000000) [0.000000|15.000000] "" ICAS1_Gateway
 SG_ MO_Prio_MAX_Wunschdrehzahl  : 76|1@1+ (1.000000,0.000000) [0.000000|1.000000] "" ICAS1_Gateway
 SG_ MO_Prio_MIN_Wunschdrehzahl  : 77|1@1+ (1.000000,0.000000) [0.000000|1.000000] "" ICAS1_Gateway
 SG_ MO_Luftpfad_aktiv  : 78|1@1+ (1.000000,0.000000) [0.000000|1.000000] "" ICAS1_Gateway
 SG_ MO_v_Begrenz_Aktivierbar  : 79|1@1+ (1.000000,0.000000) [0.000000|1.000000] "" ICAS1_Gateway
 SG_ MO_Drehzahlbeeinflussung  : 80|8@1+ (0.390000,0.000000) [0.000000|99.450000] "Unit_PerCent" ICAS1_Gateway
 SG_ MO_MIN_Wunschdrehzahl  : 88|8@1+ (25.000000,0.000000) [0.000000|6350.000000] "Unit_MinutInver" ICAS1_Gateway
 SG_ MO_MAX_Wunschdrehzahl  : 96|9@1+ (25.000000,0.000000) [0.000000|12750.000000] "Unit_MinutInver" ICAS1_Gateway
 SG_ MO_Charisma_FahrPr  : 105|4@1+ (1.000000,0.000000) [0.000000|15.000000] "" ICAS1_Gateway
 SG_ MO_Charisma_Status  : 109|2@1+ (1.000000,0.000000) [0.000000|3.000000] "" ICAS1_Gateway
 SG_ MO_StSt_Charisma_FahrPr  : 111|4@1+ (1.000000,0.000000) [0.000000|15.000000] "" ICAS1_Gateway
 SG_ MO_StSt_Charisma_Status  : 115|2@1+ (1.000000,0.000000) [0.000000|3.000000] "" ICAS1_Gateway
 SG_ MO_BZS_Charisma_FahrPr  : 117|4@1+ (1.000000,0.000000) [0.000000|15.000000] "" ICAS1_Gateway
 SG_ MO_BZS_Charisma_Status  : 121|2@1+ (1.000000,0.000000) [0.000000|3.000000] "" ICAS1_Gateway
 SG_ MO_NGS_Position  : 123|1@1+ (1.000000,0.000000) [0.000000|1.000000] "" ICAS1_Gateway
 SG_ MO_NGS_Status  : 124|2@1+ (1.000000,0.000000) [0.000000|3.000000] "" ICAS1_Gateway
 SG_ MO_v_Begrenzung_Niveau  : 126|2@1+ (1.000000,0.000000) [0.000000|3.000000] "" ICAS1_Gateway
 SG_ MO_Anzeige_Rekuperation  : 128|8@1+ (0.500000,-0.500000) [0.000000|100.000000] "Unit_PerCent" ICAS1_Gateway
 SG_ PEA_Fortschrittsanzeige  : 136|7@1+ (1.000000,0.000000) [0.000000|100.000000] "Unit_PerCent" ICAS1_Gateway
 SG_ MO_Anzeige_Fahrbereitschaft  : 143|1@1+ (1.000000,0.000000) [0.000000|1.000000] "" ICAS1_Gateway ICAS1_KommunikationsServer
 SG_ MO_Boost_verfuegbar  : 144|8@1+ (0.400000,-0.400000) [0.000000|100.400000] "Unit_PerCent" ICAS1_Gateway
 SG_ MO_Overboost  : 152|1@1+ (1.000000,0.000000) [0.000000|1.000000] "" ICAS1_Gateway
 SG_ MO_Boost_aktiv  : 153|1@1+ (1.000000,0.000000) [0.000000|1.000000] "" ICAS1_Gateway
 SG_ MO_Anzeige_Betriebsmodus  : 154|4@1+ (1.000000,0.000000) [0.000000|15.000000] "" ICAS1_Gateway
 SG_ PEA_Hinweis  : 158|2@1+ (1.000000,0.000000) [0.000000|3.000000] "" ICAS1_Gateway
 SG_ PEA_Ereignisanzeige  : 160|5@1+ (1.000000,0.000000) [0.000000|31.000000] "" ICAS1_Gateway
 SG_ PEA_Ereignisanzeige_temporaer  : 165|1@1+ (1.000000,0.000000) [0.000000|1.000000] "" ICAS1_Gateway
 SG_ PEA_Abschalttexte  : 166|2@1+ (1.000000,0.000000) [0.000000|3.000000] "" ICAS1_Gateway
 SG_ PEA_Zielgeschw_Einheit  : 168|1@1+ (1.000000,0.000000) [0.000000|1.000000] "" ICAS1_Gateway
 SG_ PEA_Zielgeschw  : 169|5@1+ (1.000000,0.000000) [0.000000|31.000000] "" ICAS1_Gateway
 SG_ MO_Antriebsstrang_Warnung_HS  : 174|2@1+ (1.000000,0.000000) [0.000000|3.000000] "" ICAS1_Gateway
 SG_ MO_Anzeige_Verbrauch_oE  : 176|16@1+ (0.005000,0.000000) [0.000000|327.675000] "Unit_None" ICAS1_Gateway

BO_ 332 Motor_54: 32 Motor_BEV
 SG_ MO_Anforderung_HMS  : 12|3@1+ (1.000000,0.000000) [0.000000|7.000000] "" ICAS1_Gateway
 SG_ FoD_DTC_TSK_GRA  : 15|1@1+ (1.000000,0.000000) [0.000000|1.000000] "" ICAS1_Gateway
 SG_ TSK_vMax_aktuell  : 16|8@1+ (1.000000,0.000000) [0.000000|253.000000] "Unit_KiloMeterPerHour" ICAS1_Gateway
 SG_ TSK_Status_EA  : 32|3@1+ (1.000000,0.000000) [0.000000|7.000000] "" ICAS1_Gateway
 SG_ FoD_DTC_TSK_ACC  : 35|1@1+ (1.000000,0.000000) [0.000000|1.000000] "" ICAS1_Gateway
 SG_ TSK_ACC_FoD_Status  : 36|2@1+ (1.000000,0.000000) [0.000000|3.000000] "" ICAS1_Gateway
 SG_ TSK_GRA_FoD_Status  : 38|2@1+ (1.000000,0.000000) [0.000000|3.000000] "" ICAS1_Gateway
 SG_ TSK_vMax_Fahrerassistenz  : 40|9@1+ (1.000000,0.000000) [0.000000|510.000000] "" ICAS1_Gateway
 SG_ TSK_Einheit_vMax_Fahrerassistenz  : 49|1@1+ (1.000000,0.000000) [0.000000|1.000000] "" ICAS1_Gateway
 SG_ TSK_Status_PLA  : 50|3@1+ (1.000000,0.000000) [0.000000|7.000000] "" ICAS1_Gateway
 SG_ TSK_aktives_System  : 53|3@1+ (1.000000,0.000000) [0.000000|7.000000] "" ICAS1_Gateway
 SG_ TSK_erhoehter_Fahrwiderstand  : 56|1@1+ (1.000000,0.000000) [0.000000|1.000000] "" ICAS1_Gateway
 SG_ TSK_Anf_Antriebsmoment  : 57|1@1+ (1.000000,0.000000) [0.000000|1.000000] "" ICAS1_Gateway
 SG_ TSK_Status_ARA  : 58|3@1+ (1.000000,0.000000) [0.000000|7.000000] "" ICAS1_Gateway
 SG_ TSK_Status_IPA  : 61|3@1+ (1.000000,0.000000) [0.000000|7.000000] "" ICAS1_Gateway
 SG_ MO_Fahrbereitschaft  : 76|2@1+ (1.000000,0.000000) [0.000000|3.000000] "" ICAS1_Gateway LE1 LE2
 SG_ MO_Freilauf_Info  : 78|2@1+ (1.000000,0.000000) [0.000000|3.000000] "" ICAS1_Gateway
 SG_ MO_Krit_Heckobjekt  : 81|3@1+ (1.000000,0.000000) [0.000000|7.000000] "" ICAS1_Gateway
 SG_ MO_NGS_Gangpos  : 84|3@1+ (1.000000,0.000000) [0.000000|7.000000] "" ICAS1_Gateway
 SG_ MO_Freilauf_Status  : 87|3@1+ (1.000000,0.000000) [0.000000|7.000000] "" ICAS1_Gateway
 SG_ MO_EBoost_verf_praed  : 90|2@1+ (1.000000,0.000000) [0.000000|3.000000] "" ICAS1_Gateway
 SG_ MO_Heckspoiler_Anf  : 92|1@1+ (1.000000,0.000000) [0.000000|1.000000] "" ICAS1_Gateway
 SG_ MO_eLaunch_verf  : 93|2@1+ (1.000000,0.000000) [0.000000|3.000000] "" ICAS1_Gateway
 SG_ MO_Positionierung_aktiv  : 95|1@1+ (1.000000,0.000000) [0.000000|1.000000] "" ICAS1_Gateway
 SG_ MO_Freilauf_Typ  : 98|2@1+ (1.000000,0.000000) [0.000000|3.000000] "" ICAS1_Gateway
 SG_ MO_Startwunsch  : 100|1@1+ (1.000000,0.000000) [0.000000|1.000000] "" ICAS1_Gateway
 SG_ OBD_Calc_Load_Val  : 128|8@1+ (0.392157,0.000000) [0.000000|100.000000] "Unit_PerCent" ICAS1_Gateway LE1 LE2
 SG_ OBD_Eng_Cool_Temp  : 136|8@1+ (1.000000,-40.000000) [-40.000000|215.000000] "Unit_DegreCelsi" ICAS1_Gateway LE1 LE2
 SG_ OBD_Abs_Throttle_Pos  : 144|8@1+ (0.392157,0.000000) [0.000000|100.000000] "Unit_PerCent" ICAS1_Gateway LE1 LE2
 SG_ OBD_Abs_Load_Val  : 152|16@1+ (0.392157,0.000000) [0.000000|25700.000000] "Unit_PerCent" ICAS1_Gateway LE1 LE2
 SG_ OBD_Abs_Pedal_Pos  : 168|8@1+ (0.392157,0.000000) [0.000000|100.000000] "Unit_PerCent" ICAS1_Gateway LE1 LE2
 SG_ MO_Servicemodus  : 176|4@1+ (1.000000,0.000000) [0.000000|15.000000] "" ICAS1_Gateway LE1 LE2
 SG_ OBD_ClearMem_Inhibit  : 183|1@1+ (1.000000,0.000000) [0.000000|1.000000] "" ICAS1_Gateway LE1 LE2
 SG_ OBD_Sperrung_Kaltstart_Denom  : 184|1@1+ (1.000000,0.000000) [0.000000|1.000000] "" ICAS1_Gateway LE1 LE2
 SG_ MO_QBit_Aussen_Temp  : 185|1@1+ (1.000000,0.000000) [0.000000|1.000000] "" ICAS1_Gateway
 SG_ OBD_Sperrung_IUMPR  : 186|1@1+ (1.000000,0.000000) [0.000000|1.000000] "" ICAS1_Gateway LE1 LE2
 SG_ OBD_Kaltstart_Denominator  : 187|1@1+ (1.000000,0.000000) [0.000000|1.000000] "" ICAS1_Gateway LE1 LE2
 SG_ OBD_Minimum_Trip  : 188|1@1+ (1.000000,0.000000) [0.000000|1.000000] "" ICAS1_Gateway LE1 LE2
 SG_ OBD_Driving_Cycle  : 189|1@1+ (1.000000,0.000000) [0.000000|1.000000] "" ICAS1_Gateway LE1 LE2
 SG_ OBD_Warm_Up_Cycle  : 190|1@1+ (1.000000,0.000000) [0.000000|1.000000] "" ICAS1_Gateway LE1 LE2
 SG_ OBD_Normed_Trip  : 191|1@1+ (1.000000,0.000000) [0.000000|1.000000] "" ICAS1_Gateway LE1 LE2
 SG_ OBD_Aussen_Temp_gef  : 248|8@1+ (1.000000,-40.000000) [-40.000000|213.000000] "Unit_DegreCelsi" ICAS1_Gateway

BO_ 246 Motor_55: 32 Motor_BEV
 SG_ Motor_55_CRC  : 0|8@1+ (1.000000,0.000000) [0.000000|255.000000] "" ICAS1_Gateway
 SG_ Motor_55_BZ  : 8|4@1+ (1.000000,0.000000) [0.000000|15.000000] "" ICAS1_Gateway
 SG_ TS_Faktor_Radmomente  : 12|2@1+ (1.000000,0.000000) [0.000000|3.000000] "" ICAS1_Gateway
 SG_ TS_Status_MomRad_Ist  : 14|2@1+ (1.000000,0.000000) [0.000000|3.000000] "" ICAS1_Gateway
 SG_ TS_MomRad_verfuegb_maxReku_Summe  : 16|12@1+ (3.000000,-12279.000000) [-12279.000000|0.000000] "" ICAS1_Gateway
 SG_ TS_MomRad_Ist  : 28|13@1+ (3.000000,-12279.000000) [-12279.000000|12279.000000] "Unit_None" ICAS1_Gateway
 SG_ TS_MomRad_Soll_Summe  : 41|13@1+ (3.000000,-12279.000000) [-12279.000000|12279.000000] "Unit_None" ICAS1_Gateway
 SG_ TS_MomRad_Wunsch  : 54|13@1+ (3.000000,-12279.000000) [-12279.000000|12279.000000] "Unit_None" ICAS1_Gateway
 SG_ TS_MomRad_Wunsch_sek  : 67|13@1+ (3.000000,-12279.000000) [-12279.000000|12279.000000] "Unit_None" ICAS1_Gateway
 SG_ TS_MomRad_verfuegb_max  : 80|12@1+ (3.000000,0.000000) [0.000000|12279.000000] "Unit_None" ICAS1_Gateway
 SG_ TS_MomRad_verfuegb_max_sek  : 92|12@1+ (3.000000,0.000000) [0.000000|12279.000000] "Unit_None" ICAS1_Gateway
 SG_ TS_MomRad_verfuegb_maxReku  : 104|12@1+ (3.000000,-12279.000000) [-12279.000000|0.000000] "Unit_None" ICAS1_Gateway
 SG_ TS_MomRad_verfuegb_maxReku_sek  : 116|12@1+ (3.000000,-12279.000000) [-12279.000000|0.000000] "Unit_None" ICAS1_Gateway
 SG_ TS_MomRad_Ist_sek  : 128|13@1+ (3.000000,-12279.000000) [-12279.000000|12279.000000] "Unit_None" ICAS1_Gateway
 SG_ TS_Allrad_Anteil_sek  : 141|9@1+ (0.200000,0.000000) [0.000000|100.000000] "Unit_PerCent" ICAS1_Gateway
 SG_ FDR_Allrad_Anteil_max_sek  : 150|9@1+ (0.200000,0.000000) [0.000000|100.000000] "Unit_PerCent" ICAS1_Gateway
 SG_ FDR_Allrad_Anteil_min_sek  : 159|9@1+ (0.200000,0.000000) [0.000000|100.000000] "Unit_PerCent" ICAS1_Gateway
 SG_ FDR_MomRad_Eingriff  : 168|13@1+ (3.000000,-12279.000000) [-12279.000000|12279.000000] "Unit_NewtoMeter" ICAS1_Gateway
 SG_ FDR_Status_Eingriff  : 181|1@1+ (1.000000,0.000000) [0.000000|1.000000] "" ICAS1_Gateway
 SG_ FDR_MomRad_Eingriff_sek  : 182|13@1+ (3.000000,-12279.000000) [-12279.000000|12279.000000] "Unit_NewtoMeter" ICAS1_Gateway
 SG_ FDR_Status_Eingriff_sek  : 195|1@1+ (1.000000,0.000000) [0.000000|1.000000] "" ICAS1_Gateway

BU_:  Airbag BAP_Tester ICAS1_Gateway ICAS1_KommunikationsServer LE1 LE2 Motor_BEV Schaltbetaetigung

BO_ 967 Motor_26: 8 Motor_BEV
 SG_ MO_Kuehlerluefter_MUX M : 0|1@1+ (1.000000,0.000000) [0.000000|1.000000] "siema ooo" ICAS1_Gateway
 SG_ MO_Kuehlerluefter_1 m0 : 1|7@1+ (1.000000,0.000000) [0.000000|100.000000] "Unit_PerCent" ICAS1_Gateway
 SG_ MO_Kuehlerluefter_2 m1 : 1|7@1+ (1.000000,0.000000) [0.000000|100.000000] "Unit_PerCent" ICAS1_Gateway
 SG_ MO_EFLEX_Lampe  : 8|2@1+ (1.000000,0.000000) [0.000000|3.000000] "" ICAS1_Gateway
 SG_ MO_KJS_nicht_bereit  : 10|1@1+ (1.000000,0.000000) [0.000000|1.000000] "" ICAS1_Gateway
 SG_ MO_ITM_Warnung_Pumpe  : 11|1@1+ (1.000000,0.000000) [0.000000|1.000000] "" ICAS1_Gateway
 SG_ WIV_Anzeige_aktiv  : 12|1@1+ (1.000000,0.000000) [0.000000|1.000000] "" ICAS1_Gateway
 SG_ WIV_Oelmin_Warn  : 13|1@1+ (1.000000,0.000000) [0.000000|1.000000] "" ICAS1_Gateway
 SG_ WIV_Sensorfehler  : 14|1@1+ (1.000000,0.000000) [0.000000|1.000000] "" ICAS1_Gateway
 SG_ WIV_Schieflage  : 15|1@1+ (1.000000,0.000000) [0.000000|1.000000] "" ICAS1_Gateway
 SG_ WIV_Oelstand  : 16|4@1+ (12.500000,0.000000) [0.000000|100.000000] "Unit_PerCent" ICAS1_Gateway
 SG_ MO_Zustand_HWP  : 20|2@1+ (1.000000,0.000000) [0.000000|3.000000] "" ICAS1_Gateway
 SG_ OLEV_Systemstoerung  : 22|1@1+ (1.000000,0.000000) [0.000000|1.000000] "" ICAS1_Gateway
 SG_ MO_Oelwarnung_max  : 23|1@1+ (1.000000,0.000000) [0.000000|1.000000] "" ICAS1_Gateway
 SG_ WIV_Oelsystem_aktiv  : 24|1@1+ (1.000000,0.000000) [0.000000|1.000000] "" ICAS1_Gateway
 SG_ WIV_nicht_betriebswarm  : 25|1@1+ (1.000000,0.000000) [0.000000|1.000000] "" ICAS1_Gateway
 SG_ WIV_Ueberfuell_Warn  : 26|1@1+ (1.000000,0.000000) [0.000000|1.000000] "" ICAS1_Gateway
 SG_ WIV_laufender_Motor  : 27|1@1+ (1.000000,0.000000) [0.000000|1.000000] "" ICAS1_Gateway
 SG_ MO_E_Warnungen  : 28|4@1+ (1.000000,0.000000) [0.000000|15.000000] "" ICAS1_Gateway
 SG_ MO_Text_Motorstart  : 32|4@1+ (1.000000,0.000000) [0.000000|15.000000] "" ICAS1_Gateway
 SG_ MO_E_Texte  : 36|4@1+ (1.000000,0.000000) [0.000000|15.000000] "" ICAS1_Gateway
 SG_ WIV_Oeldyn_avl  : 40|1@1+ (1.000000,0.000000) [0.000000|1.000000] "" ICAS1_Gateway
 SG_ MO_Text_Partikelfil_Reg  : 41|1@1+ (1.000000,0.000000) [0.000000|1.000000] "" ICAS1_Gateway
 SG_ OLEV_Oelstand_nicht_vorhanden  : 42|1@1+ (1.000000,0.000000) [0.000000|1.000000] "" ICAS1_Gateway
 SG_ WIV_Oelmenge  : 43|5@1+ (125.000000,0.000000) [0.000000|3875.000000] "Unit_MilliLiter" ICAS1_Gateway
 SG_ MO_Systemlampe  : 48|1@1+ (1.000000,0.000000) [0.000000|1.000000] "" ICAS1_Gateway
 SG_ MO_OBD2_Lampe  : 49|1@1+ (1.000000,0.000000) [0.000000|1.000000] "" ICAS1_Gateway
 SG_ MO_Heissleuchte  : 50|1@1+ (1.000000,0.000000) [0.000000|1.000000] "" ICAS1_Gateway
 SG_ MO_Partikel_Lampe  : 51|1@1+ (1.000000,0.000000) [0.000000|1.000000] "" ICAS1_Gateway
 SG_ MO_RedFahrleistung_Lampe  : 52|1@1+ (1.000000,0.000000) [0.000000|1.000000] "" ICAS1_Gateway ICAS1_KommunikationsServer
 SG_ WIV_Oelstand_nicht_vorhanden  : 53|1@1+ (1.000000,0.000000) [0.000000|1.000000] "" ICAS1_Gateway
 SG_ WIV_nachfuellanzeige_ein  : 54|1@1+ (1.000000,0.000000) [0.000000|1.000000] "" ICAS1_Gateway
 SG_ WIV_Ueberfuell_deaktiv  : 55|1@1+ (1.000000,0.000000) [0.000000|1.000000] "" ICAS1_Gateway
 SG_ WIV_Unterfuell_Warn  : 56|1@1+ (1.000000,0.000000) [0.000000|1.000000] "" ICAS1_Gateway
 SG_ MO_Tankdeckel_Lampe  : 57|1@1+ (1.000000,0.000000) [0.000000|1.000000] "" ICAS1_Gateway
 SG_ MO_Text_Tankdeckelwarn  : 58|1@1+ (1.000000,0.000000) [0.000000|1.000000] "" ICAS1_Gateway
 SG_ MO_Vorglueh_Lampe  : 59|1@1+ (1.000000,0.000000) [0.000000|1.000000] "" ICAS1_Gateway
 SG_ WIV_Oeldr_Warn_Motor  : 60|1@1+ (1.000000,0.000000) [0.000000|1.000000] "" ICAS1_Gateway
 SG_ MO_E_Mode  : 61|3@1+ (1.000000,0.000000) [0.000000|7.000000] "" ICAS1_Gateway

BO_ 706 Motor_41: 8 Motor_BEV
 SG_ MO_Anzeige_StSt_Text  : 12|4@1+ (1.000000,0.000000) [0.000000|15.000000] "" Vector__XXX
 SG_ MO_Anzeige_StSt_Symbol  : 16|3@1+ (1.000000,0.000000) [0.000000|7.000000] "" Vector__XXX
 SG_ MO_ADR_Status  : 19|2@1+ (1.000000,0.000000) [0.000000|3.000000] "" Vector__XXX
 SG_ MO_AGA_Sound_Texte  : 21|2@1+ (1.000000,0.000000) [0.000000|3.000000] "" Vector__XXX
 SG_ MO_Anzeige_FMAus_Text  : 23|1@1+ (1.000000,0.000000) [0.000000|1.000000] "" Vector__XXX
 SG_ PEA_Texte  : 25|3@1+ (1.000000,0.000000) [0.000000|7.000000] "" Vector__XXX
 SG_ TSK_Ueberstimmt_vMax_FahrerInfo  : 28|2@1+ (1.000000,0.000000) [0.000000|3.000000] "" Vector__XXX
 SG_ MO_Rekuperationsstufe  : 32|3@1+ (1.000000,0.000000) [0.000000|7.000000] "" ICAS1_KommunikationsServer
 SG_ TSK_Einheit_vMax_FahrerInfo  : 35|1@1+ (1.000000,0.000000) [0.000000|1.000000] "" ICAS1_KommunikationsServer
 SG_ TSK_Status_vMax_FahrerInfo  : 36|2@1+ (1.000000,0.000000) [0.000000|3.000000] "" ICAS1_KommunikationsServer
 SG_ MO_Anz_Kuehlerluefter  : 47|3@1+ (1.000000,0.000000) [0.000000|7.000000] "" Vector__XXX
 SG_ FDR_Warnung_ALR  : 50|2@1+ (1.000000,0.000000) [0.000000|3.000000] "" ICAS1_KommunikationsServer
 SG_ TSK_vMax_FahrerInfo  : 56|8@1+ (1.000000,15.000000) [16.000000|270.000000] "" ICAS1_KommunikationsServer

BO_ 267 Motor_51: 32 Motor_BEV
 SG_ Motor_51_CRC  : 0|8@1+ (1.000000,0.000000) [0.000000|255.000000] "" ICAS1_Gateway
 SG_ Motor_51_BZ  : 8|4@1+ (1.000000,0.000000) [0.000000|15.000000] "" ICAS1_Gateway
 SG_ MO_Fahrpedalrohwert_01  : 12|8@1+ (0.400000,0.000000) [0.000000|101.600000] "Unit_PerCent" Airbag ICAS1_Gateway
 SG_ MO_QBit_Fahrpedalwerte_01  : 20|1@1+ (1.000000,0.000000) [0.000000|1.000000] "" Airbag ICAS1_Gateway
 SG_ MO_Fahrpedalgradient  : 21|8@1+ (25.000000,0.000000) [0.000000|6350.000000] "Unit_PerCentPerSecon" ICAS1_Gateway
 SG_ MO_Sig_Fahrpedalgradient  : 29|1@1+ (1.000000,0.000000) [0.000000|1.000000] "" ICAS1_Gateway
 SG_ MO_rel_Saugrohrdruck  : 30|6@1+ (18.000000,0.000000) [0.000000|1116.000000] "Unit_MilliBar" ICAS1_Gateway
 SG_ MO_rel_Saugrohrdruck_gem_err  : 36|1@1+ (1.000000,0.000000) [0.000000|1.000000] "" ICAS1_Gateway
 SG_ MO_Moment_im_Leerlauf  : 37|1@1+ (1.000000,0.000000) [0.000000|1.000000] "" ICAS1_Gateway
 SG_ MO_Schubabschaltung  : 38|1@1+ (1.000000,0.000000) [0.000000|1.000000] "" ICAS1_Gateway
 SG_ MO_Solldrehz_Leerlauf  : 40|8@1+ (10.000000,0.000000) [0.000000|2540.000000] "Unit_MinutInver" ICAS1_Gateway
 SG_ MO_Entkopplung_Sollschlupf  : 48|7@1+ (20.000000,0.000000) [0.000000|2480.000000] "Unit_MinutInver" ICAS1_Gateway
 SG_ MO_temporaere_Fahrerabwesenheit  : 55|1@1+ (1.000000,0.000000) [0.000000|1.000000] "" ICAS1_Gateway
 SG_ TSK_a_Soll_gradientenbegrenzt  : 57|7@1+ (0.100000,-7.200000) [-7.200000|5.400000] "Unit_MeterPerSeconSquar" ICAS1_Gateway
 SG_ TSK_Radbremsmom  : 76|12@1+ (8.000000,0.000000) [0.000000|32760.000000] "Unit_NewtoMeter" ICAS1_Gateway
 SG_ TSK_Status  : 88|3@1+ (1.000000,0.000000) [0.000000|7.000000] "" ICAS1_Gateway
 SG_ TSK_v_Begrenzung_aktiv  : 91|1@1+ (1.000000,0.000000) [0.000000|1.000000] "" ICAS1_Gateway
 SG_ TSK_Standby_Anf_ESP  : 92|1@1+ (1.000000,0.000000) [0.000000|1.000000] "" ICAS1_Gateway
 SG_ TSK_Freig_WU  : 93|1@1+ (1.000000,0.000000) [0.000000|1.000000] "" ICAS1_Gateway
 SG_ TSK_Freig_Verzoeg_Anf  : 94|1@1+ (1.000000,0.000000) [0.000000|1.000000] "" ICAS1_Gateway
 SG_ TSK_Limiter_ausgewaehlt  : 95|1@1+ (1.000000,0.000000) [0.000000|1.000000] "" ICAS1_Gateway
 SG_ TSK_Wunsch_Uebersetz  : 96|10@1+ (0.024500,0.000000) [0.024500|25.063500] "" ICAS1_Gateway
 SG_ TSK_Hauptschalter_GRA_ACC  : 106|2@1+ (1.000000,0.000000) [0.000000|3.000000] "" ICAS1_Gateway ICAS1_KommunikationsServer
 SG_ TSK_SRBM_Anf_ASIL  : 108|3@1+ (1.000000,0.000000) [0.000000|7.000000] "" ICAS1_Gateway
 SG_ TSK_ax_Getriebe_02  : 112|9@1+ (0.024000,-2.016000) [-2.016000|10.224000] "Unit_MeterPerSeconSquar" ICAS1_Gateway
 SG_ TSK_Zwangszusch_ESP  : 121|1@1+ (1.000000,0.000000) [0.000000|1.000000] "" ICAS1_Gateway
 SG_ TSK_zul_Regelabw  : 122|6@1+ (0.024000,0.000000) [0.000000|1.512000] "Unit_MeterPerSeconSquar" ICAS1_Gateway
 SG_ MO_Status_MinDrzEingriff  : 235|3@1+ (1.000000,0.000000) [0.000000|7.000000] "" ICAS1_Gateway
 SG_ MO_Status_MaxDrzEingriff  : 238|3@1+ (1.000000,0.000000) [0.000000|7.000000] "" ICAS1_Gateway
 SG_ MO_Status_MinDrzEingriff_sek  : 241|3@1+ (1.000000,0.000000) [0.000000|7.000000] "" ICAS1_Gateway
 SG_ MO_Status_MaxDrzEingriff_sek  : 244|3@1+ (1.000000,0.000000) [0.000000|7.000000] "" ICAS1_Gateway
 SG_ GRA_KuFu_aktiv  : 247|1@1+ (1.000000,0.000000) [0.000000|1.000000] "" ICAS1_Gateway
 SG_ TSK_SRBM_max_Gradient  : 248|7@1+ (50.000000,0.000000) [0.000000|6250.000000] "Unit_NewtoMeterPerSecon" ICAS1_Gateway
 SG_ LIM_KuFu_aktiv  : 255|1@1+ (1.000000,0.000000) [0.000000|1.000000] "" ICAS1_Gateway

BO_ 330 Motor_52: 32 Motor_BEV
 SG_ MO_Hochschaltdrehz  : 21|12@1+ (3.000000,0.000000) [3.000000|12282.000000] "Unit_MinutInver" Vector__XXX
 SG_ MO_Anzeige_Verbr_Einheit  : 33|2@1+ (1.000000,0.000000) [0.000000|3.000000] "" Vector__XXX
 SG_ MO_Schaltblitz_Anz  : 35|7@1+ (1.000000,0.000000) [0.000000|100.000000] "Unit_PerCent" Vector__XXX
 SG_ MO_Anzeige_Drehmoment  : 42|11@1+ (1.000000,0.000000) [0.000000|2045.000000] "Unit_NewtoMeter" Vector__XXX
 SG_ MO_Anzeige_Leistung  : 53|11@1+ (0.600000,0.000000) [0.000000|1227.000000] "Unit_KiloWatt" Vector__XXX
 SG_ MO_rel_Ladedruck  : 64|8@1+ (0.400000,0.000000) [0.000000|100.000000] "Unit_PerCent" Vector__XXX
 SG_ MO_Istgang  : 72|4@1+ (1.000000,0.000000) [0.000000|15.000000] "" Vector__XXX
 SG_ MO_Sollgang  : 76|4@1+ (1.000000,0.000000) [0.000000|15.000000] "" Vector__XXX
 SG_ MO_Oeldruck  : 80|8@1+ (0.040000,0.000000) [0.000000|10.000000] "Unit_Bar" Vector__XXX
 SG_ MO_Anzeigedrehz  : 88|12@1+ (3.000000,0.000000) [0.000000|12282.000000] "Unit_MinutInver" Vector__XXX
 SG_ MO_Effizienzmodus  : 100|1@1+ (1.000000,0.000000) [0.000000|1.000000] "" Vector__XXX
 SG_ MO_Fehler_Oeldrucksensor  : 101|1@1+ (1.000000,0.000000) [0.000000|1.000000] "" Vector__XXX
 SG_ MO_Schaltempf_verfbar  : 102|1@1+ (1.000000,0.000000) [0.000000|1.000000] "" Vector__XXX
 SG_ MO_Ladedruck  : 103|9@1+ (0.010000,0.000000) [0.000000|5.100000] "Unit_Bar" Vector__XXX
 SG_ MO_KVS  : 112|15@1+ (1.000000,0.000000) [0.000000|32767.000000] "Unit_MicroLiter" Vector__XXX
 SG_ MO_KVS_Ueberlauf  : 127|1@1+ (1.000000,0.000000) [0.000000|1.000000] "" Vector__XXX
 SG_ MO_ePowermeter  : 128|8@1+ (0.400000,-0.400000) [0.000000|100.800000] "Unit_PerCent" Vector__XXX
 SG_ MO_ePerformance  : 136|8@1+ (0.400000,-0.400000) [0.000000|100.800000] "Unit_PerCent" ICAS1_KommunikationsServer
 SG_ MO_Zust_Antrieb  : 144|4@1+ (1.000000,0.000000) [0.000000|15.000000] "" Vector__XXX
 SG_ MO_Zust_Betriebsstrategie  : 148|3@1+ (1.000000,0.000000) [0.000000|7.000000] "" Vector__XXX
 SG_ Ladezustand_02  : 152|8@1+ (0.500000,0.000000) [0.000000|100.000000] "Unit_PerCent" ICAS1_Gateway ICAS1_KommunikationsServer
 SG_ MO_Powermeter_Elm_02  : 168|12@1+ (0.050000,-102.400000) [-100.000000|100.000000] "Unit_PerCent" Vector__XXX
 SG_ MO_Powermeter  : 180|12@1+ (1.000000,0.000000) [0.000000|4092.000000] "" ICAS1_KommunikationsServer

BO_ 512 Motor_53: 32 Motor_BEV
 SG_ TSK_Wunschgeschw  : 12|10@1+ (0.320000,0.000000) [0.000000|326.720000] "Unit_KiloMeterPerHour" ICAS1_Gateway ICAS1_KommunikationsServer
 SG_ TSK_praediktiver_Hinweis  : 22|3@1+ (1.000000,0.000000) [0.000000|7.000000] "" ICAS1_Gateway
 SG_ TSK_naechstes_Event  : 25|6@1+ (1.000000,0.000000) [0.000000|63.000000] "" ICAS1_Gateway
 SG_ TSK_Fahrzeugstatus_praed_Fkt  : 31|3@1+ (1.000000,0.000000) [0.000000|7.000000] "" ICAS1_Gateway
 SG_ TSK_Texte  : 40|5@1+ (1.000000,0.000000) [0.000000|31.000000] "" ICAS1_Gateway ICAS1_KommunikationsServer
 SG_ TSK_Akustik  : 45|3@1+ (1.000000,0.000000) [0.000000|7.000000] "" ICAS1_Gateway ICAS1_KommunikationsServer
 SG_ TSK_Texte_Primaeranz  : 48|5@1+ (1.000000,0.000000) [0.000000|31.000000] "" ICAS1_Gateway ICAS1_KommunikationsServer
 SG_ TSK_Limiter_Fahrerinfo  : 53|2@1+ (1.000000,0.000000) [0.000000|3.000000] "" ICAS1_Gateway ICAS1_KommunikationsServer
 SG_ TSK_Limiter_Anzeige  : 55|1@1+ (1.000000,0.000000) [0.000000|1.000000] "" ICAS1_Gateway ICAS1_KommunikationsServer
 SG_ TSK_Fahrzeugstatus_GRA  : 56|1@1+ (1.000000,0.000000) [0.000000|1.000000] "" ICAS1_Gateway ICAS1_KommunikationsServer
 SG_ TSK_Fahrzeugstatus_Limiter  : 57|1@1+ (1.000000,0.000000) [0.000000|1.000000] "" ICAS1_Gateway ICAS1_KommunikationsServer
 SG_ MO_Motorlaufwarnung  : 58|1@1+ (1.000000,0.000000) [0.000000|1.000000] "" ICAS1_Gateway
 SG_ TSK_naechstes_Event_Einheit  : 60|1@1+ (1.000000,0.000000) [0.000000|1.000000] "" ICAS1_Gateway
 SG_ TSK_Status_Anzeige  : 61|3@1+ (1.000000,0.000000) [0.000000|7.000000] "" ICAS1_Gateway ICAS1_KommunikationsServer
 SG_ MO_Sperrung_FahrPr_BZS  : 64|8@1+ (1.000000,0.000000) [0.000000|255.000000] "" ICAS1_Gateway
 SG_ MO_Rampenzeit_Generator_Anf  : 72|4@1+ (1.000000,0.000000) [0.000000|15.000000] "" ICAS1_Gateway
 SG_ MO_Prio_MAX_Wunschdrehzahl  : 76|1@1+ (1.000000,0.000000) [0.000000|1.000000] "" ICAS1_Gateway
 SG_ MO_Prio_MIN_Wunschdrehzahl  : 77|1@1+ (1.000000,0.000000) [0.000000|1.000000] "" ICAS1_Gateway
 SG_ MO_Luftpfad_aktiv  : 78|1@1+ (1.000000,0.000000) [0.000000|1.000000] "" ICAS1_Gateway
 SG_ MO_v_Begrenz_Aktivierbar  : 79|1@1+ (1.000000,0.000000) [0.000000|1.000000] "" ICAS1_Gateway
 SG_ MO_Drehzahlbeeinflussung  : 80|8@1+ (0.390000,0.000000) [0.000000|99.450000] "Unit_PerCent" ICAS1_Gateway
 SG_ MO_MIN_Wunschdrehzahl  : 88|8@1+ (25.000000,0.000000) [0.000000|6350.000000] "Unit_MinutInver" ICAS1_Gateway
 SG_ MO_MAX_Wunschdrehzahl  : 96|9@1+ (25.000000,0.000000) [0.000000|12750.000000] "Unit_MinutInver" ICAS1_Gateway
 SG_ MO_Charisma_FahrPr  : 105|4@1+ (1.000000,0.000000) [0.000000|15.000000] "" ICAS1_Gateway
 SG_ MO_Charisma_Status  : 109|2@1+ (1.000000,0.000000) [0.000000|3.000000] "" ICAS1_Gateway
 SG_ MO_StSt_Charisma_FahrPr  : 111|4@1+ (1.000000,0.000000) [0.000000|15.000000] "" ICAS1_Gateway
 SG_ MO_StSt_Charisma_Status  : 115|2@1+ (1.000000,0.000000) [0.000000|3.000000] "" ICAS1_Gateway
 SG_ MO_BZS_Charisma_FahrPr  : 117|4@1+ (1.000000,0.000000) [0.000000|15.000000] "" ICAS1_Gateway
 SG_ MO_BZS_Charisma_Status  : 121|2@1+ (1.000000,0.000000) [0.000000|3.000000] "" ICAS1_Gateway
 SG_ MO_NGS_Position  : 123|1@1+ (1.000000,0.000000) [0.000000|1.000000] "" ICAS1_Gateway
 SG_ MO_NGS_Status  : 124|2@1+ (1.000000,0.000000) [0.000000|3.000000] "" ICAS1_Gateway
 SG_ MO_v_Begrenzung_Niveau  : 126|2@1+ (1.000000,0.000000) [0.000000|3.000000] "" ICAS1_Gateway
 SG_ MO_Anzeige_Rekuperation  : 128|8@1+ (0.500000,-0.500000) [0.000000|100.000000] "Unit_PerCent" ICAS1_Gateway
 SG_ PEA_Fortschrittsanzeige  : 136|7@1+ (1.000000,0.000000) [0.000000|100.000000] "Unit_PerCent" ICAS1_Gateway
 SG_ MO_Anzeige_Fahrbereitschaft  : 143|1@1+ (1.000000,0.000000) [0.000000|1.000000] "" ICAS1_Gateway ICAS1_KommunikationsServer
 SG_ MO_Boost_verfuegbar  : 144|8@1+ (0.400000,-0.400000) [0.000000|100.400000] "Unit_PerCent" ICAS1_Gateway
 SG_ MO_Overboost  : 152|1@1+ (1.000000,0.000000) [0.000000|1.000000] "" ICAS1_Gateway
 SG_ MO_Boost_aktiv  : 153|1@1+ (1.000000,0.000000) [0.000000|1.000000] "" ICAS1_Gateway
 SG_ MO_Anzeige_Betriebsmodus  : 154|4@1+ (1.000000,0.000000) [0.000000|15.000000] "" ICAS1_Gateway
 SG_ PEA_Hinweis  : 158|2@1+ (1.000000,0.000000) [0.000000|3.000000] "" ICAS1_Gateway
 SG_ PEA_Ereignisanzeige  : 160|5@1+ (1.000000,0.000000) [0.000000|31.000000] "" ICAS1_Gateway
 SG_ PEA_Ereignisanzeige_temporaer  : 165|1@1+ (1.000000,0.000000) [0.000000|1.000000] "" ICAS1_Gateway
 SG_ PEA_Abschalttexte  : 166|2@1+ (1.000000,0.000000) [0.000000|3.000000] "" ICAS1_Gateway
 SG_ PEA_Zielgeschw_Einheit  : 168|1@1+ (1.000000,0.000000) [0.000000|1.000000] "" ICAS1_Gateway
 SG_ PEA_Zielgeschw  : 169|5@1+ (1.000000,0.000000) [0.000000|31.000000] "" ICAS1_Gateway
 SG_ MO_Antriebsstrang_Warnung_HS  : 174|2@1+ (1.000000,0.000000) [0.000000|3.000000] "" ICAS1_Gateway
 SG_ MO_Anzeige_Verbrauch_oE  : 176|16@1+ (0.005000,0.000000) [0.000000|327.675000] "Unit_None" ICAS1_Gateway

BO_ 332 Motor_54: 32 Motor_BEV
 SG_ MO_Anforderung_HMS  : 12|3@1+ (1.000000,0.000000) [0.000000|7.000000] "" ICAS1_Gateway
 SG_ FoD_DTC_TSK_GRA  : 15|1@1+ (1.000000,0.000000) [0.000000|1.000000] "" ICAS1_Gateway
 SG_ TSK_vMax_aktuell  : 16|8@1+ (1.000000,0.000000) [0.000000|253.000000] "Unit_KiloMeterPerHour" ICAS1_Gateway
 SG_ TSK_Status_EA  : 32|3@1+ (1.000000,0.000000) [0.000000|7.000000] "" ICAS1_Gateway
 SG_ FoD_DTC_TSK_ACC  : 35|1@1+ (1.000000,0.000000) [0.000000|1.000000] "" ICAS1_Gateway
 SG_ TSK_ACC_FoD_Status  : 36|2@1+ (1.000000,0.000000) [0.000000|3.000000] "" ICAS1_Gateway
 SG_ TSK_GRA_FoD_Status  : 38|2@1+ (1.000000,0.000000) [0.000000|3.000000] "" ICAS1_Gateway
 SG_ TSK_vMax_Fahrerassistenz  : 40|9@1+ (1.000000,0.000000) [0.000000|510.000000] "" ICAS1_Gateway
 SG_ TSK_Einheit_vMax_Fahrerassistenz  : 49|1@1+ (1.000000,0.000000) [0.000000|1.000000] "" ICAS1_Gateway
 SG_ TSK_Status_PLA  : 50|3@1+ (1.000000,0.000000) [0.000000|7.000000] "" ICAS1_Gateway
 SG_ TSK_aktives_System  : 53|3@1+ (1.000000,0.000000) [0.000000|7.000000] "" ICAS1_Gateway
 SG_ TSK_erhoehter_Fahrwiderstand  : 56|1@1+ (1.000000,0.000000) [0.000000|1.000000] "" ICAS1_Gateway
 SG_ TSK_Anf_Antriebsmoment  : 57|1@1+ (1.000000,0.000000) [0.000000|1.000000] "" ICAS1_Gateway
 SG_ TSK_Status_ARA  : 58|3@1+ (1.000000,0.000000) [0.000000|7.000000] "" ICAS1_Gateway
 SG_ TSK_Status_IPA  : 61|3@1+ (1.000000,0.000000) [0.000000|7.000000] "" ICAS1_Gateway
 SG_ MO_Fahrbereitschaft  : 76|2@1+ (1.000000,0.000000) [0.000000|3.000000] "" ICAS1_Gateway LE1 LE2
 SG_ MO_Freilauf_Info  : 78|2@1+ (1.000000,0.000000) [0.000000|3.000000] "" ICAS1_Gateway
 SG_ MO_Krit_Heckobjekt  : 81|3@1+ (1.000000,0.000000) [0.000000|7.000000] "" ICAS1_Gateway
 SG_ MO_NGS_Gangpos  : 84|3@1+ (1.000000,0.000000) [0.000000|7.000000] "" ICAS1_Gateway
 SG_ MO_Freilauf_Status  : 87|3@1+ (1.000000,0.000000) [0.000000|7.000000] "" ICAS1_Gateway
 SG_ MO_EBoost_verf_praed  : 90|2@1+ (1.000000,0.000000) [0.000000|3.000000] "" ICAS1_Gateway
 SG_ MO_Heckspoiler_Anf  : 92|1@1+ (1.000000,0.000000) [0.000000|1.000000] "" ICAS1_Gateway
 SG_ MO_eLaunch_verf  : 93|2@1+ (1.000000,0.000000) [0.000000|3.000000] "" ICAS1_Gateway
 SG_ MO_Positionierung_aktiv  : 95|1@1+ (1.000000,0.000000) [0.000000|1.000000] "" ICAS1_Gateway
 SG_ MO_Freilauf_Typ  : 98|2@1+ (1.000000,0.000000) [0.000000|3.000000] "" ICAS1_Gateway
 SG_ MO_Startwunsch  : 100|1@1+ (1.000000,0.000000) [0.000000|1.000000] "" ICAS1_Gateway
 SG_ OBD_Calc_Load_Val  : 128|8@1+ (0.392157,0.000000) [0.000000|100.000000] "Unit_PerCent" ICAS1_Gateway LE1 LE2
 SG_ OBD_Eng_Cool_Temp  : 136|8@1+ (1.000000,-40.000000) [-40.000000|215.000000] "Unit_DegreCelsi" ICAS1_Gateway LE1 LE2
 SG_ OBD_Abs_Throttle_Pos  : 144|8@1+ (0.392157,0.000000) [0.000000|100.000000] "Unit_PerCent" ICAS1_Gateway LE1 LE2
 SG_ OBD_Abs_Load_Val  : 152|16@1+ (0.392157,0.000000) [0.000000|25700.000000] "Unit_PerCent" ICAS1_Gateway LE1 LE2
 SG_ OBD_Abs_Pedal_Pos  : 168|8@1+ (0.392157,0.000000) [0.000000|100.000000] "Unit_PerCent" ICAS1_Gateway LE1 LE2
 SG_ MO_Servicemodus  : 176|4@1+ (1.000000,0.000000) [0.000000|15.000000] "" ICAS1_Gateway LE1 LE2
 SG_ OBD_ClearMem_Inhibit  : 183|1@1+ (1.000000,0.000000) [0.000000|1.000000] "" ICAS1_Gateway LE1 LE2
 SG_ OBD_Sperrung_Kaltstart_Denom  : 184|1@1+ (1.000000,0.000000) [0.000000|1.000000] "" ICAS1_Gateway LE1 LE2
 SG_ MO_QBit_Aussen_Temp  : 185|1@1+ (1.000000,0.000000) [0.000000|1.000000] "" ICAS1_Gateway
 SG_ OBD_Sperrung_IUMPR  : 186|1@1+ (1.000000,0.000000) [0.000000|1.000000] "" ICAS1_Gateway LE1 LE2
 SG_ OBD_Kaltstart_Denominator  : 187|1@1+ (1.000000,0.000000) [0.000000|1.000000] "" ICAS1_Gateway LE1 LE2
 SG_ OBD_Minimum_Trip  : 188|1@1+ (1.000000,0.000000) [0.000000|1.000000] "" ICAS1_Gateway LE1 LE2
 SG_ OBD_Driving_Cycle  : 189|1@1+ (1.000000,0.000000) [0.000000|1.000000] "" ICAS1_Gateway LE1 LE2
 SG_ OBD_Warm_Up_Cycle  : 190|1@1+ (1.000000,0.000000) [0.000000|1.000000] "" ICAS1_Gateway LE1 LE2
 SG_ OBD_Normed_Trip  : 191|1@1+ (1.000000,0.000000) [0.000000|1.000000] "" ICAS1_Gateway LE1 LE2
 SG_ OBD_Aussen_Temp_gef  : 248|8@1+ (1.000000,-40.000000) [-40.000000|213.000000] "Unit_DegreCelsi" ICAS1_Gateway

BO_ 246 Motor_55: 32 Motor_BEV
 SG_ Motor_55_CRC  : 0|8@1+ (1.000000,0.000000) [0.000000|255.000000] "" ICAS1_Gateway
 SG_ Motor_55_BZ  : 8|4@1+ (1.000000,0.000000) [0.000000|15.000000] "" ICAS1_Gateway
 SG_ TS_Faktor_Radmomente  : 12|2@1+ (1.000000,0.000000) [0.000000|3.000000] "" ICAS1_Gateway
 SG_ TS_Status_MomRad_Ist  : 14|2@1+ (1.000000,0.000000) [0.000000|3.000000] "" ICAS1_Gateway
 SG_ TS_MomRad_verfuegb_maxReku_Summe  : 16|12@1+ (3.000000,-12279.000000) [-12279.000000|0.000000] "" ICAS1_Gateway
 SG_ TS_MomRad_Ist  : 28|13@1+ (3.000000,-12279.000000) [-12279.000000|12279.000000] "Unit_None" ICAS1_Gateway
 SG_ TS_MomRad_Soll_Summe  : 41|13@1+ (3.000000,-12279.000000) [-12279.000000|12279.000000] "Unit_None" ICAS1_Gateway
 SG_ TS_MomRad_Wunsch  : 54|13@1+ (3.000000,-12279.000000) [-12279.000000|12279.000000] "Unit_None" ICAS1_Gateway
 SG_ TS_MomRad_Wunsch_sek  : 67|13@1+ (3.000000,-12279.000000) [-12279.000000|12279.000000] "Unit_None" ICAS1_Gateway
 SG_ TS_MomRad_verfuegb_max  : 80|12@1+ (3.000000,0.000000) [0.000000|12279.000000] "Unit_None" ICAS1_Gateway
 SG_ TS_MomRad_verfuegb_max_sek  : 92|12@1+ (3.000000,0.000000) [0.000000|12279.000000] "Unit_None" ICAS1_Gateway
 SG_ TS_MomRad_verfuegb_maxReku  : 104|12@1+ (3.000000,-12279.000000) [-12279.000000|0.000000] "Unit_None" ICAS1_Gateway
 SG_ TS_MomRad_verfuegb_maxReku_sek  : 116|12@1+ (3.000000,-12279.000000) [-12279.000000|0.000000] "Unit_None" ICAS1_Gateway
 SG_ TS_MomRad_Ist_sek  : 128|13@1+ (3.000000,-12279.000000) [-12279.000000|12279.000000] "Unit_None" ICAS1_Gateway
 SG_ TS_Allrad_Anteil_sek  : 141|9@1+ (0.200000,0.000000) [0.000000|100.000000] "Unit_PerCent" ICAS1_Gateway
 SG_ FDR_Allrad_Anteil_max_sek  : 150|9@1+ (0.200000,0.000000) [0.000000|100.000000] "Unit_PerCent" ICAS1_Gateway
 SG_ FDR_Allrad_Anteil_min_sek  : 159|9@1+ (0.200000,0.000000) [0.000000|100.000000] "Unit_PerCent" ICAS1_Gateway
 SG_ FDR_MomRad_Eingriff  : 168|13@1+ (3.000000,-12279.000000) [-12279.000000|12279.000000] "Unit_NewtoMeter" ICAS1_Gateway
 SG_ FDR_Status_Eingriff  : 181|1@1+ (1.000000,0.000000) [0.000000|1.000000] "" ICAS1_Gateway
 SG_ FDR_MomRad_Eingriff_sek  : 182|13@1+ (3.000000,-12279.000000) [-12279.000000|12279.000000] "Unit_NewtoMeter" ICAS1_Gateway
 SG_ FDR_Status_Eingriff_sek  : 195|1@1+ (1.000000,0.000000) [0.000000|1.000000] "" ICAS1_Gateway

BU_:  Airbag BAP_Tester ICAS1_Gateway ICAS1_KommunikationsServer LE1 LE2 Motor_BEV Schaltbetaetigung

BO_ 967 Motor_26: 8 Motor_BEV
 SG_ MO_Kuehlerluefter_MUX M : 0|1@1+ (1.000000,0.000000) [0.000000|1.000000] "siema ooo" ICAS1_Gateway
 SG_ MO_Kuehlerluefter_1 m0 : 1|7@1+ (1.000000,0.000000) [0.000000|100.000000] "Unit_PerCent" ICAS1_Gateway
 SG_ MO_Kuehlerluefter_2 m1 : 1|7@1+ (1.000000,0.000000) [0.000000|100.000000] "Unit_PerCent" ICAS1_Gateway
 SG_ MO_EFLEX_Lampe  : 8|2@1+ (1.000000,0.000000) [0.000000|3.000000] "" ICAS1_Gateway
 SG_ MO_KJS_nicht_bereit  : 10|1@1+ (1.000000,0.000000) [0.000000|1.000000] "" ICAS1_Gateway
 SG_ MO_ITM_Warnung_Pumpe  : 11|1@1+ (1.000000,0.000000) [0.000000|1.000000] "" ICAS1_Gateway
 SG_ WIV_Anzeige_aktiv  : 12|1@1+ (1.000000,0.000000) [0.000000|1.000000] "" ICAS1_Gateway
 SG_ WIV_Oelmin_Warn  : 13|1@1+ (1.000000,0.000000) [0.000000|1.000000] "" ICAS1_Gateway
 SG_ WIV_Sensorfehler  : 14|1@1+ (1.000000,0.000000) [0.000000|1.000000] "" ICAS1_Gateway
 SG_ WIV_Schieflage  : 15|1@1+ (1.000000,0.000000) [0.000000|1.000000] "" ICAS1_Gateway
 SG_ WIV_Oelstand  : 16|4@1+ (12.500000,0.000000) [0.000000|100.000000] "Unit_PerCent" ICAS1_Gateway
 SG_ MO_Zustand_HWP  : 20|2@1+ (1.000000,0.000000) [0.000000|3.000000] "" ICAS1_Gateway
 SG_ OLEV_Systemstoerung  : 22|1@1+ (1.000000,0.000000) [0.000000|1.000000] "" ICAS1_Gateway
 SG_ MO_Oelwarnung_max  : 23|1@1+ (1.000000,0.000000) [0.000000|1.000000] "" ICAS1_Gateway
 SG_ WIV_Oelsystem_aktiv  : 24|1@1+ (1.000000,0.000000) [0.000000|1.000000] "" ICAS1_Gateway
 SG_ WIV_nicht_betriebswarm  : 25|1@1+ (1.000000,0.000000) [0.000000|1.000000] "" ICAS1_Gateway
 SG_ WIV_Ueberfuell_Warn  : 26|1@1+ (1.000000,0.000000) [0.000000|1.000000] "" ICAS1_Gateway
 SG_ WIV_laufender_Motor  : 27|1@1+ (1.000000,0.000000) [0.000000|1.000000] "" ICAS1_Gateway
 SG_ MO_E_Warnungen  : 28|4@1+ (1.000000,0.000000) [0.000000|15.000000] "" ICAS1_Gateway
 SG_ MO_Text_Motorstart  : 32|4@1+ (1.000000,0.000000) [0.000000|15.000000] "" ICAS1_Gateway
 SG_ MO_E_Texte  : 36|4@1+ (1.000000,0.000000) [0.000000|15.000000] "" ICAS1_Gateway
 SG_ WIV_Oeldyn_avl  : 40|1@1+ (1.000000,0.000000) [0.000000|1.000000] "" ICAS1_Gateway
 SG_ MO_Text_Partikelfil_Reg  : 41|1@1+ (1.000000,0.000000) [0.000000|1.000000] "" ICAS1_Gateway
 SG_ OLEV_Oelstand_nicht_vorhanden  : 42|1@1+ (1.000000,0.000000) [0.000000|1.000000] "" ICAS1_Gateway
 SG_ WIV_Oelmenge  : 43|5@1+ (125.000000,0.000000) [0.000000|3875.000000] "Unit_MilliLiter" ICAS1_Gateway
 SG_ MO_Systemlampe  : 48|1@1+ (1.000000,0.000000) [0.000000|1.000000] "" ICAS1_Gateway
 SG_ MO_OBD2_Lampe  : 49|1@1+ (1.000000,0.000000) [0.000000|1.000000] "" ICAS1_Gateway
 SG_ MO_Heissleuchte  : 50|1@1+ (1.000000,0.000000) [0.000000|1.000000] "" ICAS1_Gateway
 SG_ MO_Partikel_Lampe  : 51|1@1+ (1.000000,0.000000) [0.000000|1.000000] "" ICAS1_Gateway
 SG_ MO_RedFahrleistung_Lampe  : 52|1@1+ (1.000000,0.000000) [0.000000|1.000000] "" ICAS1_Gateway ICAS1_KommunikationsServer
 SG_ WIV_Oelstand_nicht_vorhanden  : 53|1@1+ (1.000000,0.000000) [0.000000|1.000000] "" ICAS1_Gateway
 SG_ WIV_nachfuellanzeige_ein  : 54|1@1+ (1.000000,0.000000) [0.000000|1.000000] "" ICAS1_Gateway
 SG_ WIV_Ueberfuell_deaktiv  : 55|1@1+ (1.000000,0.000000) [0.000000|1.000000] "" ICAS1_Gateway
 SG_ WIV_Unterfuell_Warn  : 56|1@1+ (1.000000,0.000000) [0.000000|1.000000] "" ICAS1_Gateway
 SG_ MO_Tankdeckel_Lampe  : 57|1@1+ (1.000000,0.000000) [0.000000|1.000000] "" ICAS1_Gateway
 SG_ MO_Text_Tankdeckelwarn  : 58|1@1+ (1.000000,0.000000) [0.000000|1.000000] "" ICAS1_Gateway
 SG_ MO_Vorglueh_Lampe  : 59|1@1+ (1.000000,0.000000) [0.000000|1.000000] "" ICAS1_Gateway
 SG_ WIV_Oeldr_Warn_Motor  : 60|1@1+ (1.000000,0.000000) [0.000000|1.000000] "" ICAS1_Gateway
 SG_ MO_E_Mode  : 61|3@1+ (1.000000,0.000000) [0.000000|7.000000] "" ICAS1_Gateway

BO_ 706 Motor_41: 8 Motor_BEV
 SG_ MO_Anzeige_StSt_Text  : 12|4@1+ (1.000000,0.000000) [0.000000|15.000000] "" Vector__XXX
 SG_ MO_Anzeige_StSt_Symbol  : 16|3@1+ (1.000000,0.000000) [0.000000|7.000000] "" Vector__XXX
 SG_ MO_ADR_Status  : 19|2@1+ (1.000000,0.000000) [0.000000|3.000000] "" Vector__XXX
 SG_ MO_AGA_Sound_Texte  : 21|2@1+ (1.000000,0.000000) [0.000000|3.000000] "" Vector__XXX
 SG_ MO_Anzeige_FMAus_Text  : 23|1@1+ (1.000000,0.000000) [0.000000|1.000000] "" Vector__XXX
 SG_ PEA_Texte  : 25|3@1+ (1.000000,0.000000) [0.000000|7.000000] "" Vector__XXX
 SG_ TSK_Ueberstimmt_vMax_FahrerInfo  : 28|2@1+ (1.000000,0.000000) [0.000000|3.000000] "" Vector__XXX
 SG_ MO_Rekuperationsstufe  : 32|3@1+ (1.000000,0.000000) [0.000000|7.000000] "" ICAS1_KommunikationsServer
 SG_ TSK_Einheit_vMax_FahrerInfo  : 35|1@1+ (1.000000,0.000000) [0.000000|1.000000] "" ICAS1_KommunikationsServer
 SG_ TSK_Status_vMax_FahrerInfo  : 36|2@1+ (1.000000,0.000000) [0.000000|3.000000] "" ICAS1_KommunikationsServer
 SG_ MO_Anz_Kuehlerluefter  : 47|3@1+ (1.000000,0.000000) [0.000000|7.000000] "" Vector__XXX
 SG_ FDR_Warnung_ALR  : 50|2@1+ (1.000000,0.000000) [0.000000|3.000000] "" ICAS1_KommunikationsServer
 SG_ TSK_vMax_FahrerInfo  : 56|8@1+ (1.000000,15.000000) [16.000000|270.000000] "" ICAS1_KommunikationsServer

BO_ 267 Motor_51: 32 Motor_BEV
 SG_ Motor_51_CRC  : 0|8@1+ (1.000000,0.000000) [0.000000|255.000000] "" ICAS1_Gateway
 SG_ Motor_51_BZ  : 8|4@1+ (1.000000,0.000000) [0.000000|15.000000] "" ICAS1_Gateway
 SG_ MO_Fahrpedalrohwert_01  : 12|8@1+ (0.400000,0.000000) [0.000000|101.600000] "Unit_PerCent" Airbag ICAS1_Gateway
 SG_ MO_QBit_Fahrpedalwerte_01  : 20|1@1+ (1.000000,0.000000) [0.000000|1.000000] "" Airbag ICAS1_Gateway
 SG_ MO_Fahrpedalgradient  : 21|8@1+ (25.000000,0.000000) [0.000000|6350.000000] "Unit_PerCentPerSecon" ICAS1_Gateway
 SG_ MO_Sig_Fahrpedalgradient  : 29|1@1+ (1.000000,0.000000) [0.000000|1.000000] "" ICAS1_Gateway
 SG_ MO_rel_Saugrohrdruck  : 30|6@1+ (18.000000,0.000000) [0.000000|1116.000000] "Unit_MilliBar" ICAS1_Gateway
 SG_ MO_rel_Saugrohrdruck_gem_err  : 36|1@1+ (1.000000,0.000000) [0.000000|1.000000] "" ICAS1_Gateway
 SG_ MO_Moment_im_Leerlauf  : 37|1@1+ (1.000000,0.000000) [0.000000|1.000000] "" ICAS1_Gateway
 SG_ MO_Schubabschaltung  : 38|1@1+ (1.000000,0.000000) [0.000000|1.000000] "" ICAS1_Gateway
 SG_ MO_Solldrehz_Leerlauf  : 40|8@1+ (10.000000,0.000000) [0.000000|2540.000000] "Unit_MinutInver" ICAS1_Gateway
 SG_ MO_Entkopplung_Sollschlupf  : 48|7@1+ (20.000000,0.000000) [0.000000|2480.000000] "Unit_MinutInver" ICAS1_Gateway
 SG_ MO_temporaere_Fahrerabwesenheit  : 55|1@1+ (1.000000,0.000000) [0.000000|1.000000] "" ICAS1_Gateway
 SG_ TSK_a_Soll_gradientenbegrenzt  : 57|7@1+ (0.100000,-7.200000) [-7.200000|5.400000] "Unit_MeterPerSeconSquar" ICAS1_Gateway
 SG_ TSK_Radbremsmom  : 76|12@1+ (8.000000,0.000000) [0.000000|32760.000000] "Unit_NewtoMeter" ICAS1_Gateway
 SG_ TSK_Status  : 88|3@1+ (1.000000,0.000000) [0.000000|7.000000] "" ICAS1_Gateway
 SG_ TSK_v_Begrenzung_aktiv  : 91|1@1+ (1.000000,0.000000) [0.000000|1.000000] "" ICAS1_Gateway
 SG_ TSK_Standby_Anf_ESP  : 92|1@1+ (1.000000,0.000000) [0.000000|1.000000] "" ICAS1_Gateway
 SG_ TSK_Freig_WU  : 93|1@1+ (1.000000,0.000000) [0.000000|1.000000] "" ICAS1_Gateway
 SG_ TSK_Freig_Verzoeg_Anf  : 94|1@1+ (1.000000,0.000000) [0.000000|1.000000] "" ICAS1_Gateway
 SG_ TSK_Limiter_ausgewaehlt  : 95|1@1+ (1.000000,0.000000) [0.000000|1.000000] "" ICAS1_Gateway
 SG_ TSK_Wunsch_Uebersetz  : 96|10@1+ (0.024500,0.000000) [0.024500|25.063500] "" ICAS1_Gateway
 SG_ TSK_Hauptschalter_GRA_ACC  : 106|2@1+ (1.000000,0.000000) [0.000000|3.000000] "" ICAS1_Gateway ICAS1_KommunikationsServer
 SG_ TSK_SRBM_Anf_ASIL  : 108|3@1+ (1.000000,0.000000) [0.000000|7.000000] "" ICAS1_Gateway
 SG_ TSK_ax_Getriebe_02  : 112|9@1+ (0.024000,-2.016000) [-2.016000|10.224000] "Unit_MeterPerSeconSquar" ICAS1_Gateway
 SG_ TSK_Zwangszusch_ESP  : 121|1@1+ (1.000000,0.000000) [0.000000|1.000000] "" ICAS1_Gateway
 SG_ TSK_zul_Regelabw  : 122|6@1+ (0.024000,0.000000) [0.000000|1.512000] "Unit_MeterPerSeconSquar" ICAS1_Gateway
 SG_ MO_Status_MinDrzEingriff  : 235|3@1+ (1.000000,0.000000) [0.000000|7.000000] "" ICAS1_Gateway
 SG_ MO_Status_MaxDrzEingriff  : 238|3@1+ (1.000000,0.000000) [0.000000|7.000000] "" ICAS1_Gateway
 SG_ MO_Status_MinDrzEingriff_sek  : 241|3@1+ (1.000000,0.000000) [0.000000|7.000000] "" ICAS1_Gateway
 SG_ MO_Status_MaxDrzEingriff_sek  : 244|3@1+ (1.000000,0.000000) [0.000000|7.000000] "" ICAS1_Gateway
 SG_ GRA_KuFu_aktiv  : 247|1@1+ (1.000000,0.000000) [0.000000|1.000000] "" ICAS1_Gateway
 SG_ TSK_SRBM_max_Gradient  : 248|7@1+ (50.000000,0.000000) [0.000000|6250.000000] "Unit_NewtoMeterPerSecon" ICAS1_Gateway
 SG_ LIM_KuFu_aktiv  : 255|1@1+ (1.000000,0.000000) [0.000000|1.000000] "" ICAS1_Gateway

BO_ 330 Motor_52: 32 Motor_BEV
 SG_ MO_Hochschaltdrehz  : 21|12@1+ (3.000000,0.000000) [3.000000|12282.000000] "Unit_MinutInver" Vector__XXX
 SG_ MO_Anzeige_Verbr_Einheit  : 33|2@1+ (1.000000,0.000000) [0.000000|3.000000] "" Vector__XXX
 SG_ MO_Schaltblitz_Anz  : 35|7@1+ (1.000000,0.000000) [0.000000|100.000000] "Unit_PerCent" Vector__XXX
 SG_ MO_Anzeige_Drehmoment  : 42|11@1+ (1.000000,0.000000) [0.000000|2045.000000] "Unit_NewtoMeter" Vector__XXX
 SG_ MO_Anzeige_Leistung  : 53|11@1+ (0.600000,0.000000) [0.000000|1227.000000] "Unit_KiloWatt" Vector__XXX
 SG_ MO_rel_Ladedruck  : 64|8@1+ (0.400000,0.000000) [0.000000|100.000000] "Unit_PerCent" Vector__XXX
 SG_ MO_Istgang  : 72|4@1+ (1.000000,0.000000) [0.000000|15.000000] "" Vector__XXX
 SG_ MO_Sollgang  : 76|4@1+ (1.000000,0.000000) [0.000000|15.000000] "" Vector__XXX
 SG_ MO_Oeldruck  : 80|8@1+ (0.040000,0.000000) [0.000000|10.000000] "Unit_Bar" Vector__XXX
 SG_ MO_Anzeigedrehz  : 88|12@1+ (3.000000,0.000000) [0.000000|12282.000000] "Unit_MinutInver" Vector__XXX
 SG_ MO_Effizienzmodus  : 100|1@1+ (1.000000,0.000000) [0.000000|1.000000] "" Vector__XXX
 SG_ MO_Fehler_Oeldrucksensor  : 101|1@1+ (1.000000,0.000000) [0.000000|1.000000] "" Vector__XXX
 SG_ MO_Schaltempf_verfbar  : 102|1@1+ (1.000000,0.000000) [0.000000|1.000000] "" Vector__XXX
 SG_ MO_Ladedruck  : 103|9@1+ (0.010000,0.000000) [0.000000|5.100000] "Unit_Bar" Vector__XXX
 SG_ MO_KVS  : 112|15@1+ (1.000000,0.000000) [0.000000|32767.000000] "Unit_MicroLiter" Vector__XXX
 SG_ MO_KVS_Ueberlauf  : 127|1@1+ (1.000000,0.000000) [0.000000|1.000000] "" Vector__XXX
 SG_ MO_ePowermeter  : 128|8@1+ (0.400000,-0.400000) [0.000000|100.800000] "Unit_PerCent" Vector__XXX
 SG_ MO_ePerformance  : 136|8@1+ (0.400000,-0.400000) [0.000000|100.800000] "Unit_PerCent" ICAS1_KommunikationsServer
 SG_ MO_Zust_Antrieb  : 144|4@1+ (1.000000,0.000000) [0.000000|15.000000] "" Vector__XXX
 SG_ MO_Zust_Betriebsstrategie  : 148|3@1+ (1.000000,0.000000) [0.000000|7.000000] "" Vector__XXX
 SG_ Ladezustand_02  : 152|8@1+ (0.500000,0.000000) [0.000000|100.000000] "Unit_PerCent" ICAS1_Gateway ICAS1_KommunikationsServer
 SG_ MO_Powermeter_Elm_02  : 168|12@1+ (0.050000,-102.400000) [-100.000000|100.000000] "Unit_PerCent" Vector__XXX
 SG_ MO_Powermeter  : 180|12@1+ (1.000000,0.000000) [0.000000|4092.000000] "" ICAS1_KommunikationsServer

BO_ 512 Motor_53: 32 Motor_BEV
 SG_ TSK_Wunschgeschw  : 12|10@1+ (0.320000,0.000000) [0.000000|326.720000] "Unit_KiloMeterPerHour" ICAS1_Gateway ICAS1_KommunikationsServer
 SG_ TSK_praediktiver_Hinweis  : 22|3@1+ (1.000000,0.000000) [0.000000|7.000000] "" ICAS1_Gateway
 SG_ TSK_naechstes_Event  : 25|6@1+ (1.000000,0.000000) [0.000000|63.000000] "" ICAS1_Gateway
 SG_ TSK_Fahrzeugstatus_praed_Fkt  : 31|3@1+ (1.000000,0.000000) [0.000000|7.000000] "" ICAS1_Gateway
 SG_ TSK_Texte  : 40|5@1+ (1.000000,0.000000) [0.000000|31.000000] "" ICAS1_Gateway ICAS1_KommunikationsServer
 SG_ TSK_Akustik  : 45|3@1+ (1.000000,0.000000) [0.000000|7.000000] "" ICAS1_Gateway ICAS1_KommunikationsServer
 SG_ TSK_Texte_Primaeranz  : 48|5@1+ (1.000000,0.000000) [0.000000|31.000000] "" ICAS1_Gateway ICAS1_KommunikationsServer
 SG_ TSK_Limiter_Fahrerinfo  : 53|2@1+ (1.000000,0.000000) [0.000000|3.000000] "" ICAS1_Gateway ICAS1_KommunikationsServer
 SG_ TSK_Limiter_Anzeige  : 55|1@1+ (1.000000,0.000000) [0.000000|1.000000] "" ICAS1_Gateway ICAS1_KommunikationsServer
 SG_ TSK_Fahrzeugstatus_GRA  : 56|1@1+ (1.000000,0.000000) [0.000000|1.000000] "" ICAS1_Gateway ICAS1_KommunikationsServer
 SG_ TSK_Fahrzeugstatus_Limiter  : 57|1@1+ (1.000000,0.000000) [0.000000|1.000000] "" ICAS1_Gateway ICAS1_KommunikationsServer
 SG_ MO_Motorlaufwarnung  : 58|1@1+ (1.000000,0.000000) [0.000000|1.000000] "" ICAS1_Gateway
 SG_ TSK_naechstes_Event_Einheit  : 60|1@1+ (1.000000,0.000000) [0.000000|1.000000] "" ICAS1_Gateway
 SG_ TSK_Status_Anzeige  : 61|3@1+ (1.000000,0.000000) [0.000000|7.000000] "" ICAS1_Gateway ICAS1_KommunikationsServer
 SG_ MO_Sperrung_FahrPr_BZS  : 64|8@1+ (1.000000,0.000000) [0.000000|255.000000] "" ICAS1_Gateway
 SG_ MO_Rampenzeit_Generator_Anf  : 72|4@1+ (1.000000,0.000000) [0.000000|15.000000] "" ICAS1_Gateway
 SG_ MO_Prio_MAX_Wunschdrehzahl  : 76|1@1+ (1.000000,0.000000) [0.000000|1.000000] "" ICAS1_Gateway
 SG_ MO_Prio_MIN_Wunschdrehzahl  : 77|1@1+ (1.000000,0.000000) [0.000000|1.000000] "" ICAS1_Gateway
 SG_ MO_Luftpfad_aktiv  : 78|1@1+ (1.000000,0.000000) [0.000000|1.000000] "" ICAS1_Gateway
 SG_ MO_v_Begrenz_Aktivierbar  : 79|1@1+ (1.000000,0.000000) [0.000000|1.000000] "" ICAS1_Gateway
 SG_ MO_Drehzahlbeeinflussung  : 80|8@1+ (0.390000,0.000000) [0.000000|99.450000] "Unit_PerCent" ICAS1_Gateway
 SG_ MO_MIN_Wunschdrehzahl  : 88|8@1+ (25.000000,0.000000) [0.000000|6350.000000] "Unit_MinutInver" ICAS1_Gateway
 SG_ MO_MAX_Wunschdrehzahl  : 96|9@1+ (25.000000,0.000000) [0.000000|12750.000000] "Unit_MinutInver" ICAS1_Gateway
 SG_ MO_Charisma_FahrPr  : 105|4@1+ (1.000000,0.000000) [0.000000|15.000000] "" ICAS1_Gateway
 SG_ MO_Charisma_Status  : 109|2@1+ (1.000000,0.000000) [0.000000|3.000000] "" ICAS1_Gateway
 SG_ MO_StSt_Charisma_FahrPr  : 111|4@1+ (1.000000,0.000000) [0.000000|15.000000] "" ICAS1_Gateway
 SG_ MO_StSt_Charisma_Status  : 115|2@1+ (1.000000,0.000000) [0.000000|3.000000] "" ICAS1_Gateway
 SG_ MO_BZS_Charisma_FahrPr  : 117|4@1+ (1.000000,0.000000) [0.000000|15.000000] "" ICAS1_Gateway
 SG_ MO_BZS_Charisma_Status  : 121|2@1+ (1.000000,0.000000) [0.000000|3.000000] "" ICAS1_Gateway
 SG_ MO_NGS_Position  : 123|1@1+ (1.000000,0.000000) [0.000000|1.000000] "" ICAS1_Gateway
 SG_ MO_NGS_Status  : 124|2@1+ (1.000000,0.000000) [0.000000|3.000000] "" ICAS1_Gateway
 SG_ MO_v_Begrenzung_Niveau  : 126|2@1+ (1.000000,0.000000) [0.000000|3.000000] "" ICAS1_Gateway
 SG_ MO_Anzeige_Rekuperation  : 128|8@1+ (0.500000,-0.500000) [0.000000|100.000000] "Unit_PerCent" ICAS1_Gateway
 SG_ PEA_Fortschrittsanzeige  : 136|7@1+ (1.000000,0.000000) [0.000000|100.000000] "Unit_PerCent" ICAS1_Gateway
 SG_ MO_Anzeige_Fahrbereitschaft  : 143|1@1+ (1.000000,0.000000) [0.000000|1.000000] "" ICAS1_Gateway ICAS1_KommunikationsServer
 SG_ MO_Boost_verfuegbar  : 144|8@1+ (0.400000,-0.400000) [0.000000|100.400000] "Unit_PerCent" ICAS1_Gateway
 SG_ MO_Overboost  : 152|1@1+ (1.000000,0.000000) [0.000000|1.000000] "" ICAS1_Gateway
 SG_ MO_Boost_aktiv  : 153|1@1+ (1.000000,0.000000) [0.000000|1.000000] "" ICAS1_Gateway
 SG_ MO_Anzeige_Betriebsmodus  : 154|4@1+ (1.000000,0.000000) [0.000000|15.000000] "" ICAS1_Gateway
 SG_ PEA_Hinweis  : 158|2@1+ (1.000000,0.000000) [0.000000|3.000000] "" ICAS1_Gateway
 SG_ PEA_Ereignisanzeige  : 160|5@1+ (1.000000,0.000000) [0.000000|31.000000] "" ICAS1_Gateway
 SG_ PEA_Ereignisanzeige_temporaer  : 165|1@1+ (1.000000,0.000000) [0.000000|1.000000] "" ICAS1_Gateway
 SG_ PEA_Abschalttexte  : 166|2@1+ (1.000000,0.000000) [0.000000|3.000000] "" ICAS1_Gateway
 SG_ PEA_Zielgeschw_Einheit  : 168|1@1+ (1.000000,0.000000) [0.000000|1.000000] "" ICAS1_Gateway
 SG_ PEA_Zielgeschw  : 169|5@1+ (1.000000,0.000000) [0.000000|31.000000] "" ICAS1_Gateway
 SG_ MO_Antriebsstrang_Warnung_HS  : 174|2@1+ (1.000000,0.000000) [0.000000|3.000000] "" ICAS1_Gateway
 SG_ MO_Anzeige_Verbrauch_oE  : 176|16@1+ (0.005000,0.000000) [0.000000|327.675000] "Unit_None" ICAS1_Gateway

BO_ 332 Motor_54: 32 Motor_BEV
 SG_ MO_Anforderung_HMS  : 12|3@1+ (1.000000,0.000000) [0.000000|7.000000] "" ICAS1_Gateway
 SG_ FoD_DTC_TSK_GRA  : 15|1@1+ (1.000000,0.000000) [0.000000|1.000000] "" ICAS1_Gateway
 SG_ TSK_vMax_aktuell  : 16|8@1+ (1.000000,0.000000) [0.000000|253.000000] "Unit_KiloMeterPerHour" ICAS1_Gateway
 SG_ TSK_Status_EA  : 32|3@1+ (1.000000,0.000000) [0.000000|7.000000] "" ICAS1_Gateway
 SG_ FoD_DTC_TSK_ACC  : 35|1@1+ (1.000000,0.000000) [0.000000|1.000000] "" ICAS1_Gateway
 SG_ TSK_ACC_FoD_Status  : 36|2@1+ (1.000000,0.000000) [0.000000|3.000000] "" ICAS1_Gateway
 SG_ TSK_GRA_FoD_Status  : 38|2@1+ (1.000000,0.000000) [0.000000|3.000000] "" ICAS1_Gateway
 SG_ TSK_vMax_Fahrerassistenz  : 40|9@1+ (1.000000,0.000000) [0.000000|510.000000] "" ICAS1_Gateway
 SG_ TSK_Einheit_vMax_Fahrerassistenz  : 49|1@1+ (1.000000,0.000000) [0.000000|1.000000] "" ICAS1_Gateway
 SG_ TSK_Status_PLA  : 50|3@1+ (1.000000,0.000000) [0.000000|7.000000] "" ICAS1_Gateway
 SG_ TSK_aktives_System  : 53|3@1+ (1.000000,0.000000) [0.000000|7.000000] "" ICAS1_Gateway
 SG_ TSK_erhoehter_Fahrwiderstand  : 56|1@1+ (1.000000,0.000000) [0.000000|1.000000] "" ICAS1_Gateway
 SG_ TSK_Anf_Antriebsmoment  : 57|1@1+ (1.000000,0.000000) [0.000000|1.000000] "" ICAS1_Gateway
 SG_ TSK_Status_ARA  : 58|3@1+ (1.000000,0.000000) [0.000000|7.000000] "" ICAS1_Gateway
 SG_ TSK_Status_IPA  : 61|3@1+ (1.000000,0.000000) [0.000000|7.000000] "" ICAS1_Gateway
 SG_ MO_Fahrbereitschaft  : 76|2@1+ (1.000000,0.000000) [0.000000|3.000000] "" ICAS1_Gateway LE1 LE2
 SG_ MO_Freilauf_Info  : 78|2@1+ (1.000000,0.000000) [0.000000|3.000000] "" ICAS1_Gateway
 SG_ MO_Krit_Heckobjekt  : 81|3@1+ (1.000000,0.000000) [0.000000|7.000000] "" ICAS1_Gateway
 SG_ MO_NGS_Gangpos  : 84|3@1+ (1.000000,0.000000) [0.000000|7.000000] "" ICAS1_Gateway
 SG_ MO_Freilauf_Status  : 87|3@1+ (1.000000,0.000000) [0.000000|7.000000] "" ICAS1_Gateway
 SG_ MO_EBoost_verf_praed  : 90|2@1+ (1.000000,0.000000) [0.000000|3.000000] "" ICAS1_Gateway
 SG_ MO_Heckspoiler_Anf  : 92|1@1+ (1.000000,0.000000) [0.000000|1.000000] "" ICAS1_Gateway
 SG_ MO_eLaunch_verf  : 93|2@1+ (1.000000,0.000000) [0.000000|3.000000] "" ICAS1_Gateway
 SG_ MO_Positionierung_aktiv  : 95|1@1+ (1.000000,0.000000) [0.000000|1.000000] "" ICAS1_Gateway
 SG_ MO_Freilauf_Typ  : 98|2@1+ (1.000000,0.000000) [0.000000|3.000000] "" ICAS1_Gateway
 SG_ MO_Startwunsch  : 100|1@1+ (1.000000,0.000000) [0.000000|1.000000] "" ICAS1_Gateway
 SG_ OBD_Calc_Load_Val  : 128|8@1+ (0.392157,0.000000) [0.000000|100.000000] "Unit_PerCent" ICAS1_Gateway LE1 LE2
 SG_ OBD_Eng_Cool_Temp  : 136|8@1+ (1.000000,-40.000000) [-40.000000|215.000000] "Unit_DegreCelsi" ICAS1_Gateway LE1 LE2
 SG_ OBD_Abs_Throttle_Pos  : 144|8@1+ (0.392157,0.000000) [0.000000|100.000000] "Unit_PerCent" ICAS1_Gateway LE1 LE2
 SG_ OBD_Abs_Load_Val  : 152|16@1+ (0.392157,0.000000) [0.000000|25700.000000] "Unit_PerCent" ICAS1_Gateway LE1 LE2
 SG_ OBD_Abs_Pedal_Pos  : 168|8@1+ (0.392157,0.000000) [0.000000|100.000000] "Unit_PerCent" ICAS1_Gateway LE1 LE2
 SG_ MO_Servicemodus  : 176|4@1+ (1.000000,0.000000) [0.000000|15.000000] "" ICAS1_Gateway LE1 LE2
 SG_ OBD_ClearMem_Inhibit  : 183|1@1+ (1.000000,0.000000) [0.000000|1.000000] "" ICAS1_Gateway LE1 LE2
 SG_ OBD_Sperrung_Kaltstart_Denom  : 184|1@1+ (1.000000,0.000000) [0.000000|1.000000] "" ICAS1_Gateway LE1 LE2
 SG_ MO_QBit_Aussen_Temp  : 185|1@1+ (1.000000,0.000000) [0.000000|1.000000] "" ICAS1_Gateway
 SG_ OBD_Sperrung_IUMPR  : 186|1@1+ (1.000000,0.000000) [0.000000|1.000000] "" ICAS1_Gateway LE1 LE2
 SG_ OBD_Kaltstart_Denominator  : 187|1@1+ (1.000000,0.000000) [0.000000|1.000000] "" ICAS1_Gateway LE1 LE2
 SG_ OBD_Minimum_Trip  : 188|1@1+ (1.000000,0.000000) [0.000000|1.000000] "" ICAS1_Gateway LE1 LE2
 SG_ OBD_Driving_Cycle  : 189|1@1+ (1.000000,0.000000) [0.000000|1.000000] "" ICAS1_Gateway LE1 LE2
 SG_ OBD_Warm_Up_Cycle  : 190|1@1+ (1.000000,0.000000) [0.000000|1.000000] "" ICAS1_Gateway LE1 LE2
 SG_ OBD_Normed_Trip  : 191|1@1+ (1.000000,0.000000) [0.000000|1.000000] "" ICAS1_Gateway LE1 LE2
 SG_ OBD_Aussen_Temp_gef  : 248|8@1+ (1.000000,-40.000000) [-40.000000|213.000000] "Unit_DegreCelsi" ICAS1_Gateway

BO_ 246 Motor_55: 32 Motor_BEV
 SG_ Motor_55_CRC  : 0|8@1+ (1.000000,0.000000) [0.000000|255.000000] "" ICAS1_Gateway
 SG_ Motor_55_BZ  : 8|4@1+ (1.000000,0.000000) [0.000000|15.000000] "" ICAS1_Gateway
 SG_ TS_Faktor_Radmomente  : 12|2@1+ (1.000000,0.000000) [0.000000|3.000000] "" ICAS1_Gateway
 SG_ TS_Status_MomRad_Ist  : 14|2@1+ (1.000000,0.000000) [0.000000|3.000000] "" ICAS1_Gateway
 SG_ TS_MomRad_verfuegb_maxReku_Summe  : 16|12@1+ (3.000000,-12279.000000) [-12279.000000|0.000000] "" ICAS1_Gateway
 SG_ TS_MomRad_Ist  : 28|13@1+ (3.000000,-12279.000000) [-12279.000000|12279.000000] "Unit_None" ICAS1_Gateway
 SG_ TS_MomRad_Soll_Summe  : 41|13@1+ (3.000000,-12279.000000) [-12279.000000|12279.000000] "Unit_None" ICAS1_Gateway
 SG_ TS_MomRad_Wunsch  : 54|13@1+ (3.000000,-12279.000000) [-12279.000000|12279.000000] "Unit_None" ICAS1_Gateway
 SG_ TS_MomRad_Wunsch_sek  : 67|13@1+ (3.000000,-12279.000000) [-12279.000000|12279.000000] "Unit_None" ICAS1_Gateway
 SG_ TS_MomRad_verfuegb_max  : 80|12@1+ (3.000000,0.000000) [0.000000|12279.000000] "Unit_None" ICAS1_Gateway
 SG_ TS_MomRad_verfuegb_max_sek  : 92|12@1+ (3.000000,0.000000) [0.000000|12279.000000] "Unit_None" ICAS1_Gateway
 SG_ TS_MomRad_verfuegb_maxReku  : 104|12@1+ (3.000000,-12279.000000) [-12279.000000|0.000000] "Unit_None" ICAS1_Gateway
 SG_ TS_MomRad_verfuegb_maxReku_sek  : 116|12@1+ (3.000000,-12279.000000) [-12279.000000|0.000000] "Unit_None" ICAS1_Gateway
 SG_ TS_MomRad_Ist_sek  : 128|13@1+ (3.000000,-12279.000000) [-12279.000000|12279.000000] "Unit_None" ICAS1_Gateway
 SG_ TS_Allrad_Anteil_sek  : 141|9@1+ (0.200000,0.000000) [0.000000|100.000000] "Unit_PerCent" ICAS1_Gateway
 SG_ FDR_Allrad_Anteil_max_sek  : 150|9@1+ (0.200000,0.000000) [0.000000|100.000000] "Unit_PerCent" ICAS1_Gateway
 SG_ FDR_Allrad_Anteil_min_sek  : 159|9@1+ (0.200000,0.000000) [0.000000|100.000000] "Unit_PerCent" ICAS1_Gateway
 SG_ FDR_MomRad_Eingriff  : 168|13@1+ (3.000000,-12279.000000) [-12279.000000|12279.000000] "Unit_NewtoMeter" ICAS1_Gateway
 SG_ FDR_Status_Eingriff  : 181|1@1+ (1.000000,0.000000) [0.000000|1.000000] "" ICAS1_Gateway
 SG_ FDR_MomRad_Eingriff_sek  : 182|13@1+ (3.000000,-12279.000000) [-12279.000000|12279.000000] "Unit_NewtoMeter" ICAS1_Gateway
 SG_ FDR_Status_Eingriff_sek  : 195|1@1+ (1.000000,0.000000) [0.000000|1.000000] "" ICAS1_Gateway
